AUTOSAR XML (schema 00047)
standard types defined: boolean, uint16, uint32, uint8
package /Application/AdaptiveApplicationSwComponentTypes
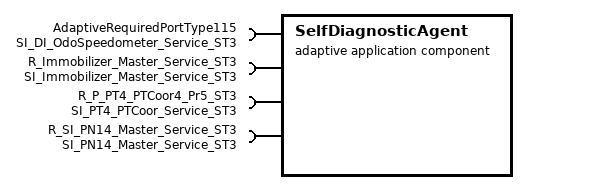
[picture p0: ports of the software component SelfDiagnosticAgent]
  adaptive application sw component type SelfDiagnosticAgent
    4 x require port:
      AdaptiveRequiredPortType115: required-interface=SI_DI_OdoSpeedometer_Service_ST3
      R_Immobilizer_Master_Service_ST3: required-interface=SI_Immobilizer_Master_Service_ST3
      R_P_PT4_PTCoor4_Pr5_ST3: required-interface=SI_PT4_PTCoor_Service_ST3
      R_SI_PN14_Master_Service_ST3: required-interface=SI_PN14_Master_Service_ST3
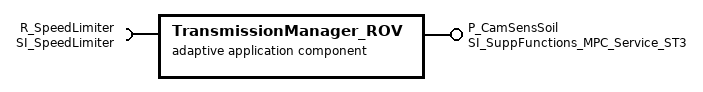
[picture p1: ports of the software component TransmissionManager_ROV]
  adaptive application sw component type TransmissionManager_ROV
    provide port P_CamSensSoil: provided-interface=SI_SuppFunctions_MPC_Service_ST3
    require port R_SpeedLimiter: required-interface=SI_SpeedLimiter
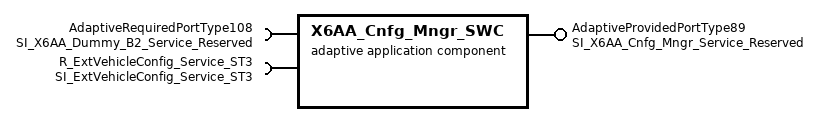
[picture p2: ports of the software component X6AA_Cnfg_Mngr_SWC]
  adaptive application sw component type X6AA_Cnfg_Mngr_SWC
    provide port AdaptiveProvidedPortType89: provided-interface=SI_X6AA_Cnfg_Mngr_Service_Reserved
    require port AdaptiveRequiredPortType108: required-interface=SI_X6AA_Dummy_B2_Service_Reserved
    require port R_ExtVehicleConfig_Service_ST3: required-interface=SI_ExtVehicleConfig_Service_ST3
  adaptive application sw component type X6AA_DLT_SWC
  adaptive application sw component type X6AA_Dummy_SWC_1
    require port AdaptiveRequiredPortType110: required-interface=SI_X6AA_Cnfg_Mngr_Service_Reserved
  adaptive application sw component type X6AA_Dummy_SWC_2
    provide port AdaptiveProvidedPortType90: provided-interface=SI_X6AA_Dummy_B2_Service_Reserved
  adaptive application sw component type X6AA_Ressource_SWC
package /Application/Executables
  7 x executable, all with category=APPLICATION_LEVEL, build-type=BUILD-TYPE-DEBUG, version=1.00.00.0000:
    SelfDiagnosticAgentExecutable
      root sw component prototype SelfDiagnosticAgentExecutableRootSwc: application-type=SelfDiagnosticAgent
    TransmissionManager_ROVExecutable
      root sw component prototype TransmissionManager_ROVExecutableRootSwc: application-type=TransmissionManager_ROV
    X6AA_Cnfg_Mngr_Executable
      root sw component prototype X6AA_Cnfg_Mngr_ExecutableRootSwc: application-type=X6AA_Cnfg_Mngr_SWC
    X6AA_DLT_Executable
      root sw component prototype X6AA_DLT_ExecutableRootSwc: application-type=X6AA_DLT_SWC
    X6AA_Dummy_SWC_1_Executable
      root sw component prototype X6AA_Dummy_SWC_1_ExecutableRootSwc: application-type=X6AA_Dummy_SWC_1
    X6AA_Dummy_SWC_2_Executable
      root sw component prototype X6AA_Dummy_SWC_2_ExecutableRootSwc: application-type=X6AA_Dummy_SWC_2
    X6AA_Ressource_Executable
      root sw component prototype X6AA_Ressource_ExecutableRootSwc: application-type=X6AA_Ressource_SWC
package /ApplicationDeployment/Processes
  7 x process, all with state-dependent-startup-config{function-group-state=MachineState.Running, startup-config=STARTUP_CONFIG_DEFAULT}:
    Process_X6AA_Cnfg_Mngr_SWC: executable=X6AA_Cnfg_Mngr_Executable
      process state machine MDGE_Process_X6AA_Cnfg_Mngr_SWC: type=MachineStates
    Process_X6AA_DLT_SWC: executable=X6AA_DLT_Executable
      process state machine MDGE_Process_X6AA_DLT_SWC: type=MachineStates
    Process_X6AA_Dummy_SWC_1: executable=X6AA_Dummy_SWC_1_Executable
      process state machine MDGE_Process_X6AA_Dummy_SWC_1: type=MachineStates
    Process_X6AA_Dummy_SWC_2: executable=X6AA_Dummy_SWC_2_Executable
      process state machine MDGE_Process_X6AA_Dummy_SWC_2: type=MachineStates
    Process_X6AA_Ressource_SWC: executable=X6AA_Ressource_Executable
      process state machine MDGE_Process_X6AA_Ressource_SWC: type=MachineStates
    SelfDiagnosticAgent: executable=SelfDiagnosticAgentExecutable
      process state machine MDGE_SelfDiagnosticAgent: type=MachineStates
    TransmissionManager_ROV: executable=TransmissionManager_ROVExecutable
      process state machine ProcessStateMachine_BaseApplication: type=MachineStates
package /ApplicationDeployment/ProcessDesigns
  7 x process design:
    ProcessDesign_X6AA_Cnfg_Mngr_SWC: executable=X6AA_Cnfg_Mngr_Executable
    ProcessDesign_X6AA_Dummy_SWC_1: executable=X6AA_Dummy_SWC_1_Executable
    ProcessDesign__X6AA_Dummy_SWC_2: executable=X6AA_Dummy_SWC_2_Executable
    ProcessDesign_SelfDiagnosticAgent: executable=SelfDiagnosticAgentExecutable
    ProcessDesign_TransmissionManager_ROV: executable=TransmissionManager_ROVExecutable
    ProcessDesign_X6AA_DLT_SWC: executable=X6AA_DLT_Executable
    ProcessDesign_X6AA_Ressource_SWC: executable=X6AA_Ressource_Executable
package /Communication/PDUs
  pdu CamSensSoil_MPC_ST3: length=1, unused-bit-pattern=255  # Cam Sens Soil MPC ST3
    signal CamSensSoil_CMS_IconDisp_Rq_MPC_ST3: start 0, 1 bit, little-endian, data-type-policy=OVERRIDE, i-signal-type=PRIMITIVE, compu {0=I_C01_CAMSENSSOIL_CMS_ICONDISP_RQ_IDLE (IDLE) (No display request), 1=I_C01_CAMSENSSOIL_CMS_ICONDISP_RQ_MSG_RQ_CAM_SOILED_CMS_NA (MSG_RQ_CAM_SOILED_CMS_NA) (Message request Camera soiled CMS not available)}, range raw 0..1 "01_CamSensSoil_CMS_IconDisp_Rq"  # Camera Soiled, CMS not available Icon
    signal CamSensSoil_IHC_IconDisp_Rq_MPC_ST3: start 1, 1 bit, little-endian, data-type-policy=OVERRIDE, i-signal-type=PRIMITIVE, compu {0=I_C01_CAMSENSSOIL_IHC_ICONDISP_RQ_IDLE (IDLE) (No display request), 1=I_C01_CAMSENSSOIL_IHC_ICONDISP_RQ_MSG_RQ_CAM_SOILED_IHC_NA (MSG_RQ_CAM_SOILED_IHC_NA) (Message request Camera soiled IHC not available)}, range raw 0..1 "01_CamSensSoil_IHC_IconDisp_Rq"  # Camera Soiled, IHC not available Icon
    signal CamSensSoil_LDP_IconDisp_Rq_MPC_ST3: start 2, 1 bit, little-endian, data-type-policy=OVERRIDE, i-signal-type=PRIMITIVE, compu {0=I_C01_CAMSENSSOIL_LDP_ICONDISP_RQ_IDLE (IDLE) (No display request), 1=I_C01_CAMSENSSOIL_LDP_ICONDISP_RQ_MSG_RQ_CAM_SOILED_LDP_NA (MSG_RQ_CAM_SOILED_LDP_NA) (Message request Camera soiled LDP not available)}, range raw 0..1 "01_CamSensSoil_LDP_IconDisp_Rq"  # Camera Soiled, LDP not available Icon
    signal CamSensSoil_MsgDisp_Rq_MPC_ST3: start 3, 1 bit, little-endian, data-type-policy=OVERRIDE, i-signal-type=PRIMITIVE, compu {0=I_C01_CAMSENSSOIL_MSGDISP_RQ_IDLE (IDLE) (No display request), 1=I_C01_CAMSENSSOIL_MSGDISP_RQ_MSG_RQ_CAM_SOILED (MSG_RQ_CAM_SOILED) (Message request Camera Soiled)}, range raw 0..1 "01_CamSensSoil_MsgDisp_Rq"  # Message "Camera Soiled" with Icons
    signal CamSensSoil_TSA_IconDisp_Rq_MPC_ST3: start 4, 1 bit, little-endian, data-type-policy=OVERRIDE, i-signal-type=PRIMITIVE, compu {0=I_C01_CAMSENSSOIL_TSA_ICONDISP_RQ_IDLE (IDLE) (No display request), 1=I_C01_CAMSENSSOIL_TSA_ICONDISP_RQ_MSG_RQ_CAM_SOILED_TSA_NA (MSG_RQ_CAM_SOILED_TSA_NA) (Message request Camera soiled TSA not available)}, range raw 0..1 "01_CamSensSoil_TSA_IconDisp_Rq"  # Camera Soiled,TSA not available Icon
    mapping CamSensSoil_MPC_ST3_arrjrmhd69107z3r1gztlanxq: i-signal-group=CamSensSoil_MPC_ST3_arrjrmhd69107z3r1gztlanxq, transfer-property=PENDING
    mapping CarWashMd_MPC_SMPC_Stat_ST3: transfer-property=PENDING
  pdu DAP_StWhl_Ctrl_ST3: length=8, minimum-delay=0.02, unused-bit-pattern=255  # DriverAssistancePackage Steering Wheel Controls
    signal CRC_StWhl_Sw_CruiseCtrl_VSL_Stat_Pr5_ST3: start 0, 16 bit, little-endian, data-type-policy=OVERRIDE, i-signal-type=PRIMITIVE, base-type=uint16, range raw 0..65535 "16_CRC_w/oSNA", transfer-property=PENDING  # CRC-checksum of signal group according to AUTOSAR Profile 5
    signal SQC_StWhl_Sw_CruiseCtrl_VSL_Stat_Pr5_ST3: start 16, 8 bit, little-endian, data-type-policy=OVERRIDE, i-signal-type=PRIMITIVE, base-type=uint8, compu {identical}, range phys 0..255 "08_0-255_1_SNA=-", transfer-property=PENDING  # Sequence counter
    signal StWhl_Sw_CruiseCtrl_Select_Psd_ST3: start 24, 2 bit, little-endian, data-type-policy=OVERRIDE, i-signal-type=PRIMITIVE, base-type=uint8, invalid-value=3, compu-method=c02_NPsd_Psd_Flt, range raw 0..3 "02_NPsd_Psd_Flt", transfer-property=TRIGGERED-ON-CHANGE  # Steering wheel tip switch "Cruise Control selected" pressed
    signal StWhl_Sw_VSL_Select_Psd_ST3: start 26, 2 bit, little-endian, data-type-policy=OVERRIDE, i-signal-type=PRIMITIVE, base-type=uint8, invalid-value=3, compu-method=c02_NPsd_Psd_Flt, range raw 0..3 "02_NPsd_Psd_Flt", transfer-property=TRIGGERED-ON-CHANGE  # Steering wheel tip switch "Variable Speed Limiter selected" switch pressed
    signal StWhl_Sw_CruiseCtrl_Off_Psd_ST3: start 28, 2 bit, little-endian, data-type-policy=OVERRIDE, i-signal-type=PRIMITIVE, base-type=uint8, invalid-value=3, compu-method=c02_NPsd_Psd_Flt, range raw 0..3 "02_NPsd_Psd_Flt", transfer-property=TRIGGERED-ON-CHANGE  # Steering wheel tip switch "Cruise Control off" pressed
    signal StWhl_Sw_VSL_Off_Psd_ST3: start 30, 2 bit, little-endian, data-type-policy=OVERRIDE, i-signal-type=PRIMITIVE, base-type=uint8, invalid-value=3, compu-method=c02_NPsd_Psd_Flt, range raw 0..3 "02_NPsd_Psd_Flt", transfer-property=TRIGGERED-ON-CHANGE  # Steering wheel tip switch "Variable Speed Limiter off" pressed
    signal StWhl_Sw_Mode_Psd_ST3: start 32, 2 bit, little-endian, data-type-policy=OVERRIDE, i-signal-type=PRIMITIVE, base-type=uint8, invalid-value=3, compu-method=c02_NPsd_Psd_Flt, range raw 0..3 "02_NPsd_Psd_Flt", transfer-property=TRIGGERED-ON-CHANGE  # Steering wheel tip switch Mode pressed
    signal StWhl_Sw_Resume_Psd_ST3: start 34, 2 bit, little-endian, data-type-policy=OVERRIDE, i-signal-type=PRIMITIVE, base-type=uint8, invalid-value=3, compu-method=c02_NPsd_Psd_Flt, range raw 0..3 "02_NPsd_Psd_Flt", transfer-property=TRIGGERED-ON-CHANGE  # Steering wheel tip switch Resume pressed
    signal StWhl_Sw_Cancel_Psd_ST3: start 36, 2 bit, little-endian, data-type-policy=OVERRIDE, i-signal-type=PRIMITIVE, base-type=uint8, invalid-value=3, compu-method=c02_NPsd_Psd_Flt, range raw 0..3 "02_NPsd_Psd_Flt", transfer-property=TRIGGERED-ON-CHANGE  # Steering wheel tip switch Cancel pressed
    signal StWhl_Sw_Dist_Tgl_Psd_ST3: start 38, 2 bit, little-endian, data-type-policy=OVERRIDE, i-signal-type=PRIMITIVE, base-type=uint8, invalid-value=3, compu-method=c02_NPsd_Psd_Flt, range raw 0..3 "02_NPsd_Psd_Flt", transfer-property=TRIGGERED-ON-CHANGE  # Steering wheel tip switch Distance Toggle pressed
    signal StWhl_Sw_Dist_Plus_Psd_ST3: start 40, 2 bit, little-endian, data-type-policy=OVERRIDE, i-signal-type=PRIMITIVE, base-type=uint8, invalid-value=3, compu-method=c02_NPsd_Psd_Flt, range raw 0..3 "02_NPsd_Psd_Flt", transfer-property=TRIGGERED-ON-CHANGE  # Steering wheel tip switch Distance Plus pressed
    signal StWhl_Sw_Dist_Minus_Psd_ST3: start 42, 2 bit, little-endian, data-type-policy=OVERRIDE, i-signal-type=PRIMITIVE, base-type=uint8, invalid-value=3, compu-method=c02_NPsd_Psd_Flt, range raw 0..3 "02_NPsd_Psd_Flt", transfer-property=TRIGGERED-ON-CHANGE  # Steering wheel tip switch Mode pressed
    signal StWhl_Sw_Up10_Set_Psd_ST3: start 44, 2 bit, little-endian, data-type-policy=OVERRIDE, i-signal-type=PRIMITIVE, base-type=uint8, invalid-value=3, compu-method=c02_NPsd_Psd_Flt, range raw 0..3 "02_NPsd_Psd_Flt", transfer-property=TRIGGERED-ON-CHANGE  # Steering wheel tip switch Set Speed 10 Up pressed
    signal StWhl_Sw_Up1_Psd_ST3: start 46, 2 bit, little-endian, data-type-policy=OVERRIDE, i-signal-type=PRIMITIVE, base-type=uint8, invalid-value=3, compu-method=c02_NPsd_Psd_Flt, range raw 0..3 "02_NPsd_Psd_Flt", transfer-property=TRIGGERED-ON-CHANGE  # Steering wheel tip switch "+1" pressed
    signal StWhl_Sw_Dn1_Psd_ST3: start 48, 2 bit, little-endian, data-type-policy=OVERRIDE, i-signal-type=PRIMITIVE, base-type=uint8, invalid-value=3, compu-method=c02_NPsd_Psd_Flt, range raw 0..3 "02_NPsd_Psd_Flt", transfer-property=TRIGGERED-ON-CHANGE  # Steering wheel tip switch "-1" pressed
    signal StWhl_Sw_Dn10_Set_Psd_ST3: start 50, 2 bit, little-endian, data-type-policy=OVERRIDE, i-signal-type=PRIMITIVE, base-type=uint8, invalid-value=3, compu-method=c02_NPsd_Psd_Flt, range raw 0..3 "02_NPsd_Psd_Flt", transfer-property=TRIGGERED-ON-CHANGE  # Steering wheel tip switch Set Speed 10 Down pressed
    signal StWhl_Sw_HAD1_Psd_ST3: start 52, 2 bit, little-endian, data-type-policy=OVERRIDE, i-signal-type=PRIMITIVE, base-type=uint8, invalid-value=3, compu-method=c02_NPsd_Psd_Flt, range raw 0..3 "02_NPsd_Psd_Flt", transfer-property=TRIGGERED-ON-CHANGE  # Steering wheel tip switch HAD1 pressed
    signal StWhl_Sw_HAD2_Psd_ST3: start 54, 2 bit, little-endian, data-type-policy=OVERRIDE, i-signal-type=PRIMITIVE, base-type=uint8, invalid-value=3, compu-method=c02_NPsd_Psd_Flt, range raw 0..3 "02_NPsd_Psd_Flt", transfer-property=TRIGGERED-ON-CHANGE  # Steering wheel tip switch HAD2 pressed
    signal StWhl_Sw_Up1Dn1_StepSize_ST3: start 56, 3 bit, little-endian, data-type-policy=OVERRIDE, i-signal-type=PRIMITIVE, base-type=uint8, invalid-value=7, compu {0=I_CSTWHL_SW_UP1DN1_STEPSIZE_ST3_STEP_SIZE_1 (STEP_SIZE_1) (StepSize=1), 1=I_CSTWHL_SW_UP1DN1_STEPSIZE_ST3_STEP_SIZE_2 (STEP_SIZE_2) (StepSize Level 2), 2=I_CSTWHL_SW_UP1DN1_STEPSIZE_ST3_STEP_SIZE_3 (STEP_SIZE_3) (StepSize Level 3), 3=I_CSTWHL_SW_UP1DN1_STEPSIZE_ST3_STEP_SIZE_4 (STEP_SIZE_4) (StepSize Level 4), 4=I_CSTWHL_SW_UP1DN1_STEPSIZE_ST3_STEP_SIZE_5 (STEP_SIZE_5) (StepSize Level 5), 7=I_CSTWHL_SW_UP1DN1_STEPSIZE_ST3_SNA (SNA) (SNA value from data type)}, range raw 0..7 "03_StWhl_Sw_Up1Dn1_StepSize_ST3", transfer-property=PENDING  # Step size switch “+/-1”
    signal Rsrv1_StWhl_Sw_CruiseCtrl_VSL_Stat_Pr5_ST3: start 59, 5 bit, little-endian, data-type-policy=OVERRIDE, i-signal-type=PRIMITIVE, base-type=uint8, invalid-value=31, range raw 0..31, transfer-property=PENDING  # Reserved for future use
    mapping StWhl_Sw_CruiseCtrl_VSL_Stat_Pr5_ST3: i-signal-group=StWhl_Sw_CruiseCtrl_VSL_Stat_Pr5_ST3, transfer-property=TRIGGERED-ON-CHANGE
  pdu DI_OdoSpeedometer_ST3: length=8, minimum-delay=0.1, unused-bit-pattern=255  # DriverInformation Odometer and speedometer
    signal Odo_ST3: start 24, 24 bit, little-endian, data-type-policy=OVERRIDE, i-signal-type=PRIMITIVE, base-type=uint32, invalid-value=16777215, compu {phys=raw*0.1 for raw 0..9999999, 16777214=I_C24_KM_0_999999K9_0K1_INVLD_SNA_INVLD (INVLD) (Invalid), 16777215=I_C24_KM_0_999999K9_0K1_INVLD_SNA_SNA (SNA) (SNA value from data type); unit km}, range phys 0..1677721.5, raw 0..16777215 "24_km_0-999999,9_0,1_Invld_SNA", to IDC_Adpative  # Odometer (for everyone)
    mapping CRC_DI_Odo_Pr5_ST3: transfer-property=PENDING
    mapping DI_Odo_Pr5_ST3_e68xmtlkywxgxsdwekdjjhw3t: i-signal-group=DI_Odo_Pr5_ST3_e68xmtlkywxgxsdwekdjjhw3t, transfer-property=TRIGGERED-ON-CHANGE
    mapping SQC_DI_Odo_Pr5_ST3: transfer-property=PENDING
    mapping VehSpd_Disp_ST3: transfer-property=TRIGGERED-ON-CHANGE
  pdu EVC_CfgBit_01_26_Pr5_ST3: length=8, unused-bit-pattern=255  # EVC-CfgMessage[Bitfield:01h-26h]
    signal CRC_EVC_CfgBit_01_26_Pr5_ST3: start 0, 16 bit, little-endian, data-type-policy=OVERRIDE, i-signal-type=PRIMITIVE, data-constr=c16_CRC_woSNA, to IDC_Adpative  # CRC-checksum of signal group according to AUTOSAR Profile 5
    signal SQC_EVC_CfgBit_01_26_Pr5_ST3: start 16, 8 bit, little-endian, data-type-policy=OVERRIDE, i-signal-type=PRIMITIVE, compu {identical}, data-constr=c08_0_255_1_SNA_na, to IDC_Adpative  # Sequence counter
    signal EVC_CfgBit_01_26_Stat_ST3: start 24, 2 bit, little-endian, data-type-policy=OVERRIDE, i-signal-type=PRIMITIVE, invalid-value=3, compu-method=c02_EVC_Stat, data-constr=c02_EVC_Stat, to IDC_Adpative  # Status EVC-CfgMessage[Bitfield:01h-26h]
    signal EVC_01_494_Avl_ST3: start 26, 1 bit, little-endian, data-type-policy=OVERRIDE, i-signal-type=PRIMITIVE, to IDC_Adpative  # 494 VERSION FOR USA
    signal EVC_02_498_Avl_ST3: start 27, 1 bit, little-endian, data-type-policy=OVERRIDE, i-signal-type=PRIMITIVE, to IDC_Adpative  # 498 VERSION FOR JAPAN
    signal EVC_03_623_Avl_ST3: start 28, 1 bit, little-endian, data-type-policy=OVERRIDE, i-signal-type=PRIMITIVE, to IDC_Adpative  # 623 VERSION FOR GULF STATES
    signal EVC_04_625_Avl_ST3: start 29, 1 bit, little-endian, data-type-policy=OVERRIDE, i-signal-type=PRIMITIVE, to IDC_Adpative  # 625 VERSION FOR AUSTRALIA
    signal EVC_05_830_Avl_ST3: start 30, 1 bit, little-endian, data-type-policy=OVERRIDE, i-signal-type=PRIMITIVE, to IDC_Adpative  # 830 VEHICLES FOR CHINA-ADDITIONAL PARTS
    signal EVC_06_835_Avl_ST3: start 31, 1 bit, little-endian, data-type-policy=OVERRIDE, i-signal-type=PRIMITIVE, to IDC_Adpative  # 835 SOUTHERN KOREA-SUPPLEMENTARY PARTS
    signal EVC_07_460_Avl_ST3: start 32, 1 bit, little-endian, data-type-policy=OVERRIDE, i-signal-type=PRIMITIVE, to IDC_Adpative  # 460 VEHICLES FOR CANADA, ADDITIONAL PARTS
    signal EVC_08_AddEquip_Avl_ST3: start 33, 1 bit, little-endian, data-type-policy=OVERRIDE, i-signal-type=PRIMITIVE, to IDC_Adpative  # 08h Additional Equipment (not specialized yet)
    signal EVC_09_AddEquip_Avl_ST3: start 34, 1 bit, little-endian, data-type-policy=OVERRIDE, i-signal-type=PRIMITIVE, to IDC_Adpative  # 09h Additional Equipment (not specialized yet)
    signal EVC_0A_AddEquip_Avl_ST3: start 35, 1 bit, little-endian, data-type-policy=OVERRIDE, i-signal-type=PRIMITIVE, to IDC_Adpative  # 0Ah Additional Equipment (not specialized yet)
    signal EVC_0B_AddEquip_Avl_ST3: start 36, 1 bit, little-endian, data-type-policy=OVERRIDE, i-signal-type=PRIMITIVE, to IDC_Adpative  # 0Bh Additional Equipment (not specialized yet)
    signal EVC_0C_465_Avl_ST3: start 37, 1 bit, little-endian, data-type-policy=OVERRIDE, i-signal-type=PRIMITIVE, to IDC_Adpative  # 465 ELEKTRIK AKTIV ROLL STABILISATION (EARS)
    signal EVC_0D_470_Avl_ST3: start 38, 1 bit, little-endian, data-type-policy=OVERRIDE, i-signal-type=PRIMITIVE, to IDC_Adpative  # 470 SEMI-ACTIVE ROLL STABILIZATION
    signal EVC_0E_479_Avl_ST3: start 39, 1 bit, little-endian, data-type-policy=OVERRIDE, i-signal-type=PRIMITIVE, to IDC_Adpative  # 479 ADJUSTING SUSPENSION
    signal EVC_0F_AddEquip_Avl_ST3: start 40, 1 bit, little-endian, data-type-policy=OVERRIDE, i-signal-type=PRIMITIVE, to IDC_Adpative  # 0Fh Additional Equipment (not specialized yet)
    signal EVC_10_AddEquip_Avl_ST3: start 41, 1 bit, little-endian, data-type-policy=OVERRIDE, i-signal-type=PRIMITIVE, to IDC_Adpative  # 10h Additional Equipment (not specialized yet)
    signal EVC_11_AddEquip_Avl_ST3: start 42, 1 bit, little-endian, data-type-policy=OVERRIDE, i-signal-type=PRIMITIVE, to IDC_Adpative  # 11h Additional Equipment (not specialized yet)
    signal EVC_12_AddEquip_Avl_ST3: start 43, 1 bit, little-endian, data-type-policy=OVERRIDE, i-signal-type=PRIMITIVE, to IDC_Adpative  # 12h Additional Equipment (not specialized yet)
    signal EVC_13_AddEquip_Avl_ST3: start 44, 1 bit, little-endian, data-type-policy=OVERRIDE, i-signal-type=PRIMITIVE, to IDC_Adpative  # 13h Additional Equipment (not specialized yet)
    signal EVC_14_M035_Avl_ST3: start 45, 1 bit, little-endian, data-type-policy=OVERRIDE, i-signal-type=PRIMITIVE, to IDC_Adpative  # M035 ALLROAD-VARIANT
    signal EVC_15_MED2_Avl_ST3: start 46, 1 bit, little-endian, data-type-policy=OVERRIDE, i-signal-type=PRIMITIVE, to IDC_Adpative  # MED2 UPPER-MID-VARIANTE MIT M-BATTERIE
    signal EVC_16_M013_Avl_ST3: start 47, 1 bit, little-endian, data-type-policy=OVERRIDE, i-signal-type=PRIMITIVE, to IDC_Adpative  # M013 ENGINE REDUCED PERFORMANCE
    signal EVC_17_M014_Avl_ST3: start 48, 1 bit, little-endian, data-type-policy=OVERRIDE, i-signal-type=PRIMITIVE, to IDC_Adpative  # M014 ENGINE INCREASED PERFORMANCE
    signal EVC_18_M016_Avl_ST3: start 49, 1 bit, little-endian, data-type-policy=OVERRIDE, i-signal-type=PRIMITIVE, to IDC_Adpative  # M016 ENGINE HIGH PERFORMANCE INCREASED
    signal EVC_19_M005_Avl_ST3: start 50, 1 bit, little-endian, data-type-policy=OVERRIDE, i-signal-type=PRIMITIVE, to IDC_Adpative  # M005 CHASSIS WITH 4-MATIC-/ALL-WHEEL DRIVE
    signal EVC_1A_AddEquip_Avl_ST3: start 51, 1 bit, little-endian, data-type-policy=OVERRIDE, i-signal-type=PRIMITIVE, to IDC_Adpative  # 1Ah Additional Equipment (not specialized yet)
    signal EVC_1B_MEF2_Avl_ST3: start 52, 1 bit, little-endian, data-type-policy=OVERRIDE, i-signal-type=PRIMITIVE, to IDC_Adpative  # MEF2 AMG-ENTRY-VARIANTE MIT M-BATTERIE + 4MATIC
    signal EVC_1C_MEF3_Avl_ST3: start 53, 1 bit, little-endian, data-type-policy=OVERRIDE, i-signal-type=PRIMITIVE, to IDC_Adpative  # MEF3 AMG-ENTRY-VARIANTE MIT L-BATTERIE + 4MATIC
    signal EVC_1D_201_Avl_ST3: start 54, 1 bit, little-endian, data-type-policy=OVERRIDE, i-signal-type=PRIMITIVE, to IDC_Adpative  # 201 REAR AXLE STEERING
    signal EVC_1E_216_Avl_ST3: start 55, 1 bit, little-endian, data-type-policy=OVERRIDE, i-signal-type=PRIMITIVE, to IDC_Adpative  # 216 REAR AXLE STEERING WITH LARGE ANGLE
    signal EVC_1F_215_Avl_ST3: start 56, 1 bit, little-endian, data-type-policy=OVERRIDE, i-signal-type=PRIMITIVE, to IDC_Adpative  # 215 ADAPTIVE DAMPING SYSTEM PLUS (ADS+)
    signal EVC_20_487_Avl_ST3: start 57, 1 bit, little-endian, data-type-policy=OVERRIDE, i-signal-type=PRIMITIVE, to IDC_Adpative  # 487 ABC-SPRING (ACTIVE BODY CONTROL)
    signal EVC_21_488_Avl_ST3: start 58, 1 bit, little-endian, data-type-policy=OVERRIDE, i-signal-type=PRIMITIVE, to IDC_Adpative  # 488 CHASSIS WITH STEEL-/AIR SUSPENSION
    signal EVC_22_489_Avl_ST3: start 59, 1 bit, little-endian, data-type-policy=OVERRIDE, i-signal-type=PRIMITIVE, to IDC_Adpative  # 489 AIRMATIC DUAL CONTROL / AIR SUSPENSION SEMI-ACTIVE
    signal EVC_23_490_Avl_ST3: start 60, 1 bit, little-endian, data-type-policy=OVERRIDE, i-signal-type=PRIMITIVE, to IDC_Adpative  # 490 ELEKTROHYDRAULISCHE FEDERUNG
    signal EVC_24_486_Avl_ST3: start 61, 1 bit, little-endian, data-type-policy=OVERRIDE, i-signal-type=PRIMITIVE, to IDC_Adpative  # 486 SPORTS SUSPENSION
    signal EVC_25_AddEquip_Avl_ST3: start 62, 1 bit, little-endian, data-type-policy=OVERRIDE, i-signal-type=PRIMITIVE, to IDC_Adpative  # 25h Additional Equipment (not specialized yet)
    signal EVC_26_459_Avl_ST3: start 63, 1 bit, little-endian, data-type-policy=OVERRIDE, i-signal-type=PRIMITIVE, to IDC_Adpative  # 459 STEEL SPRING WITH ADJUSTABLE INSULATION
    mapping EVC_CfgBit_01_26_Pr5_ST3_fblv727rnlh4ltr0dm5mnkvh: i-signal-group=EVC_CfgBit_01_26_Pr5_ST3_fblv727rnlh4ltr0dm5mnkvh, transfer-property=PENDING
  pdu EVC_CfgBit_73_98_Pr5_ST3: length=8, unused-bit-pattern=255  # EVC-CfgMessage[Bitfield:73h-98h]
    signal CRC_EVC_CfgBit_73_98_Pr5_ST3: start 0, 16 bit, little-endian, data-type-policy=OVERRIDE, i-signal-type=PRIMITIVE, data-constr=c16_CRC_woSNA, to IDC_Adpative  # CRC-checksum of signal group according to AUTOSAR Profile 5
    signal SQC_EVC_CfgBit_73_98_Pr5_ST3: start 16, 8 bit, little-endian, data-type-policy=OVERRIDE, i-signal-type=PRIMITIVE, compu {identical}, data-constr=c08_0_255_1_SNA_na, to IDC_Adpative  # Sequence counter
    signal EVC_CfgBit_73_98_Stat_ST3: start 24, 2 bit, little-endian, data-type-policy=OVERRIDE, i-signal-type=PRIMITIVE, invalid-value=3, compu-method=c02_EVC_Stat, data-constr=c02_EVC_Stat, to IDC_Adpative  # Status EVC-CfgMessage[Bitfield:73h-98h]
    signal EVC_73_501_Avl_ST3: start 26, 1 bit, little-endian, data-type-policy=OVERRIDE, i-signal-type=PRIMITIVE, to IDC_Adpative  # 501 SURROUND VIEW SYSTEM
    signal EVC_74_476_Avl_ST3: start 27, 1 bit, little-endian, data-type-policy=OVERRIDE, i-signal-type=PRIMITIVE, to IDC_Adpative  # 476 AUTO. LANE RECOGNITION (CONDITION ASSISTENT)
    signal EVC_75_AddEquip_Avl_ST3: start 28, 1 bit, little-endian, data-type-policy=OVERRIDE, i-signal-type=PRIMITIVE, to IDC_Adpative  # 75h Additional Equipment (not specialized yet)
    signal EVC_76_513_Avl_ST3: start 29, 1 bit, little-endian, data-type-policy=OVERRIDE, i-signal-type=PRIMITIVE, to IDC_Adpative  # 513 ROAD SIGN DETECTION (SLA)
    signal EVC_77_299_Avl_ST3: start 30, 1 bit, little-endian, data-type-policy=OVERRIDE, i-signal-type=PRIMITIVE, to IDC_Adpative  # 299 PRESAFE
    signal EVC_78_306_Avl_ST3: start 31, 1 bit, little-endian, data-type-policy=OVERRIDE, i-signal-type=PRIMITIVE, to IDC_Adpative  # 306 REAR BELTBAG
    signal EVC_79_AddEquip_Avl_ST3: start 32, 1 bit, little-endian, data-type-policy=OVERRIDE, i-signal-type=PRIMITIVE, to IDC_Adpative  # 79h Additional Equipment (not specialized yet)
    signal EVC_7A_AddEquip_Avl_ST3: start 33, 1 bit, little-endian, data-type-policy=OVERRIDE, i-signal-type=PRIMITIVE, to IDC_Adpative  # 7Ah Additional Equipment (not specialized yet)
    signal EVC_7B_551_Avl_ST3: start 34, 1 bit, little-endian, data-type-policy=OVERRIDE, i-signal-type=PRIMITIVE, to IDC_Adpative  # 551 THEFT WARNING SYSTEM
    signal EVC_7C_503_Avl_ST3: start 35, 1 bit, little-endian, data-type-policy=OVERRIDE, i-signal-type=PRIMITIVE, to IDC_Adpative  # 503 REMOTE PARKING
    signal EVC_7D_220_Avl_ST3: start 36, 1 bit, little-endian, data-type-policy=OVERRIDE, i-signal-type=PRIMITIVE, to IDC_Adpative  # 220 PARKTRONIC SYSTEM (PTS)
    signal EVC_7E_218_Avl_ST3: start 37, 1 bit, little-endian, data-type-policy=OVERRIDE, i-signal-type=PRIMITIVE, to IDC_Adpative  # 218 REVERSING CAMERA
    signal EVC_7F_235_Avl_ST3: start 38, 1 bit, little-endian, data-type-policy=OVERRIDE, i-signal-type=PRIMITIVE, to IDC_Adpative  # 235 ACTIVE PARKING ASSISTANCE
    signal EVC_80_AddEquip_Avl_ST3: start 39, 1 bit, little-endian, data-type-policy=OVERRIDE, i-signal-type=PRIMITIVE, to IDC_Adpative  # 80h Additional Equipment (not specialized yet)
    signal EVC_81_AddEquip_Avl_ST3: start 40, 1 bit, little-endian, data-type-policy=OVERRIDE, i-signal-type=PRIMITIVE, to IDC_Adpative  # 81h Additional Equipment (not specialized yet)
    signal EVC_82_440_Avl_ST3: start 41, 1 bit, little-endian, data-type-policy=OVERRIDE, i-signal-type=PRIMITIVE, to IDC_Adpative  # 440 CRUISE CONTROL
    signal EVC_83_AddEquip_Avl_ST3: start 42, 1 bit, little-endian, data-type-policy=OVERRIDE, i-signal-type=PRIMITIVE, to IDC_Adpative  # 83h Additional Equipment (not specialized yet)
    signal EVC_84_504_Avl_ST3: start 43, 1 bit, little-endian, data-type-policy=OVERRIDE, i-signal-type=PRIMITIVE, to IDC_Adpative  # 504 SPEED SIGN RECOGNITON
    signal EVC_85_27U_Avl_ST3: start 44, 1 bit, little-endian, data-type-policy=OVERRIDE, i-signal-type=PRIMITIVE, to IDC_Adpative  # 27U AUTOMATED VALET PARKING
    signal EVC_86_K00_Avl_ST3: start 45, 1 bit, little-endian, data-type-policy=OVERRIDE, i-signal-type=PRIMITIVE, to IDC_Adpative  # K00 PERIMETER DRIVING ASSISTANCE PACKAGE BASE
    signal EVC_87_200_Avl_ST3: start 46, 1 bit, little-endian, data-type-policy=OVERRIDE, i-signal-type=PRIMITIVE, to IDC_Adpative  # 200 HIGH AUTOMATED DRIVING
    signal EVC_88_384_Avl_ST3: start 47, 1 bit, little-endian, data-type-policy=OVERRIDE, i-signal-type=PRIMITIVE, to IDC_Adpative  # 384 COMMUNICATION MODULE RAMSES HIGH
    signal EVC_89_233_Avl_ST3: start 48, 1 bit, little-endian, data-type-policy=OVERRIDE, i-signal-type=PRIMITIVE, to IDC_Adpative  # 233 ADVANCED DISTRONIC
    signal EVC_8A_234_Avl_ST3: start 49, 1 bit, little-endian, data-type-policy=OVERRIDE, i-signal-type=PRIMITIVE, to IDC_Adpative  # 234 BLIND SPOT-ASSISTANT
    signal EVC_8B_292_Avl_ST3: start 50, 1 bit, little-endian, data-type-policy=OVERRIDE, i-signal-type=PRIMITIVE, to IDC_Adpative  # 292 PRE-SAFE IMPULSE SIDE
    signal EVC_8C_243_Avl_ST3: start 51, 1 bit, little-endian, data-type-policy=OVERRIDE, i-signal-type=PRIMITIVE, to IDC_Adpative  # 243 ACTIVE LANE DEPARTURE-ASSISTANT (CAMERA)
    signal EVC_8D_258_Avl_ST3: start 52, 1 bit, little-endian, data-type-policy=OVERRIDE, i-signal-type=PRIMITIVE, to IDC_Adpative  # 258 FORWARD COLLISION WARN.(FCW) W.ACTIVE BRAKE CONTR.
    signal EVC_8E_239_Avl_ST3: start 53, 1 bit, little-endian, data-type-policy=OVERRIDE, i-signal-type=PRIMITIVE, to IDC_Adpative  # 239 DISTRONIC PRO
    signal EVC_8F_266_Avl_ST3: start 54, 1 bit, little-endian, data-type-policy=OVERRIDE, i-signal-type=PRIMITIVE, to IDC_Adpative  # 266 DISTRONIC PLUS CROSS-ASSISTANCE
    signal EVC_90_546_Avl_ST3: start 55, 1 bit, little-endian, data-type-policy=OVERRIDE, i-signal-type=PRIMITIVE, to IDC_Adpative  # 546 AUTOMATIC SPEED CONTROL
    signal EVC_91_271_Avl_ST3: start 56, 1 bit, little-endian, data-type-policy=OVERRIDE, i-signal-type=PRIMITIVE, to IDC_Adpative  # 271 AUTONOMIC BRAKE-ENGAGEMENT F.PEDESTRIAN PROTECTION
    signal EVC_92_382_Avl_ST3: start 57, 1 bit, little-endian, data-type-policy=OVERRIDE, i-signal-type=PRIMITIVE, to IDC_Adpative  # 382 COMMUNICATIONMODULE RAMSES SUB-ENTRY
    signal EVC_93_383_Avl_ST3: start 58, 1 bit, little-endian, data-type-policy=OVERRIDE, i-signal-type=PRIMITIVE, to IDC_Adpative  # 383 COMMUNICATION MODULE RAMSES ENTRY
    signal EVC_94_K29_Avl_ST3: start 59, 1 bit, little-endian, data-type-policy=OVERRIDE, i-signal-type=PRIMITIVE, to IDC_Adpative  # K29 DEACTIVATION SAR-SYSTEM
    signal EVC_95_AddEquip_Avl_ST3: start 60, 1 bit, little-endian, data-type-policy=OVERRIDE, i-signal-type=PRIMITIVE, to IDC_Adpative  # 95h Additional Equipment (not specialized yet)
    signal EVC_96_430_Avl_ST3: start 61, 1 bit, little-endian, data-type-policy=OVERRIDE, i-signal-type=PRIMITIVE, to IDC_Adpative  # 430 OFFROAD-PACKAGE
    signal EVC_97_950_Avl_ST3: start 62, 1 bit, little-endian, data-type-policy=OVERRIDE, i-signal-type=PRIMITIVE, to IDC_Adpative  # 950 AMG SPORTS PACKAGE
    signal EVC_98_952_Avl_ST3: start 63, 1 bit, little-endian, data-type-policy=OVERRIDE, i-signal-type=PRIMITIVE, to IDC_Adpative  # 952 SPORTS PACKAGE
    mapping EVC_CfgBit_73_98_Pr5_ST3_4xva8cvevi64tljtz3c92ker3: i-signal-group=EVC_CfgBit_73_98_Pr5_ST3_4xva8cvevi64tljtz3c92ker3, transfer-property=PENDING
  pdu EVC_CfgBit_99_BE_Pr5_ST3: length=8, unused-bit-pattern=255  # EVC-CfgMessage[Bitfield:99h-BEh]
    signal EVC_CfgBit_99_BE_Stat_ST3: start 24, 2 bit, little-endian, data-type-policy=OVERRIDE, i-signal-type=PRIMITIVE, invalid-value=3, compu-method=c02_EVC_Stat, data-constr=c02_EVC_Stat, to IDC_Adpative  # Status EVC-CfgMessage[Bitfield:99h-BEh]
    signal EVC_9F_608_Avl_ST3: start 32, 1 bit, little-endian, data-type-policy=OVERRIDE, i-signal-type=PRIMITIVE, to IDC_Adpative  # 608 INTELLIGENT HEADLIGHT CONTROL
    signal EVC_A0_628_Avl_ST3: start 33, 1 bit, little-endian, data-type-policy=OVERRIDE, i-signal-type=PRIMITIVE, to IDC_Adpative  # 628 INTELLIGENT HEADLIGHT CONTROL PLUS (IHC+)
    mapping CRC_EVC_CfgBit_99_BE_Pr5_ST3
    mapping EVC_99_477_Avl_ST3
    mapping EVC_9A_475_Avl_ST3
    mapping EVC_9B_965_Avl_ST3
    mapping EVC_9C_342_Avl_ST3
    mapping EVC_9D_934_Avl_ST3
    mapping EVC_9E_341_Avl_ST3
    mapping EVC_A1_876_Avl_ST3
    mapping EVC_A2_AddEquip_Avl_ST3
    mapping EVC_A3_AddEquip_Avl_ST3
    mapping EVC_A4_896_Avl_ST3
    mapping EVC_A5_864_Avl_ST3
    mapping EVC_A6_866_Avl_ST3
    mapping EVC_A7_U19_Avl_ST3
    mapping EVC_A8_445_Avl_ST3
    mapping EVC_A9_U07_Avl_ST3
    mapping EVC_AA_871_Avl_ST3
    mapping EVC_AB_67B_Avl_ST3
    mapping EVC_AC_68B_Avl_ST3
    mapping EVC_AD_78B_Avl_ST3
    mapping EVC_AE_77B_Avl_ST3
    mapping EVC_AF_562_Avl_ST3
    mapping EVC_B0_236_Avl_ST3
    mapping EVC_B1_854_Avl_ST3
    mapping EVC_B2_447_Avl_ST3
    mapping EVC_B{3..9}_AddEquip_Avl_ST3
    mapping EVC_BA_AddEquip_Avl_ST3
    mapping EVC_BB_AddEquip_Avl_ST3
    mapping EVC_BC_AddEquip_Avl_ST3
    mapping EVC_BD_AddEquip_Avl_ST3
    mapping EVC_BE_AddEquip_Avl_ST3
    mapping EVC_CfgBit_99_BE_Pr5_ST3_cxgi3gf02ijeaizats4f45avn: i-signal-group=EVC_CfgBit_99_BE_Pr5_ST3_cxgi3gf02ijeaizats4f45avn, transfer-property=PENDING
    mapping SQC_EVC_CfgBit_99_BE_Pr5_ST3
  pdu EVC_CfgList_01_08_Pr5_ST3: length=8, unused-bit-pattern=255  # EVC-CfgMessage[Lists:01h-08h]
    signal CRC_EVC_CfgList_01_08_Pr5_ST3: start 0, 16 bit, little-endian, data-type-policy=OVERRIDE, i-signal-type=PRIMITIVE, data-constr=c16_CRC_woSNA, to IDC_Adpative  # CRC-checksum of signal group according to AUTOSAR Profile 5
    signal SQC_EVC_CfgList_01_08_Pr5_ST3: start 16, 8 bit, little-endian, data-type-policy=OVERRIDE, i-signal-type=PRIMITIVE, compu {identical}, data-constr=c08_0_255_1_SNA_na, to IDC_Adpative  # Sequence counter
    signal EVC_CfgList_01_08_Stat_ST3: start 24, 2 bit, little-endian, data-type-policy=OVERRIDE, i-signal-type=PRIMITIVE, invalid-value=3, compu-method=c02_EVC_Stat, data-constr=c02_EVC_Stat, to IDC_Adpative  # Status EVC-CfgMessage[Lists:01h-08h]
    signal EVC_List01_BodyStyle_ST3: start 26, 6 bit, little-endian, data-type-policy=OVERRIDE, i-signal-type=PRIMITIVE, compu {0=I_C06_EVC_BODYSTYLE_ST3_FW (FW) (FW - SEDAN), 1=I_C06_EVC_BODYSTYLE_ST3_FV (FV) (FV - SEDAN ELONGATED), 2=I_C06_EVC_BODYSTYLE_ST3_FC (FC) (FC - COUPE), 3=I_C06_EVC_BODYSTYLE_ST3_FS (FS) (FS - STATION WAGON), 4=I_C06_EVC_BODYSTYLE_ST3_FA (FA) (FA - CABRIOLET), 5=I_C06_EVC_BODYSTYLE_ST3_FR (FR) (FR - ROADSTER), 12=I_C06_EVC_BODYSTYLE_ST3_FT (FT) (FT - TOURER (VAN)), 13=I_C06_EVC_BODYSTYLE_ST3_FX (FX) (FX - SPECIAL VERSION), 15=I_C06_EVC_BODYSTYLE_ST3_FH (FH) (FH - HATCHBACK), 16=I_C06_EVC_BODYSTYLE_ST3_FZ (FZ) (FZ - SPECIAL VERSION), 17=I_C06_EVC_BODYSTYLE_ST3_FN (FN) (FN - NEW ENERGY / SPECIAL VERSION), 63=I_C06_EVC_BODYSTYLE_ST3_OTHER (OTHER) (none of listed variants)}, range raw 0..63 "06_EVC_BodyStyle_ST3", to IDC_Adpative  # Vehicle body style
    signal EVC_List02_VehLine_ST3: start 32, 6 bit, little-endian, data-type-policy=OVERRIDE, i-signal-type=PRIMITIVE, compu {0=I_C06_EVC_VEHLINE_ST3_BR223 (BR223), 1=I_C06_EVC_VEHLINE_ST3_BR231 (BR231), 2=I_C06_EVC_VEHLINE_ST3_BR214 (BR214), 3=I_C06_EVC_VEHLINE_ST3_BR206 (BR206), 4=I_C06_EVC_VEHLINE_ST3_BR222 (BR222), 8=I_C06_EVC_VEHLINE_ST3_BR166 (BR166), 9=I_C06_EVC_VEHLINE_ST3_BR207 (BR207), 10=I_C06_EVC_VEHLINE_ST3_BR463 (BR463), 11=I_C06_EVC_VEHLINE_ST3_BR217 (BR217), 12=I_C06_EVC_VEHLINE_ST3_BR232 (BR232), 13=I_C06_EVC_VEHLINE_ST3_BR213 (BR213), 14=I_C06_EVC_VEHLINE_ST3_BR238 (BR238), 18=I_C06_EVC_VEHLINE_ST3_BR173 (BR173), 19=I_C06_EVC_VEHLINE_ST3_BR167 (BR167), 20=I_C06_EVC_VEHLINE_ST3_BR177 (BR177), 21=I_C06_EVC_VEHLINE_ST3_BR190 (BR190), 23=I_C06_EVC_VEHLINE_ST3_BR257 (BR257), 24=I_C06_EVC_VEHLINE_ST3_BR174 (BR174), 25=I_C06_EVC_VEHLINE_ST3_BR178 (BR178), 26=I_C06_EVC_VEHLINE_ST3_BR244 (BR244), 27=I_C06_EVC_VEHLINE_ST3_BR248 (BR248), 32=I_C06_EVC_VEHLINE_ST3_BR258 (BR258), 34=I_C06_EVC_VEHLINE_ST3_BR290 (BR290), 38=I_C06_EVC_VEHLINE_ST3_BR447 (BR447), 39=I_C06_EVC_VEHLINE_ST3_BR253 (BR253), 40=I_C06_EVC_VEHLINE_ST3_BR292 (BR292), 41=I_C06_EVC_VEHLINE_ST3_BR252 (BR252), 42=I_C06_EVC_VEHLINE_ST3_BR247 (BR247), 43=I_C06_EVC_VEHLINE_ST3_BR118 (BR118), 44=I_C06_EVC_VEHLINE_ST3_BR907 (BR907), 45=I_C06_EVC_VEHLINE_ST3_BR910 (BR910), 46=I_C06_EVC_VEHLINE_ST3_BR470 (BR470), 47=I_C06_EVC_VEHLINE_ST3_BR293 (BR293), 48=I_C06_EVC_VEHLINE_ST3_BR243 (BR243), 49=I_C06_EVC_VEHLINE_ST3_BR298 (BR298), 50=I_C06_EVC_VEHLINE_ST3_BR226 (BR226), 51=I_C06_EVC_VEHLINE_ST3_BR236 (BR236), 52=I_C06_EVC_VEHLINE_ST3_BR239 (BR239), 53=I_C06_EVC_VEHLINE_ST3_BR254 (BR254), 54=I_C06_EVC_VEHLINE_ST3_BR294 (BR294), 55=I_C06_EVC_VEHLINE_ST3_BR295 (BR295), 56=I_C06_EVC_VEHLINE_ST3_BR296 (BR296), 57=I_C06_EVC_VEHLINE_ST3_BR297 (BR297), 63=I_C06_EVC_VEHLINE_ST3_OTHER (OTHER) (none of listed variants)}, range raw 0..63 "06_EVC_VehLine_ST3", to IDC_Adpative  # Vehicle line
    signal EVC_List03_StStyle_ST3: start 38, 2 bit, little-endian, data-type-policy=OVERRIDE, i-signal-type=PRIMITIVE, invalid-value=3, compu {1=I_C02_STSTYLE_LHD (LHD) (Left hand drive), 2=I_C02_STSTYLE_RHD (RHD) (Right hand drive), 3=I_C02_STSTYLE_SNA (SNA) (SNA value from data type)}, range raw 1..3 "02_StStyle", to IDC_Adpative  # Steering variant
    signal EVC_List04_YrOfModf_2_ST3: start 40, 4 bit, little-endian, data-type-policy=OVERRIDE, i-signal-type=PRIMITIVE, compu {0=I_C04_EVC_YROFMODF_2_ST3_YOM050 (YOM050) (050 YEAR OF MODIFICATION 19/2, 29/2, 39/2, 49/2, 59/2), 1=I_C04_EVC_YROFMODF_2_ST3_YOM051 (YOM051) (051 YEAR OF MODIFICATION 20/2, 30/2, 40/2, 50/2, 60/2), 2=I_C04_EVC_YROFMODF_2_ST3_YOM052 (YOM052) (052 YEAR OF MODIFICATION 11/2, 21/2, 31/2, 41/2, 51/2), 3=I_C04_EVC_YROFMODF_2_ST3_YOM053 (YOM053) (053 YEAR OF MODIFICATION 12/2, 22/2, 32/2, 42/2, 52/2), 4=I_C04_EVC_YROFMODF_2_ST3_YOM054 (YOM054) (054 YEAR OF MODIFICATION 13/2, 23/2, 33/2, 43/2, 53/2), 5=I_C04_EVC_YROFMODF_2_ST3_YOM055 (YOM055) (055 YEAR OF MODIFICATION 14/2, 24/2, 34/2, 44/2, 54/2), 6=I_C04_EVC_YROFMODF_2_ST3_YOM056 (YOM056) (056 YEAR OF MODIFICATION 15/2, 25/2, 35/2, 45/2, 55/2), 7=I_C04_EVC_YROFMODF_2_ST3_YOM057 (YOM057) (057 YEAR OF MODIFICATION 16/2, 26/2, 36/2, 46/2, 56/2), 8=I_C04_EVC_YROFMODF_2_ST3_YOM058 (YOM058) (058 YEAR OF MODIFICATION 17/2, 27/2, 37/2, 47/2, 57/2), 9=I_C04_EVC_YROFMODF_2_ST3_YOM059 (YOM059) (059 YEAR OF MODIFICATION 18/2, 28/2, 38/2, 48/2, 58/2), 15=I_C04_EVC_YROFMODF_2_ST3_OTHER (OTHER) (none of listed variants)}, range raw 0..15 "04_EVC_YrOfModf_2_ST3", to IDC_Adpative  # Year of Modification YY/2
    signal EVC_List05_YrOfModf_1_ST3: start 44, 4 bit, little-endian, data-type-policy=OVERRIDE, i-signal-type=PRIMITIVE, compu {0=I_C04_EVC_YROFMODF_1_ST3_YOM800 (YOM800) (800 YEAR OF MODIFICATION 19/1, 29/1, 39/1, 49/1, 59/1), 1=I_C04_EVC_YROFMODF_1_ST3_YOM801 (YOM801) (801 YEAR OF MODIFICATION 20/1, 30/1, 40/1, 50/1, 60/1), 2=I_C04_EVC_YROFMODF_1_ST3_YOM802 (YOM802) (802 YEAR OF MODIFICATION 21/1, 31/1, 41/1, 51/1, 61/1), 3=I_C04_EVC_YROFMODF_1_ST3_YOM803 (YOM803) (803 YEAR OF MODIFICATION 12/1, 22/1, 32/1, 42/1, 52/1), 4=I_C04_EVC_YROFMODF_1_ST3_YOM804 (YOM804) (804 YEAR OF MODIFICATION 13/1, 23/1, 33/1, 43/1, 53/1), 5=I_C04_EVC_YROFMODF_1_ST3_YOM805 (YOM805) (805 YEAR OF MODIFICATION 14/1, 24/1, 34/1, 44/1, 54/1), 6=I_C04_EVC_YROFMODF_1_ST3_YOM806 (YOM806) (806 YEAR OF MODIFICATION 15/1, 25/1, 35/1, 45/1, 55/1), 7=I_C04_EVC_YROFMODF_1_ST3_YOM807 (YOM807) (807 YEAR OF MODIFICATION 16/1, 26/1, 36/1, 46/1, 56/1), 8=I_C04_EVC_YROFMODF_1_ST3_YOM808 (YOM808) (808 YEAR OF MODIFICATION 17/1, 27/1, 37/1, 47/1, 57/1), 9=I_C04_EVC_YROFMODF_1_ST3_YOM809 (YOM809) (809 YEAR OF MODIFICATION 18/1, 28/1, 38/1, 48/1, 58/1), 15=I_C04_EVC_YROFMODF_1_ST3_OTHER (OTHER) (none of listed variants)}, range raw 0..15 "04_EVC_YrOfModf_1_ST3", to IDC_Adpative  # Year of Modification YY/1
    signal EVC_List06_Country_ST3: start 48, 8 bit, little-endian, data-type-policy=OVERRIDE, i-signal-type=PRIMITIVE, compu {0=I_C08_EVC_COUNTRY_EXTENDED_DEU (DEU) (229L GERMANY), 1=I_C08_EVC_COUNTRY_EXTENDED_DEU_IMPORT (DEU_IMPORT) (230L GERMANY - IMPORT), 2=I_C08_EVC_COUNTRY_EXTENDED_ALB (ALB) (511L ALBANIA), 3=I_C08_EVC_COUNTRY_EXTENDED_AZE (AZE) (512L AZERBAIJAN), 4=I_C08_EVC_COUNTRY_EXTENDED_BGR (BGR) (515L BULGARIA), 5=I_C08_EVC_COUNTRY_EXTENDED_ARM (ARM) (516L ARMENIA), 6=I_C08_EVC_COUNTRY_EXTENDED_MDA (MDA) (520L MOLDAVIA), 7=I_C08_EVC_COUNTRY_EXTENDED_GEO (GEO) (521L GEORGIA), 8=I_C08_EVC_COUNTRY_EXTENDED_EST (EST) (523L ESTONIA), 9=I_C08_EVC_COUNTRY_EXTENDED_RUS (RUS) (524L RUSSIA), 10=I_C08_EVC_COUNTRY_EXTENDED_LVA (LVA) (525L LATVIA), 11=I_C08_EVC_COUNTRY_EXTENDED_UKR (UKR) (526L UKRAINE), 12=I_C08_EVC_COUNTRY_EXTENDED_LTU (LTU) (527L LITHUANIA), 13=I_C08_EVC_COUNTRY_EXTENDED_BLR (BLR) (528L BELARUS), 14=I_C08_EVC_COUNTRY_EXTENDED_FIN (FIN) (529L FINLAND), 15=I_C08_EVC_COUNTRY_EXTENDED_ISL (ISL) (541L ICELAND), 16=I_C08_EVC_COUNTRY_EXTENDED_HRV (HRV) (542L CROATIA), 17=I_C08_EVC_COUNTRY_EXTENDED_MKD (MKD) (550L MACEDONIA), 18=I_C08_EVC_COUNTRY_EXTENDED_MNE (MNE) (552L MONTENEGRO), 19=I_C08_EVC_COUNTRY_EXTENDED_SRB (SRB) (554L SERBIA), 20=I_C08_EVC_COUNTRY_EXTENDED_BEL (BEL) (513L BELGIUM), 21=I_C08_EVC_COUNTRY_EXTENDED_DNK (DNK) (517L DENMARK), 22=I_C08_EVC_COUNTRY_EXTENDED_FRA (FRA) (531L FRANCE), 23=I_C08_EVC_COUNTRY_EXTENDED_GRC (GRC) (535L GREECE), 24=I_C08_EVC_COUNTRY_EXTENDED_GBR (GBR) (537L GREAT BRITAIN AND NORTH-IRELAND), 25=I_C08_EVC_COUNTRY_EXTENDED_IRL (IRL) (539L IRELAND REPUBLIC), 26=I_C08_EVC_COUNTRY_EXTENDED_ITA (ITA) (543L ITALY), 27=I_C08_EVC_COUNTRY_EXTENDED_SVN (SVN) (546L SLOVENIA), 28=I_C08_EVC_COUNTRY_EXTENDED_LUX (LUX) (547L LUXEMBOURG), 29=I_C08_EVC_COUNTRY_EXTENDED_MLT (MLT) (549L MALTA), 30=I_C08_EVC_COUNTRY_EXTENDED_NDL (NDL) (553L NETHERLANDS), 31=I_C08_EVC_COUNTRY_EXTENDED_AUT (AUT) (557L AUSTRIA), 32=I_C08_EVC_COUNTRY_EXTENDED_PRT (PRT) (561L PORTUGAL), 33=I_C08_EVC_COUNTRY_EXTENDED_SWE (SWE) (569L SWEDEN), 34=I_C08_EVC_COUNTRY_EXTENDED_CHE (CHE) (571L SWITZERLAND), 35=I_C08_EVC_COUNTRY_EXTENDED_ESP (ESP) (577L SPAIN), 36=I_C08_EVC_COUNTRY_EXTENDED_NOR (NOR) (555L NORWAY), 37=I_C08_EVC_COUNTRY_EXTENDED_BIH (BIH) (558L BOSNIA-HERZEGOVINA), 38=I_C08_EVC_COUNTRY_EXTENDED_POL (POL) (559L POLAND), 39=I_C08_EVC_COUNTRY_EXTENDED_ROU (ROU) (567L ROMANIA), 40=I_C08_EVC_COUNTRY_EXTENDED_CZE (CZE) (576L CZECH REPUBLIC), 41=I_C08_EVC_COUNTRY_EXTENDED_SVK (SVK) (580L SLOVAKIAN REPUBLIC), 42=I_C08_EVC_COUNTRY_EXTENDED_TUR (TUR) (581L TURKEY), 43=I_C08_EVC_COUNTRY_EXTENDED_HUN (HUN) (583L HUNGARY), 44=I_C08_EVC_COUNTRY_EXTENDED_EGY (EGY) (601L EGYPT), 45=I_C08_EVC_COUNTRY_EXTENDED_GAB (GAB) (603L GABON), 46=I_C08_EVC_COUNTRY_EXTENDED_CAF (CAF) (604L CENTRAL AFRICAN REPUBLIC), 47=I_C08_EVC_COUNTRY_EXTENDED_ETH (ETH) (605L ETHIOPIA), 48=I_C08_EVC_COUNTRY_EXTENDED_ERI (ERI) (606L ERITREA), 49=I_C08_EVC_COUNTRY_EXTENDED_DZA (DZA) (607L ALGERIA), 50=I_C08_EVC_COUNTRY_EXTENDED_AGO (AGO) (609L ANGOLA), 51=I_C08_EVC_COUNTRY_EXTENDED_GMB (GMB) (611L GAMBIA), 52=I_C08_EVC_COUNTRY_EXTENDED_GHA (GHA) (613L GHANA), 53=I_C08_EVC_COUNTRY_EXTENDED_ZAF (ZAF) (675L SOUTH AFRICAN REPUBLIC), 54=I_C08_EVC_COUNTRY_EXTENDED_TZA (TZA) (679L TANSANIA), 55=I_C08_EVC_COUNTRY_EXTENDED_TGO (TGO) (681L TOGO), 56=I_C08_EVC_COUNTRY_EXTENDED_BEN (BEN) (682L BENIN (DAHOME) PEOPLES REPUBLIC), 57=I_C08_EVC_COUNTRY_EXTENDED_TUN (TUN) (683L TUNISIA), 58=I_C08_EVC_COUNTRY_EXTENDED_MRT (MRT) (685L MAURITANIA), 59=I_C08_EVC_COUNTRY_EXTENDED_SEN (SEN) (686L SENEGAL), 60=I_C08_EVC_COUNTRY_EXTENDED_MLI (MLI) (687L MALI), 61=I_C08_EVC_COUNTRY_EXTENDED_BFA (BFA) (614L BURKINA FASO), 62=I_C08_EVC_COUNTRY_EXTENDED_GNB (GNB) (615L GUINEA-PORTUGESE), 63=I_C08_EVC_COUNTRY_EXTENDED_GIN (GIN) (616L GUINEA-REPUBLIC), 64=I_C08_EVC_COUNTRY_EXTENDED_STP (STP) (617L SAO TOME AND PRINCIPE), 65=I_C08_EVC_COUNTRY_EXTENDED_GNQ (GNQ) (619L EQUATORIAL-GUINEA), 66=I_C08_EVC_COUNTRY_EXTENDED_CPV (CPV) (620L CAPE VERDE ISLANDS), 67=I_C08_EVC_COUNTRY_EXTENDED_TCD (TCD) (622L CHAD), 68=I_C08_EVC_COUNTRY_EXTENDED_CMR (CMR) (623L CAMAROON), 69=I_C08_EVC_COUNTRY_EXTENDED_KEN (KEN) (627L KENYA), 70=I_C08_EVC_COUNTRY_EXTENDED_CAN (CAN) (701L CANADA), 71=I_C08_EVC_COUNTRY_EXTENDED_USA (USA) (705L UNITED STATES (USA)), 72=I_C08_EVC_COUNTRY_EXTENDED_USA_CKD (USA_CKD) (711L UNITED STATES OF AMERICA (USA) CKD), 73=I_C08_EVC_COUNTRY_EXTENDED_SX (SX) (720L ST. MARTIN DUTCH ANTILLES), 74=I_C08_EVC_COUNTRY_EXTENDED_CW (CW) (721L CURACAO DUTCH ANTILLES), 75=I_C08_EVC_COUNTRY_EXTENDED_AW (AW) (722L ARUBA DUTCH ANTILLES), 76=I_C08_EVC_COUNTRY_EXTENDED_CRI (CRI) (723L COSTA RICA), 77=I_C08_EVC_COUNTRY_EXTENDED_VGB (VGB) (724L BRITISH VIRGIN ISLANDS), 78=I_C08_EVC_COUNTRY_EXTENDED_DOM (DOM) (725L DOMINICAN REPUBLIC), 79=I_C08_EVC_COUNTRY_EXTENDED_GTM (GTM) (727L GUATEMALA), 80=I_C08_EVC_COUNTRY_EXTENDED_HTI (HTI) (729L HAITI), 81=I_C08_EVC_COUNTRY_EXTENDED_HND (HND) (733L REPUBLIC OF HONDURAS), 82=I_C08_EVC_COUNTRY_EXTENDED_CUB (CUB) (735L CUBA), 83=I_C08_EVC_COUNTRY_EXTENDED_MEX (MEX) (737L MEXICO), 84=I_C08_EVC_COUNTRY_EXTENDED_NIC (NIC) (739L NICARAGUA), 85=I_C08_EVC_COUNTRY_EXTENDED_PAN (PAN) (741L PANAMA (WITHOUT CANAL ZONE)), 86=I_C08_EVC_COUNTRY_EXTENDED_SLV (SLV) (747L EL SALVADOR), 87=I_C08_EVC_COUNTRY_EXTENDED_BHS (BHS) (749L BAHAMAS - ISLANDS), 88=I_C08_EVC_COUNTRY_EXTENDED_BRB (BRB) (751L BARBADOS), 89=I_C08_EVC_COUNTRY_EXTENDED_JAM (JAM) (753L JAMAICA), 90=I_C08_EVC_COUNTRY_EXTENDED_BHR (BHR) (805L BAHRAIN), 91=I_C08_EVC_COUNTRY_EXTENDED_QAT (QAT) (807L QUATAR), 92=I_C08_EVC_COUNTRY_EXTENDED_TWN (TWN) (817L TAIWAN), 93=I_C08_EVC_COUNTRY_EXTENDED_CHN (CHN) (819L PEOPLE'S REPUBLIC CHINA), 94=I_C08_EVC_COUNTRY_EXTENDED_HKG (HKG) (823L HONG KONG), 95=I_C08_EVC_COUNTRY_EXTENDED_MAC (MAC) (824L MACAU), 96=I_C08_EVC_COUNTRY_EXTENDED_JPN (JPN) (839L JAPAN), 97=I_C08_EVC_COUNTRY_EXTENDED_KOR (KOR) (847L REPUBLIC OF KOREA), 98=I_C08_EVC_COUNTRY_EXTENDED_KWT (KWT) (849L KUWAIT), 99=I_C08_EVC_COUNTRY_EXTENDED_MYS (MYS) (855L MALAYSIA), 100=I_C08_EVC_COUNTRY_EXTENDED_OMN (OMN) (861L OMAN), 101=I_C08_EVC_COUNTRY_EXTENDED_MNG (MNG) (863L MONGOLIA), 102=I_C08_EVC_COUNTRY_EXTENDED_SAU (SAU) (873L SAUDI-ARABIA), 103=I_C08_EVC_COUNTRY_EXTENDED_SGP (SGP) (875L SINGAPORE), 104=I_C08_EVC_COUNTRY_EXTENDED_AE_AZ (AE_AZ) (878L ABU DHABI), 105=I_C08_EVC_COUNTRY_EXTENDED_THA (THA) (879L THAILAND), 106=I_C08_EVC_COUNTRY_EXTENDED_AE_DU (AE_DU) (880L DUBAI), 107=I_C08_EVC_COUNTRY_EXTENDED_VNM (VNM) (882L VIETNAM), 108=I_C08_EVC_COUNTRY_EXTENDED_YEM (YEM) (841L YEMEN ARABIC REPUBLIC), 109=I_C08_EVC_COUNTRY_EXTENDED_JOR (JOR) (843L JORDAN), 110=I_C08_EVC_COUNTRY_EXTENDED_KHM (KHM) (845L CAMBODIA), 111=I_C08_EVC_COUNTRY_EXTENDED_PRK (PRK) (848L DEMOCRATIC PEOPLE'S REPUBLIC OF KOREA), 112=I_C08_EVC_COUNTRY_EXTENDED_LAO (LAO) (851L LAOS), 113=I_C08_EVC_COUNTRY_EXTENDED_LBN (LBN) (853L LEBANON), 114=I_C08_EVC_COUNTRY_EXTENDED_MDV (MDV) (857L MALEDIVES), 115=I_C08_EVC_COUNTRY_EXTENDED_NPL (NPL) (865L NEPAL), 116=I_C08_EVC_COUNTRY_EXTENDED_PAK (PAK) (867L PAKISTAN), 117=I_C08_EVC_COUNTRY_EXTENDED_BGD (BGD) (868L BANGLADESH), 118=I_C08_EVC_COUNTRY_EXTENDED_PHL (PHL) (869L PHILIPPINE ISLANDS), 119=I_C08_EVC_COUNTRY_EXTENDED_SYR (SYR) (877L SYRIA), 120=I_C08_EVC_COUNTRY_EXTENDED_AUS (AUS) (901L AUSTRALIA ASSOCIATION), 121=I_C08_EVC_COUNTRY_EXTENDED_CAYMAN (CAYMAN) (754L CAYMAN - ISLANDS), 122=I_C08_EVC_COUNTRY_EXTENDED_PNG (PNG) (915L PAPUA NEW GUINEA), 123=I_C08_EVC_COUNTRY_EXTENDED_NZL (NZL) (919L NEW ZEALAND), 124=I_C08_EVC_COUNTRY_EXTENDED_TTO (TTO) (757L TRINIDAD), 125=I_C08_EVC_COUNTRY_EXTENDED_LCA (LCA) (768L SANTA LUCIA), 126=I_C08_EVC_COUNTRY_EXTENDED_PYF (PYF) (923L FRENCH POLYNESIA), 127=I_C08_EVC_COUNTRY_EXTENDED_NCL (NCL) (924L NEW CALEDONIA), 128=I_C08_EVC_COUNTRY_EXTENDED_TON (TON) (926L TONGA), 129=I_C08_EVC_COUNTRY_EXTENDED_WSM (WSM) (927L SAMOA), 130=I_C08_EVC_COUNTRY_EXTENDED_ARG (ARG) (771L ARGENTINA), 131=I_C08_EVC_COUNTRY_EXTENDED_BOL (BOL) (773L BOLIVIA), 132=I_C08_EVC_COUNTRY_EXTENDED_BRA (BRA) (775L BRASIL), 133=I_C08_EVC_COUNTRY_EXTENDED_CHL (CHL) (777L CHILE), 134=I_C08_EVC_COUNTRY_EXTENDED_ECU (ECU) (779L ECUADOR), 135=I_C08_EVC_COUNTRY_EXTENDED_GUY (GUY) (781L REPUBLIC OF GUIANA), 136=I_C08_EVC_COUNTRY_EXTENDED_COL (COL) (785L COLUMBIA), 137=I_C08_EVC_COUNTRY_EXTENDED_PRY (PRY) (787L PARAGUAY), 138=I_C08_EVC_COUNTRY_EXTENDED_PER (PER) (789L PERU), 139=I_C08_EVC_COUNTRY_EXTENDED_SUR (SUR) (791L SURINAM), 140=I_C08_EVC_COUNTRY_EXTENDED_URY (URY) (793L URUGUAY), 141=I_C08_EVC_COUNTRY_EXTENDED_VEN (VEN) (795L VENEZUELA), 142=I_C08_EVC_COUNTRY_EXTENDED_AFG (AFG) (803L AFGHANISTAN), 143=I_C08_EVC_COUNTRY_EXTENDED_W_JORDAN (W_JORDAN) (808L WEST JORDAN), 144=I_C08_EVC_COUNTRY_EXTENDED_KAZ (KAZ) (810L KAZAKHSTAN), 145=I_C08_EVC_COUNTRY_EXTENDED_MMR (MMR) (811L MYANMAR (BURMA)), 146=I_C08_EVC_COUNTRY_EXTENDED_KGZ (KGZ) (812L KURGISTAN), 147=I_C08_EVC_COUNTRY_EXTENDED_BRN (BRN) (813L BRUNEI), 148=I_C08_EVC_COUNTRY_EXTENDED_TJK (TJK) (814L TADZHIKISTAN), 149=I_C08_EVC_COUNTRY_EXTENDED_LKA (LKA) (815L SRI LANKA), 150=I_C08_EVC_COUNTRY_EXTENDED_TKM (TKM) (816L TURKMENISTAN), 151=I_C08_EVC_COUNTRY_EXTENDED_UZB (UZB) (818L USBEKISTAN), 152=I_C08_EVC_COUNTRY_EXTENDED_PSE (PSE) (820L GAZA), 153=I_C08_EVC_COUNTRY_EXTENDED_CYP_SOUTH (CYP_SOUTH) (821L CYPRUS), 154=I_C08_EVC_COUNTRY_EXTENDED_CYP_NORTH (CYP_NORTH) (822L CYPRUS NORTH), 155=I_C08_EVC_COUNTRY_EXTENDED_IND (IND) (825L INDIA), 156=I_C08_EVC_COUNTRY_EXTENDED_IDN (IDN) (831L INDONESIA / JAKARTA), 157=I_C08_EVC_COUNTRY_EXTENDED_IRQ (IRQ) (833L IRAQ), 158=I_C08_EVC_COUNTRY_EXTENDED_IRN (IRN) (835L IRAN), 159=I_C08_EVC_COUNTRY_EXTENDED_ISR (ISR) (837L ISRAEL), 160=I_C08_EVC_COUNTRY_EXTENDED_UGA (UGA) (629L UGANDA), 161=I_C08_EVC_COUNTRY_EXTENDED_COD (COD) (631L CONGO DEMOKRATIC REPUBLIC (FORMERLY ZAIRE)), 162=I_C08_EVC_COUNTRY_EXTENDED_COG (COG) (632L CONGO REPUBLIC (FORMERLY PEOPLES REPUBLIC), 163=I_C08_EVC_COUNTRY_EXTENDED_LBR (LBR) (633L LIBERIA), 164=I_C08_EVC_COUNTRY_EXTENDED_CIV (CIV) (634L IVORY COAST), 165=I_C08_EVC_COUNTRY_EXTENDED_LBY (LBY) (635L LIBYA), 166=I_C08_EVC_COUNTRY_EXTENDED_MDG (MDG) (637L MADAGASCAR), 167=I_C08_EVC_COUNTRY_EXTENDED_COM (COM) (638L COMORO ISLANDS), 168=I_C08_EVC_COUNTRY_EXTENDED_MAR (MAR) (641L MOROCCO), 169=I_C08_EVC_COUNTRY_EXTENDED_NGA (NGA) (643L NIGERIA), 170=I_C08_EVC_COUNTRY_EXTENDED_NER (NER) (644L NIGER), 171=I_C08_EVC_COUNTRY_EXTENDED_MOZ (MOZ) (647L MOZAMBIQUE), 172=I_C08_EVC_COUNTRY_EXTENDED_ZWE (ZWE) (649L ZIMBABWE), 173=I_C08_EVC_COUNTRY_EXTENDED_ZMB (ZMB) (650L SAMBIA), 174=I_C08_EVC_COUNTRY_EXTENDED_MWI (MWI) (651L MALAWI), 175=I_C08_EVC_COUNTRY_EXTENDED_RWA (RWA) (653L RUANDA), 176=I_C08_EVC_COUNTRY_EXTENDED_BDI (BDI) (654L BURUNDI), 177=I_C08_EVC_COUNTRY_EXTENDED_MUS (MUS) (661L MAURITIUS), 178=I_C08_EVC_COUNTRY_EXTENDED_SYC (SYC) (662L SEYCHELLES), 179=I_C08_EVC_COUNTRY_EXTENDED_SLE (SLE) (663L SIERRA LEONE), 180=I_C08_EVC_COUNTRY_EXTENDED_DJI (DJI) (667L DJIBOUTI), 181=I_C08_EVC_COUNTRY_EXTENDED_SOM (SOM) (669L SOMALIA), 182=I_C08_EVC_COUNTRY_EXTENDED_SDN (SDN) (673L SUDAN), 255=I_C08_EVC_COUNTRY_EXTENDED_OTHER (OTHER) (none of listed variants)}, range raw 0..255 "08_EVC_Country_extended", to IDC_Adpative  # Country
    signal EVC_List07_TxStyle_ST3: start 56, 4 bit, little-endian, data-type-policy=OVERRIDE, i-signal-type=PRIMITIVE, compu {0=I_C04_EVC_TXSTYLE_ST3_MANUAL_6 (MANUAL_6) (411 MANUAL TRANSMISSION, 6-SPEED), 2=I_C04_EVC_TXSTYLE_ST3_AUTOM_7 (AUTOM_7) (427 AUTOMATIC TRANSMISSION 7-SPEED), 3=I_C04_EVC_TXSTYLE_ST3_AUTOM_9 (AUTOM_9) (421 AUTOMATIC TRANSMISSION 9-SPEED), 4=I_C04_EVC_TXSTYLE_ST3_MANUAL_6_NSG2 (MANUAL_6_NSG2) (425 MANUAL TRANSMISSION 6-SPEED (NSG2)), 5=I_C04_EVC_TXSTYLE_ST3_AUTOM_7_DCT (AUTOM_7_DCT) (429 AUTOMATIC DCT TRANSMISSION 7-SPEED), 6=I_C04_EVC_TXSTYLE_ST3_AUTOM_9_DCT (AUTOM_9_DCT) (426 AUTOMATIC DCT TRANSMISSION 9-SPEED), 7=I_C04_EVC_TXSTYLE_ST3_E_DRIVE (E_DRIVE) (081K TRANSMISSON FOR E-VEHICLES), 15=I_C04_EVC_TXSTYLE_ST3_OTHER (OTHER) (none of listed variants)}, range raw 0..15 "04_EVC_TxStyle_ST3", to IDC_Adpative  # Transmission Style
    signal EVC_List08_HL_Style_ST3: start 60, 4 bit, little-endian, data-type-policy=OVERRIDE, i-signal-type=PRIMITIVE, compu {0=I_C04_EVC_HL_STYLE_ST3_LED_STAT_LHT (LED_STAT_LHT) (631 HEADLIGHT UNIT LED W. STATIC LIGHT SYSTEM LHT), 1=I_C04_EVC_HL_STYLE_ST3_LED_STAT_RHT (LED_STAT_RHT) (632 HEADLIGHT UNIT LED W. STATIC LIGHT SYSTEM RHT), 2=I_C04_EVC_HL_STYLE_ST3_LED_DYN_SAE_RHT (LED_DYN_SAE_RHT) (640 HEADLIGHT UNIT LED W DYNAMIC LIGHT SYSTEM SAE RHT), 3=I_C04_EVC_HL_STYLE_ST3_LED_DYN_LHT (LED_DYN_LHT) (641 HEADLIGHT UNIT LED W. DYNAMIC LIGHT SYSTEM LHT), 4=I_C04_EVC_HL_STYLE_ST3_LED_DYN_RHT (LED_DYN_RHT) (642 HEADLIGHT UNIT LED W. DYNAMIC LIGHT SYSTEM RHT), 5=I_C04_EVC_HL_STYLE_ST3_HEADLIGHT_LHT (HEADLIGHT_LHT) (613 HEADLIGHT UNIT - ASSYMETRICAL, LH TRAFFIC), 6=I_C04_EVC_HL_STYLE_ST3_HEADLIGHT_RHT (HEADLIGHT_RHT) (620 HEADLIGHT UNIT RHT), 7=I_C04_EVC_HL_STYLE_ST3_DIGITAL_SAE_RHT (DIGITAL_SAE_RHT) (316 HEADLIGHT UNIT DIGITAL LED LIGHT SYSTEM SAE RHT), 8=I_C04_EVC_HL_STYLE_ST3_DIGITAL_LHT (DIGITAL_LHT) (317 HEADLIGHT UNIT DIGITAL LED LIGHT SYSTEM LHT), 9=I_C04_EVC_HL_STYLE_ST3_DIGITAL_RHT (DIGITAL_RHT) (318 HEADLIGHT UNIT DIGITAL LED LIGHT SYSTEM RHT), 15=I_C04_EVC_HL_STYLE_ST3_OTHER (OTHER) (none of listed variants)}, range raw 0..15 "04_EVC_HL_Style_ST3", to IDC_Adpative  # Headlamp Style
    mapping EVC_CfgList_01_08_Pr5_ST3_co3q1mwsf7pwxo2ix5jryc04x: i-signal-group=EVC_CfgList_01_08_Pr5_ST3_co3q1mwsf7pwxo2ix5jryc04x, transfer-property=PENDING
  pdu Ign_Stat_ST3: length=4, minimum-delay=0.02, unused-bit-pattern=255  # Ignition state
    signal ISw_Stat_ST3: start 24, 3 bit, little-endian, data-type-policy=OVERRIDE, i-signal-type=PRIMITIVE, invalid-value=7, compu {0=I_C03_ISW_STAT_IGN_LOCK (IGN_LOCK) (Ignition lock (0)), 1=I_C03_ISW_STAT_IGN_OFF (IGN_OFF) (Ignition off (15c)), 2=I_C03_ISW_STAT_IGN_ACC (IGN_ACC) (Ignition accessory (15r)), 4=I_C03_ISW_STAT_IGN_ON (IGN_ON) (Ignition on (15)), 5=I_C03_ISW_STAT_IGN_START (IGN_START) (Ignition start (50)), 7=I_C03_ISW_STAT_SNA (SNA) (SNA value from data type)}, range raw 0..7 "03_ISw_Stat", to IDC_Adpative  # Ignition switch state
    mapping CRC_Ign_Stat_Pr5_ST3: transfer-property=PENDING
    mapping Ign_Stat_Pr5_ST3_csgs1dv6drms80o1i9p49677w: i-signal-group=Ign_Stat_Pr5_ST3_csgs1dv6drms80o1i9p49677w, transfer-property=TRIGGERED-ON-CHANGE
    mapping KG_StartSw_Psd_ST3: transfer-property=PENDING
    mapping SQC_Ign_Stat_Pr5_ST3: transfer-property=PENDING
    mapping Veh_Op_Mode_ST3: transfer-property=PENDING
  pdu PN14_Master_Stat1_ST3: length=8, unused-bit-pattern=255  # Powernetwork 12V master state
    signal PN14_DDP_Sw_Stat_ST3: start 2, 3 bit, little-endian, data-type-policy=OVERRIDE, i-signal-type=PRIMITIVE, invalid-value=7, compu {0=I_C03_PN14_TDP_SW_STAT_CLS (CLS) (TDP switch is closed), 1=I_C03_PN14_TDP_SW_STAT_PRE_RESET (PRE_RESET) (Pre-Reset warning), 2=I_C03_PN14_TDP_SW_STAT_RESET (RESET) (Reset active), 3=I_C03_PN14_TDP_SW_STAT_PRE_OPN (PRE_OPN) (Pre-Open warning), 4=I_C03_PN14_TDP_SW_STAT_OPN (OPN) (TDP switch is open), 7=I_C03_PN14_TDP_SW_STAT_SNA (SNA) (SNA value from data type)}, range raw 0..7 "03_PN14_TDP_Sw_Stat", transfer-property=PENDING, to IDC_Adpative  # Deep discharge protection switch state
    mapping PN14_DDP_Sw2_Stat_ST3: transfer-property=PENDING
    mapping PN14_ExtBat_Charge_Actv_ST3: transfer-property=PENDING
    mapping PN14_PNSec_RechargeEnable_ST3: transfer-property=PENDING
    mapping PN14_ProdMd_BatStat_ST3: transfer-property=PENDING
    mapping PN14_ProdMd_Stat_ST3: transfer-property=PENDING
    mapping PN14_SupBat_Curr_ST3: transfer-property=PENDING
    mapping PN14_SupBat_Stat_ST3: transfer-property=PENDING
    mapping PN14_SupBat_Temp_ST3: transfer-property=PENDING
    mapping PN14_SupBat_Volt_ST3: transfer-property=PENDING
    mapping PN14_TransMd_Stat_ST3: transfer-property=PENDING
  pdu PT4_PTCoor4_ST3: length=4, minimum-delay=0.01, unused-bit-pattern=255
    signal CRC_PT4_PTCoor4_Pr5_ST3: start 0, 16 bit, little-endian, data-type-policy=OVERRIDE, i-signal-type=PRIMITIVE, data-constr=c16_CRC_woSNA, transfer-property=PENDING, to IDC_Adpative  # CRC-checksum of signal group according to AUTOSAR Profile 5
    signal SQC_PT4_PTCoor4_Pr5_ST3: start 16, 8 bit, little-endian, data-type-policy=OVERRIDE, i-signal-type=PRIMITIVE, compu {identical}, data-constr=c08_0_255_1_SNA_na, transfer-property=PENDING, to IDC_Adpative  # Sequence counter
    signal PT4_PTCoor_PT_Rdy_ST3: start 24, 2 bit, little-endian, data-type-policy=OVERRIDE, i-signal-type=PRIMITIVE, invalid-value=3, compu {0=I_C02_PT_RDY_V2_PT_NOT_RDY (PT_NOT_RDY) (Powertrain is not ready), 1=I_C02_PT_RDY_V2_PT_RDY (PT_RDY) (Powertrain is ready), 3=I_C02_PT_RDY_V2_SNA (SNA) (SNA value from data type)} "Powertrain ready", range raw 0..3 "02_PT_Rdy_V2", transfer-property=TRIGGERED-ON-CHANGE, to IDC_Adpative  # Powertrain ready
    signal PT4_PTCoor_SSA_EngSp_ST3: start 26, 2 bit, little-endian, data-type-policy=OVERRIDE, i-signal-type=PRIMITIVE, invalid-value=3, compu {1=I_C02_NDEF_FALSE_TRUE_ST3_FALSE (FALSE) (False), 2=I_C02_NDEF_FALSE_TRUE_ST3_TRUE (TRUE) (True), 3=I_C02_NDEF_FALSE_TRUE_ST3_SNA (SNA) (SNA value from data type)} "DO NOT USE for future implementation of STAR3 and following architectures. Use 02_False_True instead.", range raw 1..3 "02_Ndef_False_True_ST3", transfer-property=TRIGGERED-ON-CHANGE, to IDC_Adpative  # Stop/start automatic has engine stopped
    signal PT4_PTCoor_EngStartPN14_Stat_ST3: start 28, 3 bit, little-endian, data-type-policy=OVERRIDE, i-signal-type=PRIMITIVE, invalid-value=7, compu {0=I_C03_ENGSTARTPN14_STAT_NO_COMBUSTIONSTART_RQ (NO_COMBUSTIONSTART_RQ) (No combustion start required), 1=I_C03_ENGSTARTPN14_STAT_CUSTOMER_START_RQ (CUSTOMER_START_RQ) (Customer start required), 2=I_C03_ENGSTARTPN14_STAT_AUTO_START_NO_PN_SUP_RQ (AUTO_START_NO_PN_SUP_RQ) (Automatic start without Powernet support required), 3=I_C03_ENGSTARTPN14_STAT_AUTO_START_PN_SUP_RQ (AUTO_START_PN_SUP_RQ) (Automatic start with Powernet support required), 7=I_C03_ENGSTARTPN14_STAT_SNA (SNA) (SNA value from data type)}, range raw 0..7 "03_EngStartPN14_Stat_ST3", transfer-property=TRIGGERED-ON-CHANGE, to IDC_Adpative  # PT4 Engine Start PN14 State
    signal Rsrv1_PT4_PTCoor_PT_Rdy_Pr5_ST3: start 31, 1 bit, little-endian, data-type-policy=OVERRIDE, i-signal-type=PRIMITIVE, invalid-value=1, range raw 0..1, transfer-property=PENDING, to IDC_Adpative  # Reserved for future use
    mapping PT4_PTCoor4_Pr5_ST3_af4fxb1ykieox3itqdfzs0kpb: i-signal-group=PT4_PTCoor4_Pr5_ST3_af4fxb1ykieox3itqdfzs0kpb, transfer-property=TRIGGERED-ON-CHANGE
package /Communication/Signals
  9 x i signal group:
    CamSensSoil_MPC_ST3_arrjrmhd69107z3r1gztlanxq: i-signal=[CamSensSoil_CMS_IconDisp_Rq_MPC_ST3, CamSensSoil_IHC_IconDisp_Rq_MPC_ST3, CamSensSoil_LDP_IconDisp_Rq_MPC_ST3, CamSensSoil_MsgDisp_Rq_MPC_ST3, CamSensSoil_TSA_IconDisp_Rq_MPC_ST3], system-signal-group=CamSensSoil_MPC_ST3_arrjrmhd69107z3r1gztlanxq  # Cam Sens Soil MPC ST3 (degraded)
    DI_Odo_Pr5_ST3_e68xmtlkywxgxsdwekdjjhw3t: i-signal=Odo_ST3, system-signal-group=DI_Odo_Pr5_ST3_e68xmtlkywxgxsdwekdjjhw3t  # DriverInformation Odometer (degraded)
    EVC_CfgBit_01_26_Pr5_ST3_fblv727rnlh4ltr0dm5mnkvh: i-signal=[CRC_EVC_CfgBit_01_26_Pr5_ST3, EVC_01_494_Avl_ST3, EVC_02_498_Avl_ST3, EVC_03_623_Avl_ST3, EVC_04_625_Avl_ST3, EVC_05_830_Avl_ST3, EVC_06_835_Avl_ST3, EVC_07_460_Avl_ST3, EVC_08_AddEquip_Avl_ST3, EVC_09_AddEquip_Avl_ST3, EVC_0A_AddEquip_Avl_ST3, EVC_0B_AddEquip_Avl_ST3, EVC_0C_465_Avl_ST3, EVC_0D_470_Avl_ST3, EVC_0E_479_Avl_ST3, EVC_0F_AddEquip_Avl_ST3, EVC_10_AddEquip_Avl_ST3, EVC_11_AddEquip_Avl_ST3, EVC_12_AddEquip_Avl_ST3, EVC_13_AddEquip_Avl_ST3, EVC_14_M035_Avl_ST3, EVC_15_MED2_Avl_ST3, EVC_16_M013_Avl_ST3, EVC_17_M014_Avl_ST3, EVC_18_M016_Avl_ST3, EVC_19_M005_Avl_ST3, EVC_1A_AddEquip_Avl_ST3, EVC_1B_MEF2_Avl_ST3, EVC_1C_MEF3_Avl_ST3, EVC_1D_201_Avl_ST3, EVC_1E_216_Avl_ST3, EVC_1F_215_Avl_ST3, EVC_20_487_Avl_ST3, EVC_21_488_Avl_ST3, EVC_22_489_Avl_ST3, EVC_23_490_Avl_ST3, EVC_24_486_Avl_ST3, EVC_25_AddEquip_Avl_ST3, EVC_26_459_Avl_ST3, EVC_CfgBit_01_26_Stat_ST3, SQC_EVC_CfgBit_01_26_Pr5_ST3], system-signal-group=EVC_CfgBit_01_26_Pr5_ST3_fblv727rnlh4ltr0dm5mnkvh  # EVC Cfg Bit 01 26 Pr 5 ST3 (degraded)
    EVC_CfgBit_73_98_Pr5_ST3_4xva8cvevi64tljtz3c92ker3: i-signal=[CRC_EVC_CfgBit_73_98_Pr5_ST3, EVC_73_501_Avl_ST3, EVC_74_476_Avl_ST3, EVC_75_AddEquip_Avl_ST3, EVC_76_513_Avl_ST3, EVC_77_299_Avl_ST3, EVC_78_306_Avl_ST3, EVC_79_AddEquip_Avl_ST3, EVC_7A_AddEquip_Avl_ST3, EVC_7B_551_Avl_ST3, EVC_7C_503_Avl_ST3, EVC_7D_220_Avl_ST3, EVC_7E_218_Avl_ST3, EVC_7F_235_Avl_ST3, EVC_80_AddEquip_Avl_ST3, EVC_81_AddEquip_Avl_ST3, EVC_82_440_Avl_ST3, EVC_83_AddEquip_Avl_ST3, EVC_84_504_Avl_ST3, EVC_85_27U_Avl_ST3, EVC_86_K00_Avl_ST3, EVC_87_200_Avl_ST3, EVC_88_384_Avl_ST3, EVC_89_233_Avl_ST3, EVC_8A_234_Avl_ST3, EVC_8B_292_Avl_ST3, EVC_8C_243_Avl_ST3, EVC_8D_258_Avl_ST3, EVC_8E_239_Avl_ST3, EVC_8F_266_Avl_ST3, EVC_90_546_Avl_ST3, EVC_91_271_Avl_ST3, EVC_92_382_Avl_ST3, EVC_93_383_Avl_ST3, EVC_94_K29_Avl_ST3, EVC_95_AddEquip_Avl_ST3, EVC_96_430_Avl_ST3, EVC_97_950_Avl_ST3, EVC_98_952_Avl_ST3, EVC_CfgBit_73_98_Stat_ST3, SQC_EVC_CfgBit_73_98_Pr5_ST3], system-signal-group=EVC_CfgBit_73_98_Pr5_ST3_4xva8cvevi64tljtz3c92ker3  # EVC Cfg Bit 73 98 Pr 5 ST3 (degraded)
    EVC_CfgBit_99_BE_Pr5_ST3_cxgi3gf02ijeaizats4f45avn: i-signal=[EVC_9F_608_Avl_ST3, EVC_A0_628_Avl_ST3, EVC_CfgBit_99_BE_Stat_ST3], system-signal-group=EVC_CfgBit_99_BE_Pr5_ST3_cxgi3gf02ijeaizats4f45avn  # EVC Cfg Bit 99 BE Pr 5 ST3 (degraded)
    EVC_CfgList_01_08_Pr5_ST3_co3q1mwsf7pwxo2ix5jryc04x: i-signal=[CRC_EVC_CfgList_01_08_Pr5_ST3, EVC_CfgList_01_08_Stat_ST3, EVC_List01_BodyStyle_ST3, EVC_List02_VehLine_ST3, EVC_List03_StStyle_ST3, EVC_List04_YrOfModf_2_ST3, EVC_List05_YrOfModf_1_ST3, EVC_List06_Country_ST3, EVC_List07_TxStyle_ST3, EVC_List08_HL_Style_ST3, SQC_EVC_CfgList_01_08_Pr5_ST3], system-signal-group=EVC_CfgList_01_08_Pr5_ST3_co3q1mwsf7pwxo2ix5jryc04x  # EVC Cfg List 01 08 Pr 5 ST3 (degraded)
    Ign_Stat_Pr5_ST3_csgs1dv6drms80o1i9p49677w: i-signal=ISw_Stat_ST3, system-signal-group=Ign_Stat_Pr5_ST3_csgs1dv6drms80o1i9p49677w  # Ignition state (degraded)
    PT4_PTCoor4_Pr5_ST3_af4fxb1ykieox3itqdfzs0kpb: i-signal=[CRC_PT4_PTCoor4_Pr5_ST3, PT4_PTCoor_EngStartPN14_Stat_ST3, PT4_PTCoor_PT_Rdy_ST3, PT4_PTCoor_SSA_EngSp_ST3, Rsrv1_PT4_PTCoor_PT_Rdy_Pr5_ST3, SQC_PT4_PTCoor4_Pr5_ST3], system-signal-group=PT4_PTCoor4_Pr5_ST3_af4fxb1ykieox3itqdfzs0kpb  # PT4_PTCoor4_Pr5_ST3 (degraded)
    StWhl_Sw_CruiseCtrl_VSL_Stat_Pr5_ST3: i-signal=[CRC_StWhl_Sw_CruiseCtrl_VSL_Stat_Pr5_ST3, Rsrv1_StWhl_Sw_CruiseCtrl_VSL_Stat_Pr5_ST3, SQC_StWhl_Sw_CruiseCtrl_VSL_Stat_Pr5_ST3, StWhl_Sw_Cancel_Psd_ST3, StWhl_Sw_CruiseCtrl_Off_Psd_ST3, StWhl_Sw_CruiseCtrl_Select_Psd_ST3, StWhl_Sw_Dist_Minus_Psd_ST3, StWhl_Sw_Dist_Plus_Psd_ST3, StWhl_Sw_Dist_Tgl_Psd_ST3, StWhl_Sw_Dn10_Set_Psd_ST3, StWhl_Sw_Dn1_Psd_ST3, StWhl_Sw_HAD1_Psd_ST3, StWhl_Sw_HAD2_Psd_ST3, StWhl_Sw_Mode_Psd_ST3, StWhl_Sw_Resume_Psd_ST3, StWhl_Sw_Up10_Set_Psd_ST3, StWhl_Sw_Up1Dn1_StepSize_ST3, StWhl_Sw_Up1_Psd_ST3, StWhl_Sw_VSL_Off_Psd_ST3, StWhl_Sw_VSL_Select_Psd_ST3], system-signal-group=StWhl_Sw_CruiseCtrl_VSL_Stat_Pr5_ST3  # Steering wheel tip switches for Cruise Control / Variable Speed Limiter state
package /Communication/SystemSignalGroups
  9 x system signal group:
    CamSensSoil_MPC_ST3_arrjrmhd69107z3r1gztlanxq: system-signal=[CamSensSoil_CMS_IconDisp_Rq_MPC_ST3, CamSensSoil_IHC_IconDisp_Rq_MPC_ST3, CamSensSoil_LDP_IconDisp_Rq_MPC_ST3, CamSensSoil_MsgDisp_Rq_MPC_ST3, CamSensSoil_TSA_IconDisp_Rq_MPC_ST3]  # Cam Sens Soil MPC ST3 (degraded)
    DI_Odo_Pr5_ST3_e68xmtlkywxgxsdwekdjjhw3t: system-signal=Odo_ST3  # DriverInformation Odometer (degraded)
    EVC_CfgBit_01_26_Pr5_ST3_fblv727rnlh4ltr0dm5mnkvh: system-signal=[CRC_EVC_CfgBit_01_26_Pr5_ST3, EVC_01_494_Avl_ST3, EVC_02_498_Avl_ST3, EVC_03_623_Avl_ST3, EVC_04_625_Avl_ST3, EVC_05_830_Avl_ST3, EVC_06_835_Avl_ST3, EVC_07_460_Avl_ST3, EVC_08_AddEquip_Avl_ST3, EVC_09_AddEquip_Avl_ST3, EVC_0A_AddEquip_Avl_ST3, EVC_0B_AddEquip_Avl_ST3, EVC_0C_465_Avl_ST3, EVC_0D_470_Avl_ST3, EVC_0E_479_Avl_ST3, EVC_0F_AddEquip_Avl_ST3, EVC_10_AddEquip_Avl_ST3, EVC_11_AddEquip_Avl_ST3, EVC_12_AddEquip_Avl_ST3, EVC_13_AddEquip_Avl_ST3, EVC_14_M035_Avl_ST3, EVC_15_MED2_Avl_ST3, EVC_16_M013_Avl_ST3, EVC_17_M014_Avl_ST3, EVC_18_M016_Avl_ST3, EVC_19_M005_Avl_ST3, EVC_1A_AddEquip_Avl_ST3, EVC_1B_MEF2_Avl_ST3, EVC_1C_MEF3_Avl_ST3, EVC_1D_201_Avl_ST3, EVC_1E_216_Avl_ST3, EVC_1F_215_Avl_ST3, EVC_20_487_Avl_ST3, EVC_21_488_Avl_ST3, EVC_22_489_Avl_ST3, EVC_23_490_Avl_ST3, EVC_24_486_Avl_ST3, EVC_25_AddEquip_Avl_ST3, EVC_26_459_Avl_ST3, EVC_CfgBit_01_26_Stat_ST3, SQC_EVC_CfgBit_01_26_Pr5_ST3]  # EVC Cfg Bit 01 26 Pr 5 ST3 (degraded)
    EVC_CfgBit_73_98_Pr5_ST3_4xva8cvevi64tljtz3c92ker3: system-signal=[CRC_EVC_CfgBit_73_98_Pr5_ST3, EVC_73_501_Avl_ST3, EVC_74_476_Avl_ST3, EVC_75_AddEquip_Avl_ST3, EVC_76_513_Avl_ST3, EVC_77_299_Avl_ST3, EVC_78_306_Avl_ST3, EVC_79_AddEquip_Avl_ST3, EVC_7A_AddEquip_Avl_ST3, EVC_7B_551_Avl_ST3, EVC_7C_503_Avl_ST3, EVC_7D_220_Avl_ST3, EVC_7E_218_Avl_ST3, EVC_7F_235_Avl_ST3, EVC_80_AddEquip_Avl_ST3, EVC_81_AddEquip_Avl_ST3, EVC_82_440_Avl_ST3, EVC_83_AddEquip_Avl_ST3, EVC_84_504_Avl_ST3, EVC_85_27U_Avl_ST3, EVC_86_K00_Avl_ST3, EVC_87_200_Avl_ST3, EVC_88_384_Avl_ST3, EVC_89_233_Avl_ST3, EVC_8A_234_Avl_ST3, EVC_8B_292_Avl_ST3, EVC_8C_243_Avl_ST3, EVC_8D_258_Avl_ST3, EVC_8E_239_Avl_ST3, EVC_8F_266_Avl_ST3, EVC_90_546_Avl_ST3, EVC_91_271_Avl_ST3, EVC_92_382_Avl_ST3, EVC_93_383_Avl_ST3, EVC_94_K29_Avl_ST3, EVC_95_AddEquip_Avl_ST3, EVC_96_430_Avl_ST3, EVC_97_950_Avl_ST3, EVC_98_952_Avl_ST3, EVC_CfgBit_73_98_Stat_ST3, SQC_EVC_CfgBit_73_98_Pr5_ST3]  # EVC Cfg Bit 73 98 Pr 5 ST3 (degraded)
    EVC_CfgBit_99_BE_Pr5_ST3_cxgi3gf02ijeaizats4f45avn: system-signal=[EVC_9F_608_Avl_ST3, EVC_A0_628_Avl_ST3, EVC_CfgBit_99_BE_Stat_ST3]  # EVC Cfg Bit 99 BE Pr 5 ST3 (degraded)
    EVC_CfgList_01_08_Pr5_ST3_co3q1mwsf7pwxo2ix5jryc04x: system-signal=[CRC_EVC_CfgList_01_08_Pr5_ST3, EVC_CfgList_01_08_Stat_ST3, EVC_List01_BodyStyle_ST3, EVC_List02_VehLine_ST3, EVC_List03_StStyle_ST3, EVC_List04_YrOfModf_2_ST3, EVC_List05_YrOfModf_1_ST3, EVC_List06_Country_ST3, EVC_List07_TxStyle_ST3, EVC_List08_HL_Style_ST3, SQC_EVC_CfgList_01_08_Pr5_ST3]  # EVC Cfg List 01 08 Pr 5 ST3 (degraded)
    Ign_Stat_Pr5_ST3_csgs1dv6drms80o1i9p49677w: system-signal=ISw_Stat_ST3  # Ignition state (degraded)
    PT4_PTCoor4_Pr5_ST3_af4fxb1ykieox3itqdfzs0kpb: system-signal=[CRC_PT4_PTCoor4_Pr5_ST3, PT4_PTCoor_EngStartPN14_Stat_ST3, PT4_PTCoor_PT_Rdy_ST3, PT4_PTCoor_SSA_EngSp_ST3, Rsrv1_PT4_PTCoor_PT_Rdy_Pr5_ST3, SQC_PT4_PTCoor4_Pr5_ST3]  # PT4_PTCoor4_Pr5_ST3 (degraded)
    StWhl_Sw_CruiseCtrl_VSL_Stat_Pr5_ST3: system-signal=[CRC_StWhl_Sw_CruiseCtrl_VSL_Stat_Pr5_ST3, Rsrv1_StWhl_Sw_CruiseCtrl_VSL_Stat_Pr5_ST3, SQC_StWhl_Sw_CruiseCtrl_VSL_Stat_Pr5_ST3, StWhl_Sw_Cancel_Psd_ST3, StWhl_Sw_CruiseCtrl_Off_Psd_ST3, StWhl_Sw_CruiseCtrl_Select_Psd_ST3, StWhl_Sw_Dist_Minus_Psd_ST3, StWhl_Sw_Dist_Plus_Psd_ST3, StWhl_Sw_Dist_Tgl_Psd_ST3, StWhl_Sw_Dn10_Set_Psd_ST3, StWhl_Sw_Dn1_Psd_ST3, StWhl_Sw_HAD1_Psd_ST3, StWhl_Sw_HAD2_Psd_ST3, StWhl_Sw_Mode_Psd_ST3, StWhl_Sw_Resume_Psd_ST3, StWhl_Sw_Up10_Set_Psd_ST3, StWhl_Sw_Up1Dn1_StepSize_ST3, StWhl_Sw_Up1_Psd_ST3, StWhl_Sw_VSL_Off_Psd_ST3, StWhl_Sw_VSL_Select_Psd_ST3]  # Steering wheel tip switches for Cruise Control / Variable Speed Limiter state
package /DataConstraints
  range c02_EVC_Stat: raw 1..3  # 02_EVC_Stat
  range c08_0_255_1_SNA_na: phys 0..255, raw 0..255  # 08_0-255_1_SNA=-
  range c08_0_255_1_SNA_na2: raw 0..255  # 08_0-255_1_SNA=-
  range c16_CRC_woSNA: raw 0..65535  # 16_CRC_w/oSNA
package /DataTypes/CompuMethods
  compu method c02_EVC_Stat: 1=I_C02_EVC_STAT_PROG (PROG) (programmed), 2=I_C02_EVC_STAT_REQ (REQ) (request), 3=I_C02_EVC_STAT_SNA (SNA) (SNA value from data type)  # EVC message status
  compu method c02_NPsd_Psd_Flt: 0=I_C02_NPSD_PSD_FLT_NPSD (NPSD) (Not pressed), 1=I_C02_NPSD_PSD_FLT_PSD (PSD) (Pressed), 2=I_C02_NPSD_PSD_FLT_FLT (FLT) (Fault), 3=I_C02_NPSD_PSD_FLT_SNA (SNA) (SNA value from data type)
package /DataTypes/ImplementationDataTypes
  20 x std cpp implementation data type:
    REC_CamSensSoil_MPC_ST3_cp6wyrd9cg7ec7y2w3khz1gyt: category=STRUCTURE, type-emitter=TYPE_EMITTER_ARA
      namespaces:
        symbol props DataTypes
        symbol props NS_REC_CamSensSoil_MPC_ST3_cp6wyrd9cg7ec7y2w3khz1gyt
      5 x cpp implementation data type element, all with is-optional=false, type-reference=bool:
        CamSensSoil_CMS_IconDisp_Rq_MPC_ST3
        CamSensSoil_IHC_IconDisp_Rq_MPC_ST3
        CamSensSoil_LDP_IconDisp_Rq_MPC_ST3
        CamSensSoil_MsgDisp_Rq_MPC_ST3
        CamSensSoil_TSA_IconDisp_Rq_MPC_ST3
    REC_DI_Odo_Pr5_ST3_9t50popkpz30is106xpis1iyh: category=STRUCTURE, type-emitter=TYPE_EMITTER_ARA
      namespaces:
        symbol props DataTypes
        symbol props REC_DI_Odo_Pr5_ST3_9t50popkpz30is106xpis1iyh
      cpp implementation data type element Odo_ST3: is-optional=false, type-reference=uint32_t
    REC_EVC_CfgBit_01_26_Pr5_ST3_2nibgl9yx8nj74mt7kvhiab7f: category=STRUCTURE, type-emitter=TYPE_EMITTER_ARA
      namespaces:
        symbol props DataTypes
        symbol props REC_EVC_CfgBit_01_26_Pr5_ST3_2nibgl9yx8nj74mt7kvhiab7f
      41 x cpp implementation data type element, all with is-optional=false:
        CRC_EVC_CfgBit_01_26_Pr5_ST3: type-reference=uint16_t
        EVC_01_494_Avl_ST3: type-reference=bool
        EVC_02_498_Avl_ST3: type-reference=bool
        EVC_03_623_Avl_ST3: type-reference=bool
        EVC_04_625_Avl_ST3: type-reference=bool
        EVC_05_830_Avl_ST3: type-reference=bool
        EVC_06_835_Avl_ST3: type-reference=bool
        EVC_07_460_Avl_ST3: type-reference=bool
        EVC_08_AddEquip_Avl_ST3: type-reference=bool
        EVC_09_AddEquip_Avl_ST3: type-reference=bool
        EVC_0A_AddEquip_Avl_ST3: type-reference=bool
        EVC_0B_AddEquip_Avl_ST3: type-reference=bool
        EVC_0C_465_Avl_ST3: type-reference=bool
        EVC_0D_470_Avl_ST3: type-reference=bool
        EVC_0E_479_Avl_ST3: type-reference=bool
        EVC_0F_AddEquip_Avl_ST3: type-reference=bool
        EVC_{10..13}_AddEquip_Avl_ST3: type-reference=bool
        EVC_15_MED2_Avl_ST3: type-reference=bool
        EVC_16_M013_Avl_ST3: type-reference=bool
        EVC_17_M014_Avl_ST3: type-reference=bool
        EVC_18_M016_Avl_ST3: type-reference=bool
        EVC_19_M005_Avl_ST3: type-reference=bool
        EVC_1A_AddEquip_Avl_ST3: type-reference=bool
        EVC_1B_MEF2_Avl_ST3: type-reference=bool
        EVC_1C_MEF3_Avl_ST3: type-reference=bool
        EVC_20_487_Avl_ST3: type-reference=bool
        EVC_21_488_Avl_ST3: type-reference=bool
        EVC_22_489_Avl_ST3: type-reference=bool
        EVC_23_490_Avl_ST3: type-reference=bool
        EVC_24_486_Avl_ST3: type-reference=bool
        EVC_25_AddEquip_Avl_ST3: type-reference=bool
        EVC_26_459_Avl_ST3: type-reference=bool
        EVC_CfgBit_01_26_Stat_ST3: type-reference=uint8_t
        SQC_EVC_CfgBit_01_26_Pr5_ST3: type-reference=uint8_t
        EVC_1F_215_Avl_ST3: type-reference=bool
        EVC_1D_201_Avl_ST3: type-reference=bool
        EVC_1E_216_Avl_ST3: type-reference=bool
        EVC_14_M035_Avl_ST3: type-reference=bool
    REC_EVC_CfgBit_73_98_Pr5_ST3_9w3nb2gl752ewx8w6kdqei5ll: category=STRUCTURE, type-emitter=TYPE_EMITTER_ARA
      namespaces:
        symbol props DataTypes
        symbol props REC_EVC_CfgBit_73_98_Pr5_ST3_9w3nb2gl752ewx8w6kdqei5ll
      41 x cpp implementation data type element, all with is-optional=false:
        CRC_EVC_CfgBit_73_98_Pr5_ST3: type-reference=uint16_t
        EVC_8D_258_Avl_ST3: type-reference=bool
        EVC_74_476_Avl_ST3: type-reference=bool
        EVC_8C_243_Avl_ST3: type-reference=bool
        EVC_76_513_Avl_ST3: type-reference=bool
        EVC_7E_218_Avl_ST3: type-reference=bool
        EVC_73_501_Avl_ST3: type-reference=bool
        EVC_7D_220_Avl_ST3: type-reference=bool
        EVC_75_AddEquip_Avl_ST3: type-reference=bool
        EVC_7F_235_Avl_ST3: type-reference=bool
        EVC_82_440_Avl_ST3: type-reference=bool
        EVC_89_233_Avl_ST3: type-reference=bool
        EVC_8A_234_Avl_ST3: type-reference=bool
        EVC_80_AddEquip_Avl_ST3: type-reference=bool
        EVC_83_AddEquip_Avl_ST3: type-reference=bool
        EVC_97_950_Avl_ST3: type-reference=bool
        EVC_98_952_Avl_ST3: type-reference=bool
        EVC_81_AddEquip_Avl_ST3: type-reference=bool
        EVC_7C_503_Avl_ST3: type-reference=bool
        EVC_8B_292_Avl_ST3: type-reference=bool
        EVC_8E_239_Avl_ST3: type-reference=bool
        EVC_8F_266_Avl_ST3: type-reference=bool
        EVC_92_382_Avl_ST3: type-reference=bool
        EVC_93_383_Avl_ST3: type-reference=bool
        EVC_94_K29_Avl_ST3: type-reference=bool
        EVC_95_AddEquip_Avl_ST3: type-reference=bool
        EVC_CfgBit_73_98_Stat_ST3: type-reference=uint8_t
        SQC_EVC_CfgBit_73_98_Pr5_ST3: type-reference=uint8_t
        EVC_96_430_Avl_ST3: type-reference=bool
        EVC_77_299_Avl_ST3: type-reference=bool
        EVC_78_306_Avl_ST3: type-reference=bool
        EVC_79_AddEquip_Avl_ST3: type-reference=bool
        EVC_7A_AddEquip_Avl_ST3: type-reference=bool
        EVC_84_504_Avl_ST3: type-reference=bool
        EVC_85_27U_Avl_ST3: type-reference=bool
        EVC_86_K00_Avl_ST3: type-reference=bool
        EVC_87_200_Avl_ST3: type-reference=bool
        EVC_88_384_Avl_ST3: type-reference=bool
        EVC_90_546_Avl_ST3: type-reference=bool
        EVC_91_271_Avl_ST3: type-reference=bool
        EVC_7B_551_Avl_ST3: type-reference=bool
    REC_EVC_CfgBit_99_BE_Pr5_ST3_3ic8vtrgsvug14f7o5f9ow0r3: category=STRUCTURE, type-emitter=TYPE_EMITTER_ARA
      namespaces:
        symbol props DataTypes
        symbol props REC_EVC_CfgBit_99_BE_Pr5_ST3_3ic8vtrgsvug14f7o5f9ow0r3
      cpp implementation data type element EVC_CfgBit_99_BE_Stat_ST3: is-optional=false, type-reference=uint8_t
      cpp implementation data type element EVC_9F_608_Avl_ST3: is-optional=false, type-reference=bool
      cpp implementation data type element EVC_A0_628_Avl_ST3: is-optional=false, type-reference=bool
    REC_EVC_CfgList_01_08_Pr5_ST3_14lojwgkcazelrb438elf5h0j: category=STRUCTURE, type-emitter=TYPE_EMITTER_ARA
      namespaces:
        symbol props DataTypes
        symbol props REC_EVC_CfgList_01_08_Pr5_ST3_14lojwgkcazelrb438elf5h0j
      11 x cpp implementation data type element, all with is-optional=false:
        CRC_EVC_CfgList_01_08_Pr5_ST3: type-reference=uint16_t
        EVC_CfgList_01_08_Stat_ST3: type-reference=uint8_t
        EVC_List01_BodyStyle_ST3: type-reference=uint8_t
        EVC_List02_VehLine_ST3: type-reference=uint8_t
        EVC_List03_StStyle_ST3: type-reference=uint8_t
        EVC_List04_YrOfModf_2_ST3: type-reference=uint8_t
        EVC_List05_YrOfModf_1_ST3: type-reference=uint8_t
        EVC_List06_Country_ST3: type-reference=uint8_t
        EVC_List07_TxStyle_ST3: type-reference=uint8_t
        EVC_List08_HL_Style_ST3: type-reference=uint8_t
        SQC_EVC_CfgList_01_08_Pr5_ST3: type-reference=uint8_t
    REC_Ign_Stat_Pr5_ST3_b0ko81o0x5jgvwtduf99gvzi0: category=STRUCTURE, type-emitter=TYPE_EMITTER_ARA
      namespaces:
        symbol props DataTypes
        symbol props REC_Ign_Stat_Pr5_ST3_b0ko81o0x5jgvwtduf99gvzi0
      cpp implementation data type element ISw_Stat_ST3: is-optional=false, type-reference=uint8_t
    REC_PT4_PTCoor4_Pr5_ST3_a1o7mhv0xy8ny0vccjf09ttgc: category=STRUCTURE, type-emitter=TYPE_EMITTER_ARA
      namespaces:
        symbol props DataTypes
        symbol props REC_PT4_PTCoor4_Pr5_ST3_a1o7mhv0xy8ny0vccjf09ttgc
      6 x cpp implementation data type element, all with is-optional=false:
        CRC_PT4_PTCoor4_Pr5_ST3: type-reference=uint16_t
        PT4_PTCoor_PT_Rdy_ST3: type-reference=uint8_t
        SQC_PT4_PTCoor4_Pr5_ST3: type-reference=uint8_t
        PT4_PTCoor_EngStartPN14_Stat_ST3: type-reference=uint8_t
        PT4_PTCoor_SSA_EngSp_ST3: type-reference=uint8_t
        Rsrv1_PT4_PTCoor_PT_Rdy_Pr5_ST3: type-reference=uint8_t
    REC_activateSarStorage0131VcEventType_t: category=STRUCTURE, type-emitter=TYPE_EMITTER_ARA
      namespaces:
        symbol props DataTypes
        symbol props NS_REC_activateSarStorage0131VcEventType_t
      cpp implementation data type element sarDataStorageStatus: is-optional=false, type-reference=uint8_t
    REC_configureSarTriggerEvents0136VcEventType_t: category=STRUCTURE, type-emitter=TYPE_EMITTER_ARA
      namespaces:
        symbol props DataTypes
        symbol props NS_REC_configureSarTriggerEvents0136VcEventType_t
      cpp implementation data type element triggerEventActivationStatusByte1: is-optional=false, type-reference=uint8_t
      cpp implementation data type element triggerEventActivationStatusByte2: is-optional=false, type-reference=uint8_t
    REC_vechicleInformation0400VcEventType_t: category=STRUCTURE, type-emitter=TYPE_EMITTER_ARA
      namespaces:
        symbol props DataTypes
        symbol props NS_REC_vechicleInformation0400VcEventType_t
      9 x cpp implementation data type element, all with is-optional=false, type-reference=uint8_t:
        body_style
        veh_line
        amg_type
        guard_lvl_b4
        reserved
        guard_lvl_b7
        hybrid_avl
        plugin_hybrid_avl
        veh_backdoors_avl
    STD_UUCategory: category=STRUCTURE, type-emitter=TYPE_EMITTER_ARA
      namespaces:
        symbol props DataTypes
        symbol props STD_UUCategory
      cpp implementation data type element main: is-optional=false, type-reference=uint8_t
      cpp implementation data type element sub: is-optional=false, type-reference=uint16_t
      cpp implementation data type element specific: is-optional=false, type-reference=uint16_t
    VSLim_GetCapabilities_Out_b0ko81o0x5jgvwtduf99gvzi0: category=STRUCTURE, type-emitter=TYPE_EMITTER_ARA
      namespaces:
        symbol props DataTypes
        symbol props VSLim_GetCapabilities_Out_b0ko81o0x5jgvwtduf99gvzi0
      cpp implementation data type element minimum_speed_limit: is-optional=false, type-reference=uint16_t
    VSLim_LimitConditions: category=STRUCTURE, type-emitter=TYPE_EMITTER_ARA
      namespaces:
        symbol props DataTypes
        symbol props NS_VSLim_LimitConditions
      4 x cpp implementation data type element, all with is-optional=false:
        universally_unique_category: type-reference=STD_UUCategory
        speed_limit: type-reference=uint16_t
        no_speed_limit: type-reference=uint8_t
        limiter_activity: type-reference=uint8_t
    VSLim_RequestLimit_In: category=STRUCTURE, type-emitter=TYPE_EMITTER_ARA
      namespaces:
        symbol props DataTypes
        symbol props VSLim_RequestLimit_In
      5 x cpp implementation data type element, all with is-optional=false:
        universally_unique_category: type-reference=STD_UUCategory
        timeout: type-reference=uint16_t
        limit_type: type-reference=uint8_t
        activeness_type: type-reference=uint8_t
        speed_limit: type-reference=uint16_t
    VSLim_SpeedLimiterState_71njeubj9ico1p8v4pmslfcno: category=STRUCTURE, type-emitter=TYPE_EMITTER_ARA
      namespaces:
        symbol props DataTypes
        symbol props VSLim_SpeedLimiterState_71njeubj9ico1p8v4pmslfcno
      cpp implementation data type element variable: is-optional=false, type-reference=VSLim_LimitConditions
      cpp implementation data type element permanent: is-optional=false, type-reference=VSLim_LimitConditions
    bool: category=VALUE  # boolean
    uint16_t: category=VALUE, type-emitter=cstdint  # unsigned integer 16bit
    uint32_t: category=VALUE, type-emitter=cstdint  # unsigned integer 32bit
    uint8_t: category=VALUE, type-emitter=cstdint  # unsigned integer 8bit
package /DataTypes/ModelManagement
  mode declaration group MachineStates: initial-mode=Startup
    5 x mode:
      Running: value=0
      Restart: value=3
      Off: value=4
      Startup: value=1
      Shutdown: value=2
package /DataTypes/Units
  unit NoUnit: display-name=NoUnit
  unit km: display-name=km
package /Machine
  machine IDC6_M_P1_XAVIER: machine-design=IDC_Adpative
    function-groups:
      mode declaration group prototype IDC6_M_ModeDeclarationGroup: type=MachineStates
      mode declaration group prototype MachineState: type=MachineStates
package /Machine/ProcessToMachineMappings
  process to machine mapping set SWtoHWMappings
    7 x process to machine mapping, all with machine=IDC6_M_P1_XAVIER:
      PTMM_TransmissionManager_ROV_IDC6M: process=TransmissionManager_ROV
      SelfDiagnosticAgent_IDC6_M: process=SelfDiagnosticAgent
      SwHwMapping14707: process=Process_X6AA_Cnfg_Mngr_SWC
      SwHwMapping14709: process=Process_X6AA_Dummy_SWC_1
      SwHwMapping14710: process=Process_X6AA_Dummy_SWC_2
      SwHwMapping14711: process=Process_X6AA_DLT_SWC
      SwHwMapping14712: process=Process_X6AA_Ressource_SWC
package /Machine/StartupConfigSets
  startup config set startupConf
    startup config STARTUP_CONFIG_DEFAULT: scheduling-policy=SCHEDULING-POLICY-ROUND-ROBIN, scheduling-priority=20, startup-option{option-argument=./etc/application.json, option-kind=COMMAND-LINE-SHORT-FORM, option-name=c}
package /ServiceInstances
  provided someip service instance PSI_SuppFunctions_MPC_Service_ST3_IDC_M_P_MAIN_20: service-interface=SomeIpSI_SuppFunctions_MPC_Service_ST3, someip-event-props=event=SomeIpEv_CamSensSoil_MPC_ST3, sd-server-config=ServerSd_PSI_SuppFunctions_MPC_Service_ST3_IDC_M_P_MAIN_20, service-instance-id=8
    someip provided event group SomeIpEG_CamSensSoil: event-group=EG_17672_0_CamSensSoil_MPC, multicast-threshold=7, sd-server-event-group-timing-config=ServerEgSd_SomeIpEG_CamSensSoil
  provided someip service instance PSI_X6AA_Dummy_B2_Service_Reserved: service-interface=SomeIpSI_DummySWC_2_To_Cnfg_Mngr, someip-event-props=event=SomeIpEv_CalculationResult, sd-server-config=ServerSd_PSI_X6AA_Dummy_B2_Service_Reserved, service-instance-id=9
    someip provided event group SomeIpEG_DummySWC_2_To_Cnfg_Mngr: event-group=EG_DummySWC_2_To_Cnfg_Mngr, multicast-threshold=0, sd-server-event-group-timing-config=ServerEgSd_SomeIpEG_DummySWC_2_To_Cnfg_Mngr
  provided user defined service instance PUDSI_X6AA_Cnfg_Mngr_Service_Reserved: service-interface=UDSI_X6AA_Cnfg_Mngr_Service_Reserved
  7 x required someip service instance, all with required-minor-version=0:
    CSI_DI_OdoSpeedometer_Service_ST3_IDC_M_P_MAIN_20: service-interface=SomeIpSI_DI_OdoSpeedometer_Service_ST3, required-service-instance-id=1, sd-client-config=ClientSd_CSI_DI_OdoSpeedometer_Service_ST3_IDC_M_P_MAIN_20
      someip required event group SomeIpEG_12804_0_DI_Master_Odometer: event-group=EG_12804_0_DI_Master_Odometer, sd-client-event-group-timing-config=ClientEgSd_SomeIpEG_12804_0_DI_Master_Odometer
    CSI_ExtVehicleConfig_Service_ST3_IDC_M_P_MAIN_20: service-interface=SomeIpSI_ExtVehicleConfig_Service_ST3, required-service-instance-id=2, sd-client-config=ClientSd_CSI_ExtVehicleConfig_Service_ST3_IDC_M_P_MAIN_20
      someip required event group SomeIpEG_640_0_EVC_Cfg: event-group=EG_640_0_EVC_Cfg, sd-client-event-group-timing-config=ClientEgSd_SomeIpEG_640_0_EVC_Cfg
    CSI_Immobilizer_Master_Service_ST3: service-interface=SomeIpSI_Immobilizer_Master_Service_ST3, required-service-instance-id=3, sd-client-config=ClientSd_CSI_Immobilizer_Master_Service_ST3
      someip required event group SomeIpEG_128_0_Ign_Stat: event-group=EG_128_0_Ign_Stat, sd-client-event-group-timing-config=ClientEgSd_SomeIpEG_128_0_Ign_Stat
    CSI_PN14_Master_Service_ST3_IDC_M_P_MAIN_20: service-interface=SomeIpSI_PN14_Master_Service_ST3, required-service-instance-id=4, sd-client-config=ClientSd_CSI_PN14_Master_Service_ST3_IDC_M_P_MAIN_20
      someip required event group SomeIpEG_14720_0_PN14_Master: event-group=EG_14720_0_PN14_Master, sd-client-event-group-timing-config=ClientEgSd_SomeIpEG_14720_0_PN14_Master
    CSI_PT4_PTCoor_Service_ST3_IDC_M_P_MAIN_20: service-interface=SomeIpSI_PT4_PTCoor_Service_ST3, required-service-instance-id=5, sd-client-config=ClientSd_CSI_PT4_PTCoor_Service_ST3_IDC_M_P_MAIN_20
      someip required event group SomeIpEG_14596_0_PT4_PTCoor4: event-group=EG_14596_0_PT4_PTCoor4, sd-client-event-group-timing-config=ClientEgSd_SomeIpEG_14596_0_PT4_PTCoor4
    CSI_SpeedLimiter_IDC_M_P_MAIN_20: service-interface=SomeIpSI_SpeedLimiter, method-request-propss=[method=SomeIpMeth_GetCapabilities, method=SomeIpMeth_RequestSpeedLimit], required-service-instance-id=11, sd-client-config=ClientSd_CSI_SpeedLimiter_IDC_M_P_MAIN_20
      someip required event group SomeIpEG_7826_1_AllEvents: event-group=EG_7826_1_AllEvents, sd-client-event-group-timing-config=ClientEgSd_SomeIpEG_7826_1_AllEvents
    CSI_X6AA_Dummy_B2_Service_Reserved: service-interface=SomeIpSI_DummySWC_2_To_Cnfg_Mngr, required-service-instance-id=7, sd-client-config=ClientSd_CSI_X6AA_Dummy_B2_Service_Reserved
      someip required event group SomeIpEG_DummySWC_2_To_Cnfg_Mngr: event-group=EG_DummySWC_2_To_Cnfg_Mngr, sd-client-event-group-timing-config=ClientEgSd_SomeIpEG_DummySWC_2_To_Cnfg_Mngr
  required user defined service instance CUDSI_X6AA_Cnfg_Mngr_Service_Reserved: service-interface=UDSI_X6AA_Cnfg_Mngr_Service_Reserved
package /ServiceInstances/ServiceInstanceToMachineMappings
  9 x someip service instance to machine mapping, all with communication-connector=IDC_M_P_MAIN_20, udp-port=40000:
    SI_CamSensSoil_MPC_ST3_IDC_M_P_MAIN_20Mapping: service-instance=PSI_SuppFunctions_MPC_Service_ST3_IDC_M_P_MAIN_20
    SI_DI_OdoSpeedometer_Service_ST3_IDC_M_P_MAIN_20Mapping: service-instance=CSI_DI_OdoSpeedometer_Service_ST3_IDC_M_P_MAIN_20
    SI_DummySWC_2_To_Cnfg_Mngr_IDC_M_P_MAIN_20Mapping: service-instance=CSI_X6AA_Dummy_B2_Service_Reserved
    SI_DummySWC_2_To_Cnfg_Mngr_NDAS_ADAS6Mapping: service-instance=PSI_X6AA_Dummy_B2_Service_Reserved
    SI_ExtVehicleConfig_Service_ST3_IDC_M_P_MAIN_20Mapping: service-instance=CSI_ExtVehicleConfig_Service_ST3_IDC_M_P_MAIN_20
    SI_Immobilizer_Master_Service_ST3_IDC_M_P_MAIN_20Mapping: service-instance=CSI_Immobilizer_Master_Service_ST3
    SI_PN14_Master_Service_ST3_IDC_M_P_MAIN_20Mapping: service-instance=CSI_PN14_Master_Service_ST3_IDC_M_P_MAIN_20
    SI_PT4_PTCoor_Service_ST3_IDC_M_P_MAIN_20Mapping: service-instance=CSI_PT4_PTCoor_Service_ST3_IDC_M_P_MAIN_20
    SI_SpeedLimiter_IDC_M_P_MAIN_20Mapping: service-instance=CSI_SpeedLimiter_IDC_M_P_MAIN_20
package /ServiceInstances/ServiceInstanceToPortPrototypeMappings
  11 x service instance to port prototype mapping:
    CSI_DI_OdoSpeedometer_Service_ST3_IDC_M_P_MAIN_20__SelfDiagnosticAgent_ServicePortMapping: port-prototype=SelfDiagnosticAgentExecutableRootSwc.AdaptiveRequiredPortType115, process=SelfDiagnosticAgent, service-instance=CSI_DI_OdoSpeedometer_Service_ST3_IDC_M_P_MAIN_20
    CSI_ExtVehicleConfig_Service_ST3_IDC_M_P_MAIN_20__X6AA_Cnfg_Mngr_SWC_ServicePortMapping: port-prototype=X6AA_Cnfg_Mngr_ExecutableRootSwc.R_ExtVehicleConfig_Service_ST3, process=Process_X6AA_Cnfg_Mngr_SWC, service-instance=CSI_ExtVehicleConfig_Service_ST3_IDC_M_P_MAIN_20
    CSI_Immobilizer_Master_Service_ST3__SelfDiagnosticAgent_ServicePortMapping: port-prototype=SelfDiagnosticAgentExecutableRootSwc.R_Immobilizer_Master_Service_ST3, process=SelfDiagnosticAgent, service-instance=CSI_Immobilizer_Master_Service_ST3
    CSI_PN14_Master_Service_ST3_IDC_M_P_MAIN_20__SelfDiagnosticAgent_ServicePortMapping: port-prototype=SelfDiagnosticAgentExecutableRootSwc.R_SI_PN14_Master_Service_ST3, process=SelfDiagnosticAgent, service-instance=CSI_PN14_Master_Service_ST3_IDC_M_P_MAIN_20
    CSI_PT4_PTCoor_Service_ST3_IDC_M_P_MAIN_20__SelfDiagnosticAgent_ServicePortMapping: port-prototype=SelfDiagnosticAgentExecutableRootSwc.R_P_PT4_PTCoor4_Pr5_ST3, process=SelfDiagnosticAgent, service-instance=CSI_PT4_PTCoor_Service_ST3_IDC_M_P_MAIN_20
    CSI_SpeedLimiter_IDC_M_P_MAIN_20__TransmissionManager_ROV_ServicePortMapping: port-prototype=TransmissionManager_ROVExecutableRootSwc.R_SpeedLimiter, process=TransmissionManager_ROV, service-instance=CSI_SpeedLimiter_IDC_M_P_MAIN_20
    CSI_X6AA_Dummy_B2_Service_Reserved__X6AA_Cnfg_Mngr_SWC_ServicePortMapping: port-prototype=X6AA_Cnfg_Mngr_ExecutableRootSwc.AdaptiveRequiredPortType108, process=Process_X6AA_Cnfg_Mngr_SWC, service-instance=CSI_X6AA_Dummy_B2_Service_Reserved
    CUDSI_X6AA_Cnfg_Mngr_Service_Reserved__X6AA_Dummy_SWC_1_ServicePortMapping: port-prototype=X6AA_Dummy_SWC_1_ExecutableRootSwc.AdaptiveRequiredPortType110, process=Process_X6AA_Dummy_SWC_1, service-instance=CUDSI_X6AA_Cnfg_Mngr_Service_Reserved
    PSI_SuppFunctions_MPC_Service_ST3_IDC_M_P_MAIN_20__TransmissionManager_ROV_ServicePortMapping: port-prototype=TransmissionManager_ROVExecutableRootSwc.P_CamSensSoil, process=TransmissionManager_ROV, service-instance=PSI_SuppFunctions_MPC_Service_ST3_IDC_M_P_MAIN_20
    PSI_X6AA_Dummy_B2_Service_Reserved__X6AA_Dummy_SWC_2_ServicePortMapping: port-prototype=X6AA_Dummy_SWC_2_ExecutableRootSwc.AdaptiveProvidedPortType90, process=Process_X6AA_Dummy_SWC_2, service-instance=PSI_X6AA_Dummy_B2_Service_Reserved
    PUDSI_PUDSI_X6AA_Cnfg_Mngr_Service_Reserved__X6AA_Cnfg_Mngr_SWC: port-prototype=X6AA_Cnfg_Mngr_ExecutableRootSwc.AdaptiveProvidedPortType89, process=Process_X6AA_Cnfg_Mngr_SWC, service-instance=PUDSI_X6AA_Cnfg_Mngr_Service_Reserved
package /ServiceInstances/ServiceInstanceToSignalMappingSets
  6 x service instance to signal mapping set:
    CSI_DI_OdoSpeedometer_Service_ST3_IDC_M_P_MAIN_20_MappingSet
      service instance to signal mapping CSI_DI_OdoSpeedometer_Service_ST3_IDC_M_P_MAIN_20_Ev_DI_Odo_Pr5_ST3: service-instance=CSI_DI_OdoSpeedometer_Service_ST3_IDC_M_P_MAIN_20
        event-element-mappings:
          {data-prototype-in-service-interface=element-in-impl-datatype={root-data-prototype=Ev_DI_Odo_Pr5_ST3, target-data-prototype=Odo_ST3}, i-signal-triggering=Odo_ST3_dtsso69qta8a4klmh5xy506fa}
          data-prototype-in-service-interface=Ev_DI_Odo_Pr5_ST3, i-signal-triggering=DI_Odo_Pr5_ST3_e68xmtlkywxgxsdwekdjjhw3t_8ba8blhjrrxh5jkp0iefdb5e6
    CSI_ExtVehicleConfig_Service_ST3_IDC_M_P_MAIN_20_MappingSet
      4 x service instance to signal mapping, all with service-instance=CSI_ExtVehicleConfig_Service_ST3_IDC_M_P_MAIN_20:
        CSI_ExtVehicleConfig_Service_ST3_IDC_M_P_MAIN_20_Ev_EVC_CfgBit_01_26_Pr5_ST3
          event-element-mappings:
            {data-prototype-in-service-interface=element-in-impl-datatype={root-data-prototype=Ev_EVC_CfgBit_01_26_Pr5_ST3, target-data-prototype=CRC_EVC_CfgBit_01_26_Pr5_ST3}, i-signal-triggering=CRC_EVC_CfgBit_01_26_Pr5_ST3_bsd95ad18z52w65cml31yxzud}
            {data-prototype-in-service-interface=element-in-impl-datatype={root-data-prototype=Ev_EVC_CfgBit_01_26_Pr5_ST3, target-data-prototype=EVC_01_494_Avl_ST3}, i-signal-triggering=EVC_01_494_Avl_ST3_2pwk5g7v8238uzuox68bf2kaj}
            {data-prototype-in-service-interface=element-in-impl-datatype={root-data-prototype=Ev_EVC_CfgBit_01_26_Pr5_ST3, target-data-prototype=EVC_02_498_Avl_ST3}, i-signal-triggering=EVC_02_498_Avl_ST3_31p0dj8dvtmzmju6sk6ej36b4}
            {data-prototype-in-service-interface=element-in-impl-datatype={root-data-prototype=Ev_EVC_CfgBit_01_26_Pr5_ST3, target-data-prototype=EVC_03_623_Avl_ST3}, i-signal-triggering=EVC_03_623_Avl_ST3_bb044qv1038jtd7lbw7ene4qa}
            {data-prototype-in-service-interface=element-in-impl-datatype={root-data-prototype=Ev_EVC_CfgBit_01_26_Pr5_ST3, target-data-prototype=EVC_04_625_Avl_ST3}, i-signal-triggering=EVC_04_625_Avl_ST3_adi6hebw95iols6jo39fji68y}
            {data-prototype-in-service-interface=element-in-impl-datatype={root-data-prototype=Ev_EVC_CfgBit_01_26_Pr5_ST3, target-data-prototype=EVC_05_830_Avl_ST3}, i-signal-triggering=EVC_05_830_Avl_ST3_3u7khav7jg2wkws7s5gjgxjee}
            {data-prototype-in-service-interface=element-in-impl-datatype={root-data-prototype=Ev_EVC_CfgBit_01_26_Pr5_ST3, target-data-prototype=EVC_06_835_Avl_ST3}, i-signal-triggering=EVC_06_835_Avl_ST3_aqstgobd7lvozpsvca8oyvoza}
            {data-prototype-in-service-interface=element-in-impl-datatype={root-data-prototype=Ev_EVC_CfgBit_01_26_Pr5_ST3, target-data-prototype=EVC_07_460_Avl_ST3}, i-signal-triggering=EVC_07_460_Avl_ST3_2my2oq62qqg0hbe4q4fcpd6m2}
            {data-prototype-in-service-interface=element-in-impl-datatype={root-data-prototype=Ev_EVC_CfgBit_01_26_Pr5_ST3, target-data-prototype=EVC_08_AddEquip_Avl_ST3}, i-signal-triggering=EVC_08_AddEquip_Avl_ST3_ce9p52icoo6hlkg85qutm6xk9}
            {data-prototype-in-service-interface=element-in-impl-datatype={root-data-prototype=Ev_EVC_CfgBit_01_26_Pr5_ST3, target-data-prototype=EVC_09_AddEquip_Avl_ST3}, i-signal-triggering=EVC_09_AddEquip_Avl_ST3_ewa8gpj05kye9as4665r0ydyo}
            {data-prototype-in-service-interface=element-in-impl-datatype={root-data-prototype=Ev_EVC_CfgBit_01_26_Pr5_ST3, target-data-prototype=EVC_0A_AddEquip_Avl_ST3}, i-signal-triggering=EVC_0A_AddEquip_Avl_ST3_1ozs1xm8ccvda23basqlg0bj7}
            {data-prototype-in-service-interface=element-in-impl-datatype={root-data-prototype=Ev_EVC_CfgBit_01_26_Pr5_ST3, target-data-prototype=EVC_0B_AddEquip_Avl_ST3}, i-signal-triggering=EVC_0B_AddEquip_Avl_ST3_nd0eshz9596btj2l7z0j8qib}
            {data-prototype-in-service-interface=element-in-impl-datatype={root-data-prototype=Ev_EVC_CfgBit_01_26_Pr5_ST3, target-data-prototype=EVC_0C_465_Avl_ST3}, i-signal-triggering=EVC_0C_465_Avl_ST3_15oate47byoo3xgadik0rjri6}
            {data-prototype-in-service-interface=element-in-impl-datatype={root-data-prototype=Ev_EVC_CfgBit_01_26_Pr5_ST3, target-data-prototype=EVC_0D_470_Avl_ST3}, i-signal-triggering=EVC_0D_470_Avl_ST3_4jd08qqub5zeovm2lqw48z7o8}
            {data-prototype-in-service-interface=element-in-impl-datatype={root-data-prototype=Ev_EVC_CfgBit_01_26_Pr5_ST3, target-data-prototype=EVC_0E_479_Avl_ST3}, i-signal-triggering=EVC_0E_479_Avl_ST3_7pk5c7ttg8qgzpne9two8b803}
            {data-prototype-in-service-interface=element-in-impl-datatype={root-data-prototype=Ev_EVC_CfgBit_01_26_Pr5_ST3, target-data-prototype=EVC_0F_AddEquip_Avl_ST3}, i-signal-triggering=EVC_0F_AddEquip_Avl_ST3_dmuwfmosn76q3sor138zifl8m}
            {data-prototype-in-service-interface=element-in-impl-datatype={root-data-prototype=Ev_EVC_CfgBit_01_26_Pr5_ST3, target-data-prototype=EVC_10_AddEquip_Avl_ST3}, i-signal-triggering=EVC_10_AddEquip_Avl_ST3_1yqt8i0obndtf3iive2bhgmue}
            {data-prototype-in-service-interface=element-in-impl-datatype={root-data-prototype=Ev_EVC_CfgBit_01_26_Pr5_ST3, target-data-prototype=EVC_11_AddEquip_Avl_ST3}, i-signal-triggering=EVC_11_AddEquip_Avl_ST3_81cx8n1p369uoz8xsbnde06mf}
            {data-prototype-in-service-interface=element-in-impl-datatype={root-data-prototype=Ev_EVC_CfgBit_01_26_Pr5_ST3, target-data-prototype=EVC_12_AddEquip_Avl_ST3}, i-signal-triggering=EVC_12_AddEquip_Avl_ST3_3qrrt40yjb7dlbrd2vgrq24jn}
            {data-prototype-in-service-interface=element-in-impl-datatype={root-data-prototype=Ev_EVC_CfgBit_01_26_Pr5_ST3, target-data-prototype=EVC_13_AddEquip_Avl_ST3}, i-signal-triggering=EVC_13_AddEquip_Avl_ST3_2pg3x1al4ybs64673mwzgwrat}
            {data-prototype-in-service-interface=element-in-impl-datatype={root-data-prototype=Ev_EVC_CfgBit_01_26_Pr5_ST3, target-data-prototype=EVC_14_M035_Avl_ST3}, i-signal-triggering=EVC_14_M035_Avl_ST3_dwer1jfptk6bvxd2kaqg8f7m8}
            {data-prototype-in-service-interface=element-in-impl-datatype={root-data-prototype=Ev_EVC_CfgBit_01_26_Pr5_ST3, target-data-prototype=EVC_15_MED2_Avl_ST3}, i-signal-triggering=EVC_15_MED2_Avl_ST3_2n85jfyx1tgbqopfou74jdqiz}
            {data-prototype-in-service-interface=element-in-impl-datatype={root-data-prototype=Ev_EVC_CfgBit_01_26_Pr5_ST3, target-data-prototype=EVC_16_M013_Avl_ST3}, i-signal-triggering=EVC_16_M013_Avl_ST3_950posn5ysxr57n9480sn9dhq}
            {data-prototype-in-service-interface=element-in-impl-datatype={root-data-prototype=Ev_EVC_CfgBit_01_26_Pr5_ST3, target-data-prototype=EVC_17_M014_Avl_ST3}, i-signal-triggering=EVC_17_M014_Avl_ST3_88ukdgoc9n59he41rje0moyeh}
            {data-prototype-in-service-interface=element-in-impl-datatype={root-data-prototype=Ev_EVC_CfgBit_01_26_Pr5_ST3, target-data-prototype=EVC_18_M016_Avl_ST3}, i-signal-triggering=EVC_18_M016_Avl_ST3_4c5ehaabtba76la4axfaq6r7a}
            {data-prototype-in-service-interface=element-in-impl-datatype={root-data-prototype=Ev_EVC_CfgBit_01_26_Pr5_ST3, target-data-prototype=EVC_19_M005_Avl_ST3}, i-signal-triggering=EVC_19_M005_Avl_ST3_3ufqw15dsih0vzt9mz9l8adk2}
            {data-prototype-in-service-interface=element-in-impl-datatype={root-data-prototype=Ev_EVC_CfgBit_01_26_Pr5_ST3, target-data-prototype=EVC_1A_AddEquip_Avl_ST3}, i-signal-triggering=EVC_1A_AddEquip_Avl_ST3_cjblgh1fhf7o7oxc4th6ztw64}
            {data-prototype-in-service-interface=element-in-impl-datatype={root-data-prototype=Ev_EVC_CfgBit_01_26_Pr5_ST3, target-data-prototype=EVC_1B_MEF2_Avl_ST3}, i-signal-triggering=EVC_1B_MEF2_Avl_ST3_6zo5hwq4ggjzz2oo0p6rbay1r}
            {data-prototype-in-service-interface=element-in-impl-datatype={root-data-prototype=Ev_EVC_CfgBit_01_26_Pr5_ST3, target-data-prototype=EVC_1C_MEF3_Avl_ST3}, i-signal-triggering=EVC_1C_MEF3_Avl_ST3_7licl1yh9boretzgcnqr522gz}
            {data-prototype-in-service-interface=element-in-impl-datatype={root-data-prototype=Ev_EVC_CfgBit_01_26_Pr5_ST3, target-data-prototype=EVC_1D_201_Avl_ST3}, i-signal-triggering=EVC_1D_201_Avl_ST3_73ctj6o3vdaoob4fuv4nsj2mw}
            {data-prototype-in-service-interface=element-in-impl-datatype={root-data-prototype=Ev_EVC_CfgBit_01_26_Pr5_ST3, target-data-prototype=EVC_1E_216_Avl_ST3}, i-signal-triggering=EVC_1E_216_Avl_ST3_e6gogfmf6dpg66hgz1zrmhkpe}
            {data-prototype-in-service-interface=element-in-impl-datatype={root-data-prototype=Ev_EVC_CfgBit_01_26_Pr5_ST3, target-data-prototype=EVC_1F_215_Avl_ST3}, i-signal-triggering=EVC_1F_215_Avl_ST3_6mpx41ptite8z0izcst93vk6u}
            {data-prototype-in-service-interface=element-in-impl-datatype={root-data-prototype=Ev_EVC_CfgBit_01_26_Pr5_ST3, target-data-prototype=EVC_20_487_Avl_ST3}, i-signal-triggering=EVC_20_487_Avl_ST3_bhahigsy2em07cxz1c47tgt1m}
            {data-prototype-in-service-interface=element-in-impl-datatype={root-data-prototype=Ev_EVC_CfgBit_01_26_Pr5_ST3, target-data-prototype=EVC_21_488_Avl_ST3}, i-signal-triggering=EVC_21_488_Avl_ST3_8zve4edhfgryx58ok8b9qxg95}
            {data-prototype-in-service-interface=element-in-impl-datatype={root-data-prototype=Ev_EVC_CfgBit_01_26_Pr5_ST3, target-data-prototype=EVC_22_489_Avl_ST3}, i-signal-triggering=EVC_22_489_Avl_ST3_7nj27b9nmbv4echniockfpdcb}
            {data-prototype-in-service-interface=element-in-impl-datatype={root-data-prototype=Ev_EVC_CfgBit_01_26_Pr5_ST3, target-data-prototype=EVC_23_490_Avl_ST3}, i-signal-triggering=EVC_23_490_Avl_ST3_70uz0kyfx4ra1xdq3yw0myv2l}
            {data-prototype-in-service-interface=element-in-impl-datatype={root-data-prototype=Ev_EVC_CfgBit_01_26_Pr5_ST3, target-data-prototype=EVC_24_486_Avl_ST3}, i-signal-triggering=EVC_24_486_Avl_ST3_ebg277l92qn74fm64z8y3o1v4}
            {data-prototype-in-service-interface=element-in-impl-datatype={root-data-prototype=Ev_EVC_CfgBit_01_26_Pr5_ST3, target-data-prototype=EVC_25_AddEquip_Avl_ST3}, i-signal-triggering=EVC_25_AddEquip_Avl_ST3_5pb4jyikm7guyp5s8wjgsp01s}
            {data-prototype-in-service-interface=element-in-impl-datatype={root-data-prototype=Ev_EVC_CfgBit_01_26_Pr5_ST3, target-data-prototype=EVC_26_459_Avl_ST3}, i-signal-triggering=EVC_26_459_Avl_ST3_57wjn9m6ke7ynmgu6sxa2twzs}
            {data-prototype-in-service-interface=element-in-impl-datatype={root-data-prototype=Ev_EVC_CfgBit_01_26_Pr5_ST3, target-data-prototype=EVC_CfgBit_01_26_Stat_ST3}, i-signal-triggering=EVC_CfgBit_01_26_Stat_ST3_6hnwtun7mjh4hqwr3xhi8whbl}
            {data-prototype-in-service-interface=element-in-impl-datatype={root-data-prototype=Ev_EVC_CfgBit_01_26_Pr5_ST3, target-data-prototype=SQC_EVC_CfgBit_01_26_Pr5_ST3}, i-signal-triggering=SQC_EVC_CfgBit_01_26_Pr5_ST3_ejotxg8e7obsib3ehqferiy1c}
            data-prototype-in-service-interface=Ev_EVC_CfgBit_01_26_Pr5_ST3, i-signal-triggering=EVC_CfgBit_01_26_Pr5_ST3_fblv727rnlh4ltr0dm5mnkvh_aii2eeplzjwcyn747h9kq19sa
        CSI_ExtVehicleConfig_Service_ST3_IDC_M_P_MAIN_20_Ev_EVC_CfgBit_73_98_Pr5_ST3
          event-element-mappings:
            {data-prototype-in-service-interface=element-in-impl-datatype={root-data-prototype=Ev_EVC_CfgBit_73_98_Pr5_ST3, target-data-prototype=CRC_EVC_CfgBit_73_98_Pr5_ST3}, i-signal-triggering=CRC_EVC_CfgBit_73_98_Pr5_ST3_7m8ewtnjyr4vvikloaee469iq}
            {data-prototype-in-service-interface=element-in-impl-datatype={root-data-prototype=Ev_EVC_CfgBit_73_98_Pr5_ST3, target-data-prototype=EVC_73_501_Avl_ST3}, i-signal-triggering=EVC_73_501_Avl_ST3_tdphzm6zr170n5wnngcpf7dm}
            {data-prototype-in-service-interface=element-in-impl-datatype={root-data-prototype=Ev_EVC_CfgBit_73_98_Pr5_ST3, target-data-prototype=EVC_74_476_Avl_ST3}, i-signal-triggering=EVC_74_476_Avl_ST3_140ucgp6kf4haqmruh1gkv5ai}
            {data-prototype-in-service-interface=element-in-impl-datatype={root-data-prototype=Ev_EVC_CfgBit_73_98_Pr5_ST3, target-data-prototype=EVC_75_AddEquip_Avl_ST3}, i-signal-triggering=EVC_75_AddEquip_Avl_ST3_1qibhdcs9xsiu1gaa0wfsmr8f}
            {data-prototype-in-service-interface=element-in-impl-datatype={root-data-prototype=Ev_EVC_CfgBit_73_98_Pr5_ST3, target-data-prototype=EVC_76_513_Avl_ST3}, i-signal-triggering=EVC_76_513_Avl_ST3_2i2o6c62f3fyf0l013bmfrceb}
            {data-prototype-in-service-interface=element-in-impl-datatype={root-data-prototype=Ev_EVC_CfgBit_73_98_Pr5_ST3, target-data-prototype=EVC_77_299_Avl_ST3}, i-signal-triggering=EVC_77_299_Avl_ST3_3tt4menvpp08j89vrtxizclm0}
            {data-prototype-in-service-interface=element-in-impl-datatype={root-data-prototype=Ev_EVC_CfgBit_73_98_Pr5_ST3, target-data-prototype=EVC_78_306_Avl_ST3}, i-signal-triggering=EVC_78_306_Avl_ST3_bdgh5dhh7owdiy5fe1k4jt7mv}
            {data-prototype-in-service-interface=element-in-impl-datatype={root-data-prototype=Ev_EVC_CfgBit_73_98_Pr5_ST3, target-data-prototype=EVC_79_AddEquip_Avl_ST3}, i-signal-triggering=EVC_79_AddEquip_Avl_ST3_2dytlzropv34kivnufve6jft0}
            {data-prototype-in-service-interface=element-in-impl-datatype={root-data-prototype=Ev_EVC_CfgBit_73_98_Pr5_ST3, target-data-prototype=EVC_7A_AddEquip_Avl_ST3}, i-signal-triggering=EVC_7A_AddEquip_Avl_ST3_cmb72p2ca52suh8g9kg5mziid}
            {data-prototype-in-service-interface=element-in-impl-datatype={root-data-prototype=Ev_EVC_CfgBit_73_98_Pr5_ST3, target-data-prototype=EVC_7B_551_Avl_ST3}, i-signal-triggering=EVC_7B_551_Avl_ST3_5m9rkbl5q17esv9ejweztydbg}
            {data-prototype-in-service-interface=element-in-impl-datatype={root-data-prototype=Ev_EVC_CfgBit_73_98_Pr5_ST3, target-data-prototype=EVC_7C_503_Avl_ST3}, i-signal-triggering=EVC_7C_503_Avl_ST3_8arn671s99d7fje5lex7ltuaj}
            {data-prototype-in-service-interface=element-in-impl-datatype={root-data-prototype=Ev_EVC_CfgBit_73_98_Pr5_ST3, target-data-prototype=EVC_7D_220_Avl_ST3}, i-signal-triggering=EVC_7D_220_Avl_ST3_4d50d5jbywocfm8zrv6cxlqli}
            {data-prototype-in-service-interface=element-in-impl-datatype={root-data-prototype=Ev_EVC_CfgBit_73_98_Pr5_ST3, target-data-prototype=EVC_7E_218_Avl_ST3}, i-signal-triggering=EVC_7E_218_Avl_ST3_96wuc9qci2uqb93qnu6drke2f}
            {data-prototype-in-service-interface=element-in-impl-datatype={root-data-prototype=Ev_EVC_CfgBit_73_98_Pr5_ST3, target-data-prototype=EVC_7F_235_Avl_ST3}, i-signal-triggering=EVC_7F_235_Avl_ST3_6u888n5zlbtpzpiqaxpod7vtt}
            {data-prototype-in-service-interface=element-in-impl-datatype={root-data-prototype=Ev_EVC_CfgBit_73_98_Pr5_ST3, target-data-prototype=EVC_80_AddEquip_Avl_ST3}, i-signal-triggering=EVC_80_AddEquip_Avl_ST3_1f4fvwwts57vf6621f04wa4e9}
            {data-prototype-in-service-interface=element-in-impl-datatype={root-data-prototype=Ev_EVC_CfgBit_73_98_Pr5_ST3, target-data-prototype=EVC_81_AddEquip_Avl_ST3}, i-signal-triggering=EVC_81_AddEquip_Avl_ST3_992b9sn0zy5hrsj7muu1eamdy}
            {data-prototype-in-service-interface=element-in-impl-datatype={root-data-prototype=Ev_EVC_CfgBit_73_98_Pr5_ST3, target-data-prototype=EVC_82_440_Avl_ST3}, i-signal-triggering=EVC_82_440_Avl_ST3_adhq158uhrnm3713wkijer9d4}
            {data-prototype-in-service-interface=element-in-impl-datatype={root-data-prototype=Ev_EVC_CfgBit_73_98_Pr5_ST3, target-data-prototype=EVC_83_AddEquip_Avl_ST3}, i-signal-triggering=EVC_83_AddEquip_Avl_ST3_c7nac9u8vbpiynqa5u7es80nq}
            {data-prototype-in-service-interface=element-in-impl-datatype={root-data-prototype=Ev_EVC_CfgBit_73_98_Pr5_ST3, target-data-prototype=EVC_84_504_Avl_ST3}, i-signal-triggering=EVC_84_504_Avl_ST3_71vpb9pqi7apj6rrhuxu6ile4}
            {data-prototype-in-service-interface=element-in-impl-datatype={root-data-prototype=Ev_EVC_CfgBit_73_98_Pr5_ST3, target-data-prototype=EVC_85_27U_Avl_ST3}, i-signal-triggering=EVC_85_27U_Avl_ST3_dfljkbegfv47x8d5haeje0qxm}
            {data-prototype-in-service-interface=element-in-impl-datatype={root-data-prototype=Ev_EVC_CfgBit_73_98_Pr5_ST3, target-data-prototype=EVC_86_K00_Avl_ST3}, i-signal-triggering=EVC_86_K00_Avl_ST3_99yjjp00p1py7he8u5qzh3co5}
            {data-prototype-in-service-interface=element-in-impl-datatype={root-data-prototype=Ev_EVC_CfgBit_73_98_Pr5_ST3, target-data-prototype=EVC_87_200_Avl_ST3}, i-signal-triggering=EVC_87_200_Avl_ST3_3jlderpcdgmfw6io5tmisnnlt}
            {data-prototype-in-service-interface=element-in-impl-datatype={root-data-prototype=Ev_EVC_CfgBit_73_98_Pr5_ST3, target-data-prototype=EVC_88_384_Avl_ST3}, i-signal-triggering=EVC_88_384_Avl_ST3_3na4m9zh39kz9nzq9h83av35n}
            {data-prototype-in-service-interface=element-in-impl-datatype={root-data-prototype=Ev_EVC_CfgBit_73_98_Pr5_ST3, target-data-prototype=EVC_89_233_Avl_ST3}, i-signal-triggering=EVC_89_233_Avl_ST3_787o7id5mzc4shnn6fs9ih8sa}
            {data-prototype-in-service-interface=element-in-impl-datatype={root-data-prototype=Ev_EVC_CfgBit_73_98_Pr5_ST3, target-data-prototype=EVC_8A_234_Avl_ST3}, i-signal-triggering=EVC_8A_234_Avl_ST3_2fvtdnyg572plmpnhrjjhzge9}
            {data-prototype-in-service-interface=element-in-impl-datatype={root-data-prototype=Ev_EVC_CfgBit_73_98_Pr5_ST3, target-data-prototype=EVC_8B_292_Avl_ST3}, i-signal-triggering=EVC_8B_292_Avl_ST3_8mdf07bouem7bn8t9l26v9x7k}
            {data-prototype-in-service-interface=element-in-impl-datatype={root-data-prototype=Ev_EVC_CfgBit_73_98_Pr5_ST3, target-data-prototype=EVC_8C_243_Avl_ST3}, i-signal-triggering=EVC_8C_243_Avl_ST3_a2rxhma3jh76m33mvrydi5tlp}
            {data-prototype-in-service-interface=element-in-impl-datatype={root-data-prototype=Ev_EVC_CfgBit_73_98_Pr5_ST3, target-data-prototype=EVC_8D_258_Avl_ST3}, i-signal-triggering=EVC_8D_258_Avl_ST3_4buqbz2vdsdrgsqsnylfgjo2p}
            {data-prototype-in-service-interface=element-in-impl-datatype={root-data-prototype=Ev_EVC_CfgBit_73_98_Pr5_ST3, target-data-prototype=EVC_8E_239_Avl_ST3}, i-signal-triggering=EVC_8E_239_Avl_ST3_91v9kpens26i37w3gf5gbq104}
            {data-prototype-in-service-interface=element-in-impl-datatype={root-data-prototype=Ev_EVC_CfgBit_73_98_Pr5_ST3, target-data-prototype=EVC_8F_266_Avl_ST3}, i-signal-triggering=EVC_8F_266_Avl_ST3_1oxg65mt8rmir5i0ffa1v7fxk}
            {data-prototype-in-service-interface=element-in-impl-datatype={root-data-prototype=Ev_EVC_CfgBit_73_98_Pr5_ST3, target-data-prototype=EVC_90_546_Avl_ST3}, i-signal-triggering=EVC_90_546_Avl_ST3_ct7nsa91rk0lnz1y70i6ukd3m}
            {data-prototype-in-service-interface=element-in-impl-datatype={root-data-prototype=Ev_EVC_CfgBit_73_98_Pr5_ST3, target-data-prototype=EVC_91_271_Avl_ST3}, i-signal-triggering=EVC_91_271_Avl_ST3_azj9u8g28w4rgd13cggc0ct9j}
            {data-prototype-in-service-interface=element-in-impl-datatype={root-data-prototype=Ev_EVC_CfgBit_73_98_Pr5_ST3, target-data-prototype=EVC_92_382_Avl_ST3}, i-signal-triggering=EVC_92_382_Avl_ST3_97wlqqnrh87nee859aok53f17}
            {data-prototype-in-service-interface=element-in-impl-datatype={root-data-prototype=Ev_EVC_CfgBit_73_98_Pr5_ST3, target-data-prototype=EVC_93_383_Avl_ST3}, i-signal-triggering=EVC_93_383_Avl_ST3_7jw9gfbk6o7r9vm9p272rf5fr}
            {data-prototype-in-service-interface=element-in-impl-datatype={root-data-prototype=Ev_EVC_CfgBit_73_98_Pr5_ST3, target-data-prototype=EVC_94_K29_Avl_ST3}, i-signal-triggering=EVC_94_K29_Avl_ST3_80w2l2ro3j0tt2qydi16sa0ig}
            {data-prototype-in-service-interface=element-in-impl-datatype={root-data-prototype=Ev_EVC_CfgBit_73_98_Pr5_ST3, target-data-prototype=EVC_95_AddEquip_Avl_ST3}, i-signal-triggering=EVC_95_AddEquip_Avl_ST3_2ogzahm06vsptkk7g124wrwv4}
            {data-prototype-in-service-interface=element-in-impl-datatype={root-data-prototype=Ev_EVC_CfgBit_73_98_Pr5_ST3, target-data-prototype=EVC_96_430_Avl_ST3}, i-signal-triggering=EVC_96_430_Avl_ST3_4u39cns6d5k99m7di48ijdcbx}
            {data-prototype-in-service-interface=element-in-impl-datatype={root-data-prototype=Ev_EVC_CfgBit_73_98_Pr5_ST3, target-data-prototype=EVC_97_950_Avl_ST3}, i-signal-triggering=EVC_97_950_Avl_ST3_31z3aq0pc9n5pk90kdw02r5m3}
            {data-prototype-in-service-interface=element-in-impl-datatype={root-data-prototype=Ev_EVC_CfgBit_73_98_Pr5_ST3, target-data-prototype=EVC_98_952_Avl_ST3}, i-signal-triggering=EVC_98_952_Avl_ST3_b2lzsod5k91y1w66o7s8syibz}
            {data-prototype-in-service-interface=element-in-impl-datatype={root-data-prototype=Ev_EVC_CfgBit_73_98_Pr5_ST3, target-data-prototype=EVC_CfgBit_73_98_Stat_ST3}, i-signal-triggering=EVC_CfgBit_73_98_Stat_ST3_cunnmdxx30lp6041jb546ecvi}
            {data-prototype-in-service-interface=element-in-impl-datatype={root-data-prototype=Ev_EVC_CfgBit_73_98_Pr5_ST3, target-data-prototype=SQC_EVC_CfgBit_73_98_Pr5_ST3}, i-signal-triggering=SQC_EVC_CfgBit_73_98_Pr5_ST3_hasqudwu0ualvppelt7z9xvd}
            data-prototype-in-service-interface=Ev_EVC_CfgBit_73_98_Pr5_ST3, i-signal-triggering=EVC_CfgBit_73_98_Pr5_ST3_4xva8cvevi64tljtz3c92ker3_3zpem302odev8qnpln5ew741c
        CSI_ExtVehicleConfig_Service_ST3_IDC_M_P_MAIN_20_Ev_EVC_CfgBit_99_BE_Pr5_ST3
          event-element-mappings:
            {data-prototype-in-service-interface=element-in-impl-datatype={root-data-prototype=Ev_EVC_CfgBit_99_BE_Pr5_ST3, target-data-prototype=EVC_9F_608_Avl_ST3}, i-signal-triggering=EVC_9F_608_Avl_ST3_2bfk7sif3xtyje6hatdefelvd}
            {data-prototype-in-service-interface=element-in-impl-datatype={root-data-prototype=Ev_EVC_CfgBit_99_BE_Pr5_ST3, target-data-prototype=EVC_A0_628_Avl_ST3}, i-signal-triggering=EVC_A0_628_Avl_ST3_9uy5eot9wzqeuzi8xn10ofhq8}
            {data-prototype-in-service-interface=element-in-impl-datatype={root-data-prototype=Ev_EVC_CfgBit_99_BE_Pr5_ST3, target-data-prototype=EVC_CfgBit_99_BE_Stat_ST3}, i-signal-triggering=EVC_CfgBit_99_BE_Stat_ST3_b35sz8o74ggbugkxgq5ar5dcy}
            data-prototype-in-service-interface=Ev_EVC_CfgBit_99_BE_Pr5_ST3, i-signal-triggering=EVC_CfgBit_99_BE_Pr5_ST3_cxgi3gf02ijeaizats4f45avn_dfu72zb2t6vgpqnpzntblf76p
        CSI_ExtVehicleConfig_Service_ST3_IDC_M_P_MAIN_20_Ev_EVC_CfgList_01_08_Pr5_ST3
          event-element-mappings:
            {data-prototype-in-service-interface=element-in-impl-datatype={root-data-prototype=Ev_EVC_CfgList_01_08_Pr5_ST3, target-data-prototype=CRC_EVC_CfgList_01_08_Pr5_ST3}, i-signal-triggering=CRC_EVC_CfgList_01_08_Pr5_ST3_980gvmf03uqyye6j5n05wxy03}
            {data-prototype-in-service-interface=element-in-impl-datatype={root-data-prototype=Ev_EVC_CfgList_01_08_Pr5_ST3, target-data-prototype=EVC_CfgList_01_08_Stat_ST3}, i-signal-triggering=EVC_CfgList_01_08_Stat_ST3_91o60ysyzd4c99ek6amzahwlh}
            {data-prototype-in-service-interface=element-in-impl-datatype={root-data-prototype=Ev_EVC_CfgList_01_08_Pr5_ST3, target-data-prototype=EVC_List01_BodyStyle_ST3}, i-signal-triggering=EVC_List01_BodyStyle_ST3_cgfr2hj591pws0xxbrtrrhyl}
            {data-prototype-in-service-interface=element-in-impl-datatype={root-data-prototype=Ev_EVC_CfgList_01_08_Pr5_ST3, target-data-prototype=EVC_List02_VehLine_ST3}, i-signal-triggering=EVC_List02_VehLine_ST3_9usfrbkbxofzpzmneiymph0c0}
            {data-prototype-in-service-interface=element-in-impl-datatype={root-data-prototype=Ev_EVC_CfgList_01_08_Pr5_ST3, target-data-prototype=EVC_List03_StStyle_ST3}, i-signal-triggering=EVC_List03_StStyle_ST3_9txp34dcom6yekw0d0j00cngf}
            {data-prototype-in-service-interface=element-in-impl-datatype={root-data-prototype=Ev_EVC_CfgList_01_08_Pr5_ST3, target-data-prototype=EVC_List04_YrOfModf_2_ST3}, i-signal-triggering=EVC_List04_YrOfModf_2_ST3_2qauja4vyirxp5mwpwcnmuwju}
            {data-prototype-in-service-interface=element-in-impl-datatype={root-data-prototype=Ev_EVC_CfgList_01_08_Pr5_ST3, target-data-prototype=EVC_List05_YrOfModf_1_ST3}, i-signal-triggering=EVC_List05_YrOfModf_1_ST3_e7dxiczhchh91z1bc1e6lhdrc}
            {data-prototype-in-service-interface=element-in-impl-datatype={root-data-prototype=Ev_EVC_CfgList_01_08_Pr5_ST3, target-data-prototype=EVC_List06_Country_ST3}, i-signal-triggering=EVC_List06_Country_ST3_d75voqy0w7l1ro7ryx262fi8k}
            {data-prototype-in-service-interface=element-in-impl-datatype={root-data-prototype=Ev_EVC_CfgList_01_08_Pr5_ST3, target-data-prototype=EVC_List07_TxStyle_ST3}, i-signal-triggering=EVC_List07_TxStyle_ST3_44xi7mt7v7s73iou6llymj22h}
            {data-prototype-in-service-interface=element-in-impl-datatype={root-data-prototype=Ev_EVC_CfgList_01_08_Pr5_ST3, target-data-prototype=EVC_List08_HL_Style_ST3}, i-signal-triggering=EVC_List08_HL_Style_ST3_1dqbdcy1afrxumghb1fxqpq5o}
            {data-prototype-in-service-interface=element-in-impl-datatype={root-data-prototype=Ev_EVC_CfgList_01_08_Pr5_ST3, target-data-prototype=SQC_EVC_CfgList_01_08_Pr5_ST3}, i-signal-triggering=SQC_EVC_CfgList_01_08_Pr5_ST3_6vt139gplrdpje4tu665h2s9g}
            data-prototype-in-service-interface=Ev_EVC_CfgList_01_08_Pr5_ST3, i-signal-triggering=EVC_CfgList_01_08_Pr5_ST3_co3q1mwsf7pwxo2ix5jryc04x_8al9ris41drwc82hdzv9x8hh6
    CSI_Immobilizer_Master_Service_ST3_MappingSet
      service instance to signal mapping CSI_Immobilizer_Master_Service_ST3_Ev_Ign_Stat_Pr5_ST3: service-instance=CSI_Immobilizer_Master_Service_ST3
        event-element-mappings:
          {data-prototype-in-service-interface=element-in-impl-datatype={root-data-prototype=Ev_Ign_Stat_Pr5_ST3, target-data-prototype=ISw_Stat_ST3}, i-signal-triggering=ISw_Stat_ST3_5gkxf1hu8xp7mtcnd4hmk1wog}
          data-prototype-in-service-interface=Ev_Ign_Stat_Pr5_ST3, i-signal-triggering=Ign_Stat_Pr5_ST3_csgs1dv6drms80o1i9p49677w_a85ebu8sapwpi2hpjjbd8wruc
    CSI_PN14_Master_Service_ST3_IDC_M_P_MAIN_20_MappingSet
      service instance to signal mapping CSI_PN14_Master_Service_ST3_IDC_M_P_MAIN_20_Ev_PN14_DDP_SwStat_ST3: signal-based-event-element-to-i-signal-triggering-mapping{data-prototype-in-service-interface=Ev_PN14_DDP_SwStat_ST3, i-signal-triggering=PN14_DDP_Sw_Stat_ST3_8g6pohg0apazqp94k098bxknc}, service-instance=CSI_PN14_Master_Service_ST3_IDC_M_P_MAIN_20
    CSI_PT4_PTCoor_Service_ST3_IDC_M_P_MAIN_20_MappingSet
      service instance to signal mapping CSI_PT4_PTCoor_Service_ST3_IDC_M_P_MAIN_20_Ev_PT4_PTCoor4_Pr5_ST3: service-instance=CSI_PT4_PTCoor_Service_ST3_IDC_M_P_MAIN_20
        event-element-mappings:
          {data-prototype-in-service-interface=element-in-impl-datatype={root-data-prototype=Ev_PT4_PTCoor4_Pr5_ST3, target-data-prototype=CRC_PT4_PTCoor4_Pr5_ST3}, i-signal-triggering=CRC_PT4_PTCoor4_Pr5_ST3_cnx8ge161g2b11h6e0of1sw0i}
          {data-prototype-in-service-interface=element-in-impl-datatype={root-data-prototype=Ev_PT4_PTCoor4_Pr5_ST3, target-data-prototype=PT4_PTCoor_EngStartPN14_Stat_ST3}, i-signal-triggering=PT4_PTCoor_EngStartPN14_Stat_ST3_2067n3c67sncuozku80ohvnma}
          {data-prototype-in-service-interface=element-in-impl-datatype={root-data-prototype=Ev_PT4_PTCoor4_Pr5_ST3, target-data-prototype=PT4_PTCoor_PT_Rdy_ST3}, i-signal-triggering=PT4_PTCoor_PT_Rdy_ST3_7b72xsjvb50uam5zjsf4z3sap}
          {data-prototype-in-service-interface=element-in-impl-datatype={root-data-prototype=Ev_PT4_PTCoor4_Pr5_ST3, target-data-prototype=PT4_PTCoor_SSA_EngSp_ST3}, i-signal-triggering=PT4_PTCoor_SSA_EngSp_ST3_e17plbz64873fy94el6dirk6}
          {data-prototype-in-service-interface=element-in-impl-datatype={root-data-prototype=Ev_PT4_PTCoor4_Pr5_ST3, target-data-prototype=Rsrv1_PT4_PTCoor_PT_Rdy_Pr5_ST3}, i-signal-triggering=Rsrv1_PT4_PTCoor_PT_Rdy_Pr5_ST3_c0pmjwjlne8vjmjairrgee2pb}
          {data-prototype-in-service-interface=element-in-impl-datatype={root-data-prototype=Ev_PT4_PTCoor4_Pr5_ST3, target-data-prototype=SQC_PT4_PTCoor4_Pr5_ST3}, i-signal-triggering=SQC_PT4_PTCoor4_Pr5_ST3_ddw8epc2jju668k86u8wnuegn}
          data-prototype-in-service-interface=Ev_PT4_PTCoor4_Pr5_ST3, i-signal-triggering=PT4_PTCoor4_Pr5_ST3_af4fxb1ykieox3itqdfzs0kpb_3220s5h2dops6tql3dl1aq3qj
    PSI_SuppFunctions_MPC_Service_ST3_IDC_M_P_MAIN_20_MappingSet
      service instance to signal mapping PSI_SuppFunctions_MPC_Service_ST3_IDC_M_P_MAIN_20_Ev_CamSensSoil_MPC_ST3: service-instance=PSI_SuppFunctions_MPC_Service_ST3_IDC_M_P_MAIN_20
        event-element-mappings:
          {data-prototype-in-service-interface=element-in-impl-datatype={root-data-prototype=Ev_CamSensSoil_MPC_ST3, target-data-prototype=CamSensSoil_CMS_IconDisp_Rq_MPC_ST3}, i-signal-triggering=CamSensSoil_CMS_IconDisp_Rq_MPC_ST3_6ii6bxcvtmj0a7ua5drxy3wut}
          {data-prototype-in-service-interface=element-in-impl-datatype={root-data-prototype=Ev_CamSensSoil_MPC_ST3, target-data-prototype=CamSensSoil_IHC_IconDisp_Rq_MPC_ST3}, i-signal-triggering=CamSensSoil_IHC_IconDisp_Rq_MPC_ST3_17w9tawtbd8yfa7s5y03zzajf}
          {data-prototype-in-service-interface=element-in-impl-datatype={root-data-prototype=Ev_CamSensSoil_MPC_ST3, target-data-prototype=CamSensSoil_LDP_IconDisp_Rq_MPC_ST3}, i-signal-triggering=CamSensSoil_LDP_IconDisp_Rq_MPC_ST3_eej1ppe07jsm6vc8fe74sa19z}
          {data-prototype-in-service-interface=element-in-impl-datatype={root-data-prototype=Ev_CamSensSoil_MPC_ST3, target-data-prototype=CamSensSoil_MsgDisp_Rq_MPC_ST3}, i-signal-triggering=CamSensSoil_MsgDisp_Rq_MPC_ST3_5u4dl6n5nponmzev7wfjsyyce}
          {data-prototype-in-service-interface=element-in-impl-datatype={root-data-prototype=Ev_CamSensSoil_MPC_ST3, target-data-prototype=CamSensSoil_TSA_IconDisp_Rq_MPC_ST3}, i-signal-triggering=CamSensSoil_TSA_IconDisp_Rq_MPC_ST3_82hfugk0acylvev977v9t1yg5}
          data-prototype-in-service-interface=Ev_CamSensSoil_MPC_ST3, i-signal-triggering=CamSensSoil_MPC_ST3_arrjrmhd69107z3r1gztlanxq_58c5wdliwlb5896whu1ly2m9g
package /ServiceInstances/SomeipSdTimingConfigs
  7 x someip sd client event group timing config, all with time-to-live=16777215:
    ClientEgSd_SomeIpEG_12804_0_DI_Master_Odometer: request-response-delay={max-value=0.02, min-value=0}
    ClientEgSd_SomeIpEG_128_0_Ign_Stat: request-response-delay={max-value=0.02, min-value=0}
    ClientEgSd_SomeIpEG_14596_0_PT4_PTCoor4: request-response-delay={max-value=0.02, min-value=0}
    ClientEgSd_SomeIpEG_14720_0_PN14_Master: request-response-delay={max-value=0.02, min-value=0}
    ClientEgSd_SomeIpEG_640_0_EVC_Cfg: request-response-delay={max-value=0.02, min-value=0}
    ClientEgSd_SomeIpEG_7826_1_AllEvents: request-response-delay={max-value=0.02, min-value=0}
    ClientEgSd_SomeIpEG_DummySWC_2_To_Cnfg_Mngr: request-response-delay={max-value=0, min-value=0}
  7 x someip sd client service instance config, all with service-find-time-to-live=16777215:
    ClientSd_CSI_DI_OdoSpeedometer_Service_ST3_IDC_M_P_MAIN_20: initial-find-behavior={initial-delay-max-value=0.105, initial-delay-min-value=0.105, initial-repetitions-base-delay=0.04, initial-repetitions-max=9}
    ClientSd_CSI_ExtVehicleConfig_Service_ST3_IDC_M_P_MAIN_20: initial-find-behavior={initial-delay-max-value=0, initial-delay-min-value=0, initial-repetitions-base-delay=0.16, initial-repetitions-max=9}
    ClientSd_CSI_Immobilizer_Master_Service_ST3: initial-find-behavior={initial-delay-max-value=0, initial-delay-min-value=0, initial-repetitions-base-delay=0.04, initial-repetitions-max=9}
    ClientSd_CSI_PN14_Master_Service_ST3_IDC_M_P_MAIN_20: initial-find-behavior={initial-delay-max-value=0.015, initial-delay-min-value=0.015, initial-repetitions-base-delay=0.04, initial-repetitions-max=9}
    ClientSd_CSI_PT4_PTCoor_Service_ST3_IDC_M_P_MAIN_20: initial-find-behavior={initial-delay-max-value=0.07, initial-delay-min-value=0.07, initial-repetitions-base-delay=0.04, initial-repetitions-max=9}
    ClientSd_CSI_SpeedLimiter_IDC_M_P_MAIN_20: initial-find-behavior={initial-delay-max-value=0.095, initial-delay-min-value=0.095, initial-repetitions-base-delay=0.04, initial-repetitions-max=9}
    ClientSd_CSI_X6AA_Dummy_B2_Service_Reserved: initial-find-behavior={initial-delay-max-value=0.035, initial-delay-min-value=0.035, initial-repetitions-base-delay=0.15, initial-repetitions-max=2}
  someip sd server event group timing config ServerEgSd_SomeIpEG_CamSensSoil: request-response-delay={max-value=0, min-value=0}
  someip sd server event group timing config ServerEgSd_SomeIpEG_DummySWC_2_To_Cnfg_Mngr: request-response-delay={max-value=0, min-value=0}
  someip sd server service instance config ServerSd_PSI_SuppFunctions_MPC_Service_ST3_IDC_M_P_MAIN_20: initial-offer-behavior={initial-delay-max-value=0.095, initial-delay-min-value=0.095, initial-repetitions-base-delay=0.3, initial-repetitions-max=2}, offer-cyclic-delay=10, request-response-delay={max-value=0, min-value=0}, service-offer-time-to-live=16777215
  someip sd server service instance config ServerSd_PSI_X6AA_Dummy_B2_Service_Reserved: initial-offer-behavior={initial-delay-max-value=0.035, initial-delay-min-value=0.035, initial-repetitions-base-delay=0.15, initial-repetitions-max=2}, offer-cyclic-delay=10, request-response-delay={max-value=0, min-value=0}, service-offer-time-to-live=16777215
package /ServiceInterfaces
  9 x service interface:
    SI_DI_OdoSpeedometer_Service_ST3
      namespaces:
        symbol props Services
        symbol props NS_OdoSpeedometer_Service_ST3
      events:
        data Ev_DI_Odo_Pr5_ST3: type=REC_DI_Odo_Pr5_ST3_9t50popkpz30is106xpis1iyh
    SI_ExtVehicleConfig_Service_ST3
      namespaces:
        symbol props Services
        symbol props NS_ExtVehicleConfig_Service_ST3
      events:
        4 x data:
          Ev_EVC_CfgBit_01_26_Pr5_ST3: type=REC_EVC_CfgBit_01_26_Pr5_ST3_2nibgl9yx8nj74mt7kvhiab7f
          Ev_EVC_CfgBit_73_98_Pr5_ST3: type=REC_EVC_CfgBit_73_98_Pr5_ST3_9w3nb2gl752ewx8w6kdqei5ll
          Ev_EVC_CfgBit_99_BE_Pr5_ST3: type=REC_EVC_CfgBit_99_BE_Pr5_ST3_3ic8vtrgsvug14f7o5f9ow0r3
          Ev_EVC_CfgList_01_08_Pr5_ST3: type=REC_EVC_CfgList_01_08_Pr5_ST3_14lojwgkcazelrb438elf5h0j
    SI_Immobilizer_Master_Service_ST3
      namespaces:
        symbol props Services
        symbol props NS_Immobilizer_Master_Service_ST3
      events:
        data Ev_Ign_Stat_Pr5_ST3: type=REC_Ign_Stat_Pr5_ST3_b0ko81o0x5jgvwtduf99gvzi0
    SI_PN14_Master_Service_ST3
      namespaces:
        symbol props Services
        symbol props NS_PN14_Master_Service_ST3
      events:
        data Ev_PN14_DDP_SwStat_ST3: type=uint8_t
    SI_PT4_PTCoor_Service_ST3
      namespaces:
        symbol props Services
        symbol props NS_PT4_PTCoor_Service_ST3
      events:
        data Ev_PT4_PTCoor4_Pr5_ST3: type=REC_PT4_PTCoor4_Pr5_ST3_a1o7mhv0xy8ny0vccjf09ttgc
    SI_SpeedLimiter
      namespaces:
        symbol props Services
        symbol props NS_SpeedLimiter
      events:
        data Ev_Capabilities: type=VSLim_GetCapabilities_Out_b0ko81o0x5jgvwtduf99gvzi0
        data Ev_SpeedLimiterState: type=VSLim_SpeedLimiterState_71njeubj9ico1p8v4pmslfcno
      methods:
        operation Meth_GetCapabilities: fire-and-forget=false
          arg OutParameters: type=VSLim_GetCapabilities_Out_b0ko81o0x5jgvwtduf99gvzi0, direction=OUT
        operation Meth_RequestSpeedLimit: fire-and-forget=false
          arg InParameters: type=VSLim_RequestLimit_In, direction=IN
    SI_SuppFunctions_MPC_Service_ST3
      namespaces:
        symbol props Services
        symbol props NS_SuppFunctions_MPC_Service_ST3
      events:
        data Ev_CamSensSoil_MPC_ST3: type=REC_CamSensSoil_MPC_ST3_cp6wyrd9cg7ec7y2w3khz1gyt
    SI_X6AA_Cnfg_Mngr_Service_Reserved
      namespaces:
        symbol props Services
        symbol props NS_SI_Cnfg_Mngr_To_DummySWC
      events:
        data Ev_activateSarStorage0131VcEvent: type=REC_activateSarStorage0131VcEventType_t
        data Ev_configureSarTriggerEvents0136VcEvent: type=REC_configureSarTriggerEvents0136VcEventType_t
        data Ev_vechicleInformation0400VcEvent: type=REC_vechicleInformation0400VcEventType_t
    SI_X6AA_Dummy_B2_Service_Reserved
      namespaces:
        symbol props Services
        symbol props NS_SI_DummySWC_2_To_Cnfg_Mngr
      events:
        data Ev_CalculationResult: type=uint32_t
package /ServiceInterfaces/InterfaceMappingSets
  interface mapping set InterfaceMappingSet
    6 x interface mapping:
      SI_DI_OdoSpeedometer_Service_ST3_InterfaceMapping
        event mapping Ev_DI_Odo_Pr5_ST3_DI_Odo_Pr5_ST3: data-element=DI_Odo_Pr5_ST3, event=Ev_DI_Odo_Pr5_ST3
      SI_ExtVehicleConfig_Service_ST3_InterfaceMapping
        4 x event mapping:
          Ev_EVC_CfgBit_01_26_Pr5_ST3_EVC_CfgBit_01_26_Pr5_ST3: data-element=EVC_CfgBit_01_26_Pr5_ST3, event=Ev_EVC_CfgBit_01_26_Pr5_ST3
          Ev_EVC_CfgBit_73_98_Pr5_ST3_EVC_CfgBit_73_98_Pr5_ST3: data-element=EVC_CfgBit_73_98_Pr5_ST3, event=Ev_EVC_CfgBit_73_98_Pr5_ST3
          Ev_EVC_CfgBit_99_BE_Pr5_ST3_EVC_CfgBit_99_BE_Pr5_ST3: data-element=EVC_CfgBit_99_BE_Pr5_ST3, event=Ev_EVC_CfgBit_99_BE_Pr5_ST3
          Ev_EVC_CfgList_01_08_Pr5_ST3_EVC_CfgList_01_08_Pr5_ST3: data-element=EVC_CfgList_01_08_Pr5_ST3, event=Ev_EVC_CfgList_01_08_Pr5_ST3
      SI_Immobilizer_Master_Service_ST3_InterfaceMapping
        event mapping Ev_Ign_Stat_Pr5_ST3_Ign_Stat_Pr5_ST3: data-element=Ign_Stat_Pr5_ST3, event=Ev_Ign_Stat_Pr5_ST3
      SI_PN14_Master_Service_ST3_InterfaceMapping
        event mapping Ev_PN14_DDP_SwStat_ST3_PN14_DDP_Sw_Stat_ST3: data-element=PN14_DDP_Sw_Stat_ST3, event=Ev_PN14_DDP_SwStat_ST3
      SI_PT4_PTCoor_Service_ST3_InterfaceMapping
        event mapping Ev_PT4_PTCoor4_Pr5_ST3_PT4_PTCoor4_Pr5_ST3: data-element=PT4_PTCoor4_Pr5_ST3, event=Ev_PT4_PTCoor4_Pr5_ST3
      SI_SuppFunctions_MPC_Service_ST3_InterfaceMapping
        event mapping Ev_CamSensSoil_MPC_ST3_CamSensSoil_MPC_ST3: data-element=CamSensSoil_MPC_ST3, event=Ev_CamSensSoil_MPC_ST3
package /ServiceInterfaces/ServiceInterfaceDeployments
  6 x signal based service interface deployment:
    CSI_DI_OdoSpeedometer_Service_ST3_IDC_M_P_MAIN_20_SignalBasedDeployment: service-interface=SI_DI_OdoSpeedometer_Service_ST3
    CSI_ExtVehicleConfig_Service_ST3_IDC_M_P_MAIN_20_SignalBasedDeployment: service-interface=SI_ExtVehicleConfig_Service_ST3
    CSI_Immobilizer_Master_Service_ST3_SignalBasedDeployment: service-interface=SI_Immobilizer_Master_Service_ST3
    CSI_PN14_Master_Service_ST3_IDC_M_P_MAIN_20_SignalBasedDeployment: service-interface=SI_PN14_Master_Service_ST3
    CSI_PT4_PTCoor_Service_ST3_IDC_M_P_MAIN_20_SignalBasedDeployment: service-interface=SI_PT4_PTCoor_Service_ST3
    PSI_SuppFunctions_MPC_Service_ST3_IDC_M_P_MAIN_20_SignalBasedDeployment: service-interface=SI_SuppFunctions_MPC_Service_ST3
  8 x someip service interface deployment:
    SomeIpSI_DI_OdoSpeedometer_Service_ST3: service-interface=SI_DI_OdoSpeedometer_Service_ST3, service-interface-id=12804, service-interface-version={major-version=1, minor-version=0}
      someip event deployment SomeIpEv_DI_Odo_Pr5_ST3: event=Ev_DI_Odo_Pr5_ST3, event-id=0, transport-protocol=UDP
      someip event group EG_12804_0_DI_Master_Odometer: event-group-id=0, event=SomeIpEv_DI_Odo_Pr5_ST3
    SomeIpSI_DummySWC_2_To_Cnfg_Mngr: service-interface=SI_X6AA_Dummy_B2_Service_Reserved, service-interface-id=45180, service-interface-version={major-version=1, minor-version=1}
      someip event deployment SomeIpEv_CalculationResult: event=Ev_CalculationResult, event-id=1, transport-protocol=UDP
      someip event group EG_DummySWC_2_To_Cnfg_Mngr: event-group-id=1, event=SomeIpEv_CalculationResult
    SomeIpSI_ExtVehicleConfig_Service_ST3: service-interface=SI_ExtVehicleConfig_Service_ST3, service-interface-id=640, service-interface-version={major-version=1, minor-version=0}
      4 x someip event deployment, all with transport-protocol=UDP:
        SomeIpEv_EVC_CfgBit_01_26_Pr5_ST3: event=Ev_EVC_CfgBit_01_26_Pr5_ST3, event-id=1
        SomeIpEv_EVC_CfgBit_73_98_Pr5_ST3: event=Ev_EVC_CfgBit_73_98_Pr5_ST3, event-id=4
        SomeIpEv_EVC_CfgBit_99_BE_Pr5_ST3: event=Ev_EVC_CfgBit_99_BE_Pr5_ST3, event-id=5
        SomeIpEv_EVC_CfgList_01_08_Pr5_ST3: event=Ev_EVC_CfgList_01_08_Pr5_ST3, event-id=0
      someip event group EG_640_0_EVC_Cfg: event-group-id=0, event=[SomeIpEv_EVC_CfgBit_01_26_Pr5_ST3, SomeIpEv_EVC_CfgBit_73_98_Pr5_ST3, SomeIpEv_EVC_CfgBit_99_BE_Pr5_ST3, SomeIpEv_EVC_CfgList_01_08_Pr5_ST3]
    SomeIpSI_Immobilizer_Master_Service_ST3: service-interface=SI_Immobilizer_Master_Service_ST3, service-interface-id=128, service-interface-version={major-version=1, minor-version=0}
      someip event deployment SomeIpEv_Ign_Stat_Pr5_ST3: event=Ev_Ign_Stat_Pr5_ST3, event-id=0, transport-protocol=UDP
      someip event group EG_128_0_Ign_Stat: event-group-id=0, event=SomeIpEv_Ign_Stat_Pr5_ST3
    SomeIpSI_PN14_Master_Service_ST3: service-interface=SI_PN14_Master_Service_ST3, service-interface-id=14720, service-interface-version={major-version=1, minor-version=0}
      someip event deployment SomeIpEv_PN14_DDP_SwStat_ST3: event=Ev_PN14_DDP_SwStat_ST3, event-id=0, transport-protocol=UDP
      someip event group EG_14720_0_PN14_Master: event-group-id=0, event=SomeIpEv_PN14_DDP_SwStat_ST3
    SomeIpSI_PT4_PTCoor_Service_ST3: service-interface=SI_PT4_PTCoor_Service_ST3, service-interface-id=14596, service-interface-version={major-version=1, minor-version=0}
      someip event deployment SomeIpEv_PT4_PTCoor4_Pr5_ST3: event=Ev_PT4_PTCoor4_Pr5_ST3, event-id=6, transport-protocol=UDP
      someip event group EG_14596_0_PT4_PTCoor4: event-group-id=0, event=SomeIpEv_PT4_PTCoor4_Pr5_ST3
    SomeIpSI_SpeedLimiter: service-interface=SI_SpeedLimiter, service-interface-id=7826, service-interface-version={major-version=1, minor-version=0}
      someip event deployment SomeIpEv_Capabilities: event=Ev_Capabilities, event-id=1, transport-protocol=UDP
      someip event deployment SomeIpEv_SpeedLimiterState: event=Ev_SpeedLimiterState, event-id=101, transport-protocol=UDP
      someip method deployment SomeIpMeth_GetCapabilities: method=Meth_GetCapabilities, method-id=1, transport-protocol=UDP
      someip method deployment SomeIpMeth_RequestSpeedLimit: method=Meth_RequestSpeedLimit, method-id=101, transport-protocol=UDP
      someip event group EG_7826_1_AllEvents: event-group-id=1, event=[SomeIpEv_Capabilities, SomeIpEv_SpeedLimiterState]
    SomeIpSI_SuppFunctions_MPC_Service_ST3: service-interface=SI_SuppFunctions_MPC_Service_ST3, service-interface-id=17672, service-interface-version={major-version=1, minor-version=0}
      someip event deployment SomeIpEv_CamSensSoil_MPC_ST3: event=Ev_CamSensSoil_MPC_ST3, event-id=0, transport-protocol=UDP
      someip event group EG_17672_0_CamSensSoil_MPC: event-group-id=0, event=SomeIpEv_CamSensSoil_MPC_ST3
  user defined service interface deployment UDSI_X6AA_Cnfg_Mngr_Service_Reserved: service-interface=SI_X6AA_Cnfg_Mngr_Service_Reserved
    user defined event deployment UDED_activateSarStorage0131VcEvent: event=Ev_activateSarStorage0131VcEvent
    user defined event deployment UDED_configureSarTriggerEvents0136VcEvent: event=Ev_configureSarTriggerEvents0136VcEvent
    user defined event deployment UDED_vechicleInformation0400VcEvent: event=Ev_vechicleInformation0400VcEvent
package /ServiceInterfaces/TransformationPropsSet
  transformation props set TransformerConfigurationPackage
    ap someip transformation props SOMEIP_8bit: byte-order=little-endian, is-dynamic-length-field-size=false, size-of-array-length-field=2, size-of-struct-length-field=2, size-of-union-length-field=1, size-of-union-type-selector-field=1, string-encoding=UTF-8
package /ServiceInterfaces/TransformationPropsToServiceInterfaceMappingSets
  transformation props to service interface element mapping set ServiceInterfaceTransformation
    8 x transformation props to service interface element mapping, all with transformation-props=SOMEIP_8bit:
      Ev_CalculationResultTransProps: event=Ev_CalculationResult
      Ev_CamSensSoil_MPC_ST3TransProps: event=Ev_CamSensSoil_MPC_ST3
      Ev_DI_Odo_Pr5_ST3TransProps: event=Ev_DI_Odo_Pr5_ST3
      Ev_EVC_CfgBit_01_26_Pr5_ST3TransProps: event=[Ev_EVC_CfgBit_01_26_Pr5_ST3, Ev_EVC_CfgBit_73_98_Pr5_ST3, Ev_EVC_CfgBit_99_BE_Pr5_ST3, Ev_EVC_CfgList_01_08_Pr5_ST3]
      Ev_Ign_Stat_Pr5_ST3TransProps: event=Ev_Ign_Stat_Pr5_ST3
      Ev_PN14_DDP_SwStat_ST3TransProps: event=Ev_PN14_DDP_SwStat_ST3
      Ev_PT4_PTCoor4_Pr5_ST3TransProps: event=Ev_PT4_PTCoor4_Pr5_ST3
      Meth_RequestSpeedLimitTransProps: event=[Ev_Capabilities, Ev_SpeedLimiterState], method=[Meth_GetCapabilities, Meth_RequestSpeedLimit]
package /SoftwareTypes/Interfaces
  9 x sender receiver interface, all with category=FUNCTIONAL:
    IF_PN14_DDP_Sw_Stat_ST3: invalidation-policy{data-element=PN14_DDP_Sw_Stat_ST3, handle-invalid=DONT-INVALIDATE}  # Deep discharge protection switch state
      data PN14_DDP_Sw_Stat_ST3: sw-calibration-access=READ-WRITE  # SHORT: Deep discharge protection switch state LONG: Deep discharge protection switch state
    IG_CamSensSoil_MPC_ST3_65shooskatu2o0b15140e1gpl  # Cam Sens Soil MPC ST3 (degraded)
      data CamSensSoil_MPC_ST3: sw-calibration-access=READ-WRITE  # SHORT: Cam Sens Soil MPC ST3 LONG: Cam Sens Soil MPC ST3 (degraded)
    IG_DI_Odo_Pr5_ST3_dqmkbik4b90gceqe8t96kp3yd: invalidation-policy{data-element=DI_Odo_Pr5_ST3, handle-invalid=DONT-INVALIDATE}  # DriverInformation Odometer (degraded)
      data DI_Odo_Pr5_ST3: sw-calibration-access=READ-WRITE  # SHORT: DriverInformation Odometer LONG: DriverInformation Odometer (degraded)
    IG_EVC_CfgBit_01_26_Pr5_ST3_dlx5t6rzp4r6r58er939hoyfg: invalidation-policy{data-element=EVC_CfgBit_01_26_Pr5_ST3, handle-invalid=DONT-INVALIDATE}  # EVC Cfg Bit 01 26 Pr 5 ST3 (degraded)
      data EVC_CfgBit_01_26_Pr5_ST3: sw-calibration-access=READ-WRITE  # SHORT: EVC Cfg Bit 01 26 Pr 5 ST3 LONG: (degraded)
    IG_EVC_CfgBit_73_98_Pr5_ST3_1a3uz0b943v74g9xgllnc3841: invalidation-policy{data-element=EVC_CfgBit_73_98_Pr5_ST3, handle-invalid=DONT-INVALIDATE}  # EVC Cfg Bit 73 98 Pr 5 ST3 (degraded)
      data EVC_CfgBit_73_98_Pr5_ST3: sw-calibration-access=READ-WRITE  # SHORT: EVC Cfg Bit 73 98 Pr 5 ST3 LONG: EVC Cfg Bit 73 98 Pr 5 ST3 (degraded)
    IG_EVC_CfgBit_99_BE_Pr5_ST3_vc471w69ombs06yf14yctt5a: invalidation-policy{data-element=EVC_CfgBit_99_BE_Pr5_ST3, handle-invalid=DONT-INVALIDATE}  # EVC Cfg Bit 99 BE Pr 5 ST3 (degraded)
      data EVC_CfgBit_99_BE_Pr5_ST3: sw-calibration-access=READ-WRITE  # SHORT: EVC Cfg Bit 99 BE Pr 5 ST3 LONG: (degraded)
    IG_EVC_CfgList_01_08_Pr5_ST3_3l05ivl1ymn6sqzscm8x2shhp: invalidation-policy{data-element=EVC_CfgList_01_08_Pr5_ST3, handle-invalid=DONT-INVALIDATE}  # EVC Cfg List 01 08 Pr 5 ST3 (degraded)
      data EVC_CfgList_01_08_Pr5_ST3: sw-calibration-access=READ-WRITE  # SHORT: EVC Cfg List 01 08 Pr 5 ST3 LONG: (degraded)
    IG_Ign_Stat_Pr5_ST3_8qpxphk9meu9oryi6bfj0x04b: invalidation-policy{data-element=Ign_Stat_Pr5_ST3, handle-invalid=DONT-INVALIDATE}  # Ignition state (degraded)
      data Ign_Stat_Pr5_ST3: sw-calibration-access=READ-WRITE  # SHORT: Ignition state LONG: Ignition state (degraded)
    IG_PT4_PTCoor4_Pr5_ST3_ca2s46eormi424s6cen48bry3: invalidation-policy{data-element=PT4_PTCoor4_Pr5_ST3, handle-invalid=DONT-INVALIDATE}  # PT4_PTCoor4_Pr5_ST3 (degraded)
      data PT4_PTCoor4_Pr5_ST3: sw-calibration-access=READ-WRITE  # SHORT: PT4_PTCoor4_Pr5_ST3 LONG: PT4_PTCoor4_Pr5_ST3 (degraded)
package /Topology/Clusters
  ethernet cluster MAIN
    4 x ethernet physical channel, all with category=WIRED:
      MAIN_1
        network endpoint IDC6_MeasurementInterface: network-endpoint-addresses=ipv-4-configuration={ipv-4-address=10.1.17.99, network-mask=255.255.0.0}
        network endpoint NE_Base_ADAS6: network-endpoint-addresses=ipv-4-configuration={ipv-4-address=169.254.18.98, network-mask=255.255.0.0}
        network endpoint SomeIP_SD_NetworkEndpoint: network-endpoint-addresses=ipv-4-configuration={ipv-4-address=239.1.0.2, ipv-4-address-source=FIXED}
        vlan MAIN_1: vlan-identifier=1
      MAIN_127
        network endpoint NE_Base_ADAS6: network-endpoint-addresses=ipv-4-configuration={ipv-4-address=10.127.17.98, network-mask=255.255.0.0}
        network endpoint SomeIP_SD_NetworkEndpoint_MAIN_127: network-endpoint-addresses=ipv-4-configuration={ipv-4-address=239.127.0.2, ipv-4-address-source=FIXED}
        vlan MAIN_127: vlan-identifier=127
      MAIN_20
        pdu triggering CamSensSoil_MPC_ST3_3b1p0bjri6vz9oex661gpudgv: pdu=CamSensSoil_MPC_ST3, from IDC_Adpative
        pdu triggering DAP_StWhl_Ctrl_ST3: pdu=DAP_StWhl_Ctrl_ST3, to IDC_Adpative
        pdu triggering DI_OdoSpeedometer_ST3_7a5yij3yhjbmvl5hkuqmjd1pd: pdu=DI_OdoSpeedometer_ST3, to IDC_Adpative
        pdu triggering EVC_CfgBit_01_26_Pr5_ST3_33k9xmdsozdkkl8zt9ygup6oz: pdu=EVC_CfgBit_01_26_Pr5_ST3, to IDC_Adpative
        pdu triggering EVC_CfgBit_73_98_Pr5_ST3_cexxu9j7zsw7sr2sq9knols8a: pdu=EVC_CfgBit_73_98_Pr5_ST3, to IDC_Adpative
        pdu triggering EVC_CfgBit_99_BE_Pr5_ST3_3ai9pelgtt77zkf6yh347a28x: pdu=EVC_CfgBit_99_BE_Pr5_ST3, to IDC_Adpative
        pdu triggering EVC_CfgList_01_08_Pr5_ST3_46c68mzkyqfqfojidsz9a0p1r: pdu=EVC_CfgList_01_08_Pr5_ST3, to IDC_Adpative
        pdu triggering Ign_Stat_ST3_d7xuqg6u8cfdee45rf4wpbzp9: pdu=Ign_Stat_ST3, to IDC_Adpative
        pdu triggering PN14_Master_Stat1_ST3_1m92rorfvajm6ibd99f2t5p4c: pdu=PN14_Master_Stat1_ST3, to IDC_Adpative
        pdu triggering PT4_PTCoor4_ST3_2y5glasob02bqw3jjaibn32cb: pdu=PT4_PTCoor4_ST3, to IDC_Adpative
        network endpoint NE_Base_ADAS6: network-endpoint-addresses=ipv-4-configuration={ipv-4-address=10.20.1.113, ipv-4-address-source=FIXED, network-mask=255.255.0.0, ttl=1}
        network endpoint SomeIP_SD_NetworkEndpoint_MAIN_20: network-endpoint-addresses=ipv-4-configuration={ipv-4-address=239.20.0.2, ipv-4-address-source=FIXED}
        vlan MAIN_20: vlan-identifier=20
      MAIN_21
        network endpoint NE_Base_ADAS6: network-endpoint-addresses=ipv-4-configuration={ipv-4-address=10.21.17.98, network-mask=255.255.0.0}
        network endpoint SomeIP_SD_NetworkEndpoint_MAIN_21: network-endpoint-addresses=ipv-4-configuration={ipv-4-address=239.21.0.2, ipv-4-address-source=FIXED}
        vlan MAIN_21: vlan-identifier=21
package /Topology/HardwareComponents
  machine design IDC_Adpative: category=EXECUTION_CONTEXT
    ethernet communication connector IDC6_M_P_Logging: category=WIRED, unicast-network-endpoint=IDC6_MeasurementInterface
    ethernet communication connector IDC_M_P_MAIN_1: category=WIRED, unicast-network-endpoint=MAIN_1/NE_Base_ADAS6
    ethernet communication connector IDC_M_P_MAIN_127: category=WIRED, unicast-network-endpoint=MAIN_127/NE_Base_ADAS6
    ethernet communication connector IDC_M_P_MAIN_20: category=WIRED, unicast-network-endpoint=MAIN_20/NE_Base_ADAS6
    ethernet communication connector IDC_M_P_MAIN_21: category=WIRED, unicast-network-endpoint=MAIN_21/NE_Base_ADAS6
    service-discover-configs:
      multicast-sd-ip-address=SomeIP_SD_NetworkEndpoint, someip-service-discovery-port=30490
      multicast-sd-ip-address=SomeIP_SD_NetworkEndpoint_MAIN_127, someip-service-discovery-port=30490
      multicast-sd-ip-address=SomeIP_SD_NetworkEndpoint_MAIN_20, someip-service-discovery-port=30490
      multicast-sd-ip-address=SomeIP_SD_NetworkEndpoint_MAIN_21, someip-service-discovery-port=30490
package /E2EProfileConfigurationSet
  e 2 e profile configuration set End2EndProps
    e 2 e profile configuration E2E_Profile_6: max-delta-counter=3, max-error-state-init=0, max-error-state-invalid=0, max-error-state-valid=0, min-ok-state-init=1, min-ok-state-invalid=1, min-ok-state-valid=1, profile-name=PROFILE_06, window-size=10
    e 2 e profile configuration E2E_Profile_7: max-delta-counter=3, max-error-state-init=0, max-error-state-invalid=0, max-error-state-valid=0, min-ok-state-init=1, min-ok-state-invalid=1, min-ok-state-valid=1, profile-name=PROFILE_07, window-size=10
package /amsr/diag
  service interface DiagComApi
    namespaces:
      4 x symbol props:
        amsr
        diag
        service_interfaces
        diag_com_api
    events:
      data DaemonRequestResponse: type=DaemonRequestResponseType
      data DiagRequest: type=DiagRequestType
    methods:
      4 x operation, all with fire-and-forget=true:
        RequestData
          6 x arg, all with direction=IN:
            handle: type=HandleType
            instance_handle: type=InstanceHandle
            job_identifier: type=JobIdentifier
            meta_info: type=MetaInfoType
            request_data: type=ByteVectorType
            conversation_handle: type=ConversationHandle
        Cancel
          arg job_identifier: type=JobIdentifier, direction=IN
        NotifyValue
          4 x arg, all with direction=IN:
            handle: type=HandleType
            instance_handle: type=InstanceHandle
            conversation_handle: type=ConversationHandle
            byte_vector: type=ByteVectorType
        NotifyResponse
          arg response_type: type=HandleType, direction=IN
          arg job_identifier: type=JobIdentifier, direction=IN
          arg byte_vector: type=ByteVectorType, direction=IN
package /ara/diag
  adaptive application sw component type DiagnosticManagerSwc
    provide/require port Persistency: provided-required-interface=PersistencyInterface
    require port DiagComApiDeamonPort: required-interface=DiagComApi
package /SoftwareDistribution/SoftwareCluster
  software cluster SoftwareClusterPlatform: contained-process=[Application_basicIPC1_Process, Application_basicIPC2_Process, DiagnosticManagerDeamon, SelfDiagnosticAgent_Process, Application_S2S_Process, Application_SOMEIP_Process], design=temporarySoftwareClusterDesignPer, software-cluster-doip-diagnostic-address{address-semantics=PHYSICAL-ADDRESS, diagnostic-address=4451}, diagnostic-extract=DcmContributionSet, vendor-id=4660, version=1.0.0.0000
package /SoftwareDistribution/SoftwarePackage
  software package SoftwarePackagePlatform: software-cluster=SoftwareClusterPlatform
package /SoftwareDistribution/SoftwareClusterDesign
  software cluster design temporarySoftwareClusterDesignPer: contained-process=[ProcessDesign_SelfDiagnosticAgent, ProcessDesign_TransmissionManager_ROV, ProcessDesign_X6AA_Cnfg_Mngr_SWC, ProcessDesign_X6AA_Dummy_SWC_1, ProcessDesign__X6AA_Dummy_SWC_2, ProcessDesign_X6AA_DLT_SWC, ProcessDesign_X6AA_Ressource_SWC], intended-target-machine=IDC_Adpative
package /Diagnostics/port_interfaces
  diagnostic condition interface Condition_Interface
  diagnostic dtc information interface DTC_Information_Interface
  diagnostic data identifier generic interface DataIdentifierGeneric_Interface
  diagnostic data identifier interface VersionInfoDataIdentifier
    namespaces:
      symbol props lorem
      symbol props ipsum
    read Read
      arg VersionInfoBuffer: type=ByteVector, direction=OUT
  diagnostic data identifier interface VINInformation_Interface
    read Read
      arg Vin: type=VINType, direction=OUT
    write Write
      arg Vin: type=VINType, direction=IN
  diagnostic data identifier interface SystemInfoDataIdentifier
    namespaces:
      symbol props lorem
      symbol props ipsum
    read Read
      arg SystemInfoBuffer: type=ByteVector, direction=OUT
  diagnostic do ip group identification interface DoIPGroupIdentification_Interface
  diagnostic do ip power mode interface DoIPPowerMode_Interface
  diagnostic download interface Download_Interface
  diagnostic event interface Event_Interface
  diagnostic generic uds interface Generic_Uds_Interface
  diagnostic indicator interface Indicator_Interface
  diagnostic monitor interface Monitor_Interface
  diagnostic operation cycle interface OperationCycle_Interface
  diagnostic routine generic interface RoutineGeneric_Interface
  diagnostic security level interface SecurityLevel_Interface
  diagnostic service validation interface ServiceValidation_Interface
  diagnostic upload interface Upload_Interface
package /Diagnostics/types
  11 x std cpp implementation data type, all with type-emitter=TYPE_EMITTER_ARA:
    VINType: category=ARRAY, array-size=17, cpp-template-argument=uint8_t  # 17 byte array of uint8 representing the VIN
      namespaces:
        symbol props ara
        symbol props diag
    ArrayBytes7: category=ARRAY, array-size=7, cpp-template-argument=uint8_t  # byte array of 7 bytes
      namespaces:
        symbol props self_diag_agent
    ByteVector: category=VECTOR, cpp-template-argument=uint8_t  # Vector of uint8
      namespaces:
        symbol props self_diag_agent
    InstanceHandle: type-reference=uint32_t
      namespaces:
        symbol props ns0: symbol=amsr
        symbol props ns1: symbol=diag
        symbol props ns2: symbol=com_api
    DiagRequestType: category=STRUCTURE
      namespaces:
        symbol props ns0: symbol=amsr
        symbol props ns1: symbol=diag
        symbol props ns2: symbol=com_api
      5 x cpp implementation data type element:
        handle: type-reference=HandleType
        instance_handle: type-reference=InstanceHandle
        conversation_handle: type-reference=ConversationHandle
        job_identifier: type-reference=JobIdentifier
        value: type-reference=ByteVectorType
    ConversationHandle: type-reference=uint16_t
      namespaces:
        symbol props ns0: symbol=amsr
        symbol props ns1: symbol=diag
        symbol props ns2: symbol=com_api
    HandleType: type-reference=uint16_t
      namespaces:
        symbol props ns0: symbol=amsr
        symbol props ns1: symbol=diag
        symbol props ns2: symbol=com_api
    MetaInfoType: category=ASSOCIATIVE_MAP, template-arguments=[string, string]  # Meta-Inf map, which contains key-value pairs of MetaInfoKeyType, MetaInfoValueType.
      namespaces:
        symbol props ns0: symbol=amsr
        symbol props ns1: symbol=diag
        symbol props ns2: symbol=com_api
    ByteVectorType: category=VECTOR, cpp-template-argument=uint8_t
      namespaces:
        symbol props ns0: symbol=amsr
        symbol props ns1: symbol=diag
        symbol props ns2: symbol=com_api
    JobIdentifier: type-reference=uint32_t
      namespaces:
        symbol props ns0: symbol=amsr
        symbol props ns1: symbol=diag
        symbol props ns2: symbol=com_api
    DaemonRequestResponseType: category=STRUCTURE
      namespaces:
        symbol props ns0: symbol=amsr
        symbol props ns1: symbol=diag
        symbol props ns2: symbol=com_api
      cpp implementation data type element response_type: type-reference=HandleType
      cpp implementation data type element job_identifier: type-reference=JobIdentifier
      cpp implementation data type element value: type-reference=ByteVectorType
package /Diagnostics/Persistency
  persistency file array Deamon_PersistencyFileArray: update-strategy=KEEP-EXISTING, uri=./etc/nv_data
  persistency file proxy interface PersistencyInterface: category=binary
  persistency port prototype to file array mapping PersistencyPortPrototypeToFileArrayMapping: persistency-file-array=Deamon_PersistencyFileArray, port-prototype=Application_basicIPC1_ExecutableRootSwc.Persistency, process=DiagnosticManagerDeamon
package /SelfDiagnosticAgent/Persistency
  persistency file array PersistencyFileArray_FileStorage: update-strategy=KEEP-EXISTING, uri=./etc/var
  persistency file proxy interface PersistencyInterface_FileSotrage_PRPort: category=text, update-strategy=KEEP-EXISTING, encoding=utf-8
  persistency key value database KeyValueStorage: update-strategy=KEEP-EXISTING, uri=./etc/var/kvs
  persistency key value database interface PersistencyInterface_PRPort: redundancy=NONE, update-strategy=DELETE, data-type-for-serialization=uint16_t
  persistency port prototype to file array mapping PersistencyPortProtToFileArrayMapping: persistency-file-array=PersistencyFileArray_FileStorage, port-prototype=SelfDiagnosticAgent_ExecutableRootSwc.prPortPrototype_FileStorage, process=SelfDiagnosticAgent_Process
  persistency port prototype to key value database mapping PersistencyPortProtToKeyValueDataBaseMapping: key-value-storage=KeyValueStorage, port-prototype=prPortPrototype_KeyValueStorage, process=SelfDiagnosticAgent_Process
